VERSION "dbc-export 1 2025.20.8"

NS_ :

BS_:

BU_: ADSP APB APP APS APSB BB BMS CC CMP CMPD CP DAS DI DIF DIR DPB EPAS3P EPAS3S EPASTP EPASTS EPBL EPBR ESP EVSE FC GTW HCML HCMR HVP IBST ICR IDB LS OCS1P PARK PCS PM PMF PMR PNCD PTC RADC RCM RCM2 RCM3 RCU SCCM SCM SCS SDCR TAS TCU TPMS TRCM UI UIS UMC USM VC VCFRONT VCLEFT VCRIGHT VCSEC VEH

BO_ 1297 RCM_alertLog: 8 RCM
 SG_ RCM_alertID M : 0|10@1+ (1,0) [0|1023] "" Vector__XXX
 SG_ RCM_a069_eventDriveOrientation m69 : 14|1@1+ (1,0) [0|1] "" Vector__XXX
 SG_ RCM_a069_comChassisCANPH7MIA m69 : 16|1@1+ (1,0) [0|1] "" Vector__XXX
 SG_ RCM_a069_comChassisCANPH7ChkSm m69 : 17|1@1+ (1,0) [0|1] "" Vector__XXX
 SG_ RCM_a069_comChassisCANPH7Cntr m69 : 18|1@1+ (1,0) [0|1] "" Vector__XXX
 SG_ RCM_a069_eventIDFsignal m69 : 25|1@1+ (1,0) [0|1] "" Vector__XXX
 SG_ RCM_a069_eventFrontLeftSeatbelt m69 : 26|1@1+ (1,0) [0|1] "" Vector__XXX
 SG_ RCM_a069_eventFrontRightSeatbelt m69 : 27|1@1+ (1,0) [0|1] "" Vector__XXX
 SG_ RCM_a069_eventVehicleSpeed m69 : 28|12@1+ (0.08,-40) [-40|287.6] "kph" Vector__XXX
 SG_ RCM_a069_eventSteeringAngle m69 : 45|14@0+ (0.1,-819.2) [-819.2|819.1] "deg" Vector__XXX
 SG_ RCM_a069_eventDriverBrakeApply m69 : 46|2@1+ (1,0) [0|2] "" Vector__XXX
 SG_ RCM_a069_eventAccelPedalPos m69 : 56|8@1+ (0.4,0) [0|101.6] "%" Vector__XXX
 SG_ RCM_a070_eventArmStatus m70 : 11|1@1+ (1,0) [0|1] "" Vector__XXX
 SG_ RCM_a070_eventFactoryMode m70 : 12|1@1+ (1,0) [0|1] "" Vector__XXX
 SG_ RCM_a070_eventDiagEnabled m70 : 13|1@1+ (1,0) [0|1] "" Vector__XXX
 SG_ RCM_a070_eventDriveOrientation m70 : 14|1@1+ (1,0) [0|1] "" Vector__XXX
 SG_ RCM_a070_comChassisCANPH8MIA m70 : 16|1@1+ (1,0) [0|1] "" Vector__XXX
 SG_ RCM_a070_comChassisCANPH8ChkSm m70 : 17|1@1+ (1,0) [0|1] "" Vector__XXX
 SG_ RCM_a070_comChassisCANPH8Cntr m70 : 18|1@1+ (1,0) [0|1] "" Vector__XXX
 SG_ RCM_a070_eventIDFsignal m70 : 25|1@1+ (1,0) [0|1] "" Vector__XXX
 SG_ RCM_a070_eventFrontLeftSeatbelt m70 : 26|1@1+ (1,0) [0|1] "" Vector__XXX
 SG_ RCM_a070_eventFrontRightSeatbelt m70 : 27|1@1+ (1,0) [0|1] "" Vector__XXX
 SG_ RCM_a070_eventVehicleSpeed m70 : 28|12@1+ (0.08,-40) [-40|287.6] "kph" Vector__XXX
 SG_ RCM_a070_eventSteeringAngle m70 : 45|14@0+ (0.1,-819.2) [-819.2|819.1] "deg" Vector__XXX
 SG_ RCM_a070_eventDriverBrakeApply m70 : 46|2@1+ (1,0) [0|2] "" Vector__XXX
 SG_ RCM_a070_eventAccelPedalPos m70 : 56|8@1+ (0.4,0) [0|101.6] "%" Vector__XXX
 SG_ RCM_a071_eventArmStatus m71 : 11|1@1+ (1,0) [0|1] "" Vector__XXX
 SG_ RCM_a071_eventFactoryMode m71 : 12|1@1+ (1,0) [0|1] "" Vector__XXX
 SG_ RCM_a071_eventDiagEnabled m71 : 13|1@1+ (1,0) [0|1] "" Vector__XXX
 SG_ RCM_a071_eventDriveOrientation m71 : 14|1@1+ (1,0) [0|1] "" Vector__XXX
 SG_ RCM_a071_comChassisCANPH9MIA m71 : 16|1@1+ (1,0) [0|1] "" Vector__XXX
 SG_ RCM_a071_comChassisCANPH9ChkSm m71 : 17|1@1+ (1,0) [0|1] "" Vector__XXX
 SG_ RCM_a071_comChassisCANPH9Cntr m71 : 18|1@1+ (1,0) [0|1] "" Vector__XXX
 SG_ RCM_a071_eventIDFsignal m71 : 25|1@1+ (1,0) [0|1] "" Vector__XXX
 SG_ RCM_a071_eventFrontLeftSeatbelt m71 : 26|1@1+ (1,0) [0|1] "" Vector__XXX
 SG_ RCM_a071_eventFrontRightSeatbelt m71 : 27|1@1+ (1,0) [0|1] "" Vector__XXX
 SG_ RCM_a071_eventVehicleSpeed m71 : 28|12@1+ (0.08,-40) [-40|287.6] "kph" Vector__XXX
 SG_ RCM_a071_eventSteeringAngle m71 : 45|14@0+ (0.1,-819.2) [-819.2|819.1] "deg" Vector__XXX
 SG_ RCM_a071_eventDriverBrakeApply m71 : 46|2@1+ (1,0) [0|2] "" Vector__XXX
 SG_ RCM_a071_eventAccelPedalPos m71 : 56|8@1+ (0.4,0) [0|101.6] "%" Vector__XXX
 SG_ RCM_a072_eventArmStatus m72 : 11|1@1+ (1,0) [0|1] "" Vector__XXX
 SG_ RCM_a072_eventFactoryMode m72 : 12|1@1+ (1,0) [0|1] "" Vector__XXX
 SG_ RCM_a072_eventDiagEnabled m72 : 13|1@1+ (1,0) [0|1] "" Vector__XXX
 SG_ RCM_a072_eventDriveOrientation m72 : 14|1@1+ (1,0) [0|1] "" Vector__XXX
 SG_ RCM_a072_comUnusedMIA m72 : 16|1@1+ (1,0) [0|1] "" Vector__XXX
 SG_ RCM_a072_comUnusedChkSm m72 : 17|1@1+ (1,0) [0|1] "" Vector__XXX
 SG_ RCM_a072_comUnusedCntr m72 : 18|1@1+ (1,0) [0|1] "" Vector__XXX
 SG_ RCM_a072_eventIDFsignal m72 : 25|1@1+ (1,0) [0|1] "" Vector__XXX
 SG_ RCM_a072_eventFrontLeftSeatbelt m72 : 26|1@1+ (1,0) [0|1] "" Vector__XXX
 SG_ RCM_a072_eventFrontRightSeatbelt m72 : 27|1@1+ (1,0) [0|1] "" Vector__XXX
 SG_ RCM_a072_eventVehicleSpeed m72 : 28|12@1+ (0.08,-40) [-40|287.6] "kph" Vector__XXX
 SG_ RCM_a072_eventSteeringAngle m72 : 45|14@0+ (0.1,-819.2) [-819.2|819.1] "deg" Vector__XXX
 SG_ RCM_a072_eventDriverBrakeApply m72 : 46|2@1+ (1,0) [0|2] "" Vector__XXX
 SG_ RCM_a072_eventAccelPedalPos m72 : 56|8@1+ (0.4,0) [0|101.6] "%" Vector__XXX
 SG_ RCM_a073_eventArmStatus m73 : 11|1@1+ (1,0) [0|1] "" Vector__XXX
 SG_ RCM_a073_eventFactoryMode m73 : 12|1@1+ (1,0) [0|1] "" Vector__XXX
 SG_ RCM_a073_eventDiagEnabled m73 : 13|1@1+ (1,0) [0|1] "" Vector__XXX
 SG_ RCM_a073_eventDriveOrientation m73 : 14|1@1+ (1,0) [0|1] "" Vector__XXX
 SG_ RCM_a073_comChassisCANPH4MIA m73 : 16|1@1+ (1,0) [0|1] "" Vector__XXX
 SG_ RCM_a073_comChassisCANPH4ChkSm m73 : 17|1@1+ (1,0) [0|1] "" Vector__XXX
 SG_ RCM_a073_comChassisCANPH4Cntr m73 : 18|1@1+ (1,0) [0|1] "" Vector__XXX
 SG_ RCM_a073_eventIDFsignal m73 : 25|1@1+ (1,0) [0|1] "" Vector__XXX
 SG_ RCM_a073_eventFrontLeftSeatbelt m73 : 26|1@1+ (1,0) [0|1] "" Vector__XXX
 SG_ RCM_a073_eventFrontRightSeatbelt m73 : 27|1@1+ (1,0) [0|1] "" Vector__XXX
 SG_ RCM_a073_eventVehicleSpeed m73 : 28|12@1+ (0.08,-40) [-40|287.6] "kph" Vector__XXX
 SG_ RCM_a073_eventSteeringAngle m73 : 45|14@0+ (0.1,-819.2) [-819.2|819.1] "deg" Vector__XXX
 SG_ RCM_a073_eventDriverBrakeApply m73 : 46|2@1+ (1,0) [0|2] "" Vector__XXX
 SG_ RCM_a073_eventAccelPedalPos m73 : 56|8@1+ (0.4,0) [0|101.6] "%" Vector__XXX
 SG_ RCM_a074_eventArmStatus m74 : 11|1@1+ (1,0) [0|1] "" Vector__XXX
 SG_ RCM_a074_eventFactoryMode m74 : 12|1@1+ (1,0) [0|1] "" Vector__XXX
 SG_ RCM_a074_eventDiagEnabled m74 : 13|1@1+ (1,0) [0|1] "" Vector__XXX
 SG_ RCM_a074_eventDriveOrientation m74 : 14|1@1+ (1,0) [0|1] "" Vector__XXX
 SG_ RCM_a074_comChassisCANPH5MIA m74 : 16|1@1+ (1,0) [0|1] "" Vector__XXX
 SG_ RCM_a074_comChassisCANPH5ChkSm m74 : 17|1@1+ (1,0) [0|1] "" Vector__XXX
 SG_ RCM_a074_comChassisCANPH5Cntr m74 : 18|1@1+ (1,0) [0|1] "" Vector__XXX
 SG_ RCM_a074_eventIDFsignal m74 : 25|1@1+ (1,0) [0|1] "" Vector__XXX
 SG_ RCM_a074_eventFrontLeftSeatbelt m74 : 26|1@1+ (1,0) [0|1] "" Vector__XXX
 SG_ RCM_a074_eventFrontRightSeatbelt m74 : 27|1@1+ (1,0) [0|1] "" Vector__XXX
 SG_ RCM_a074_eventVehicleSpeed m74 : 28|12@1+ (0.08,-40) [-40|287.6] "kph" Vector__XXX
 SG_ RCM_a074_eventSteeringAngle m74 : 45|14@0+ (0.1,-819.2) [-819.2|819.1] "deg" Vector__XXX
 SG_ RCM_a074_eventDriverBrakeApply m74 : 46|2@1+ (1,0) [0|2] "" Vector__XXX
 SG_ RCM_a074_eventAccelPedalPos m74 : 56|8@1+ (0.4,0) [0|101.6] "%" Vector__XXX
 SG_ RCM_a075_eventArmStatus m75 : 11|1@1+ (1,0) [0|1] "" Vector__XXX
 SG_ RCM_a075_eventFactoryMode m75 : 12|1@1+ (1,0) [0|1] "" Vector__XXX
 SG_ RCM_a075_eventDiagEnabled m75 : 13|1@1+ (1,0) [0|1] "" Vector__XXX
 SG_ RCM_a075_eventDriveOrientation m75 : 14|1@1+ (1,0) [0|1] "" Vector__XXX
 SG_ RCM_a075_comChassisCANPH6MIA m75 : 16|1@1+ (1,0) [0|1] "" Vector__XXX
 SG_ RCM_a075_comChassisCANPH6ChkSm m75 : 17|1@1+ (1,0) [0|1] "" Vector__XXX
 SG_ RCM_a075_comChassisCANPH6Cntr m75 : 18|1@1+ (1,0) [0|1] "" Vector__XXX
 SG_ RCM_a075_eventIDFsignal m75 : 25|1@1+ (1,0) [0|1] "" Vector__XXX
 SG_ RCM_a075_eventFrontLeftSeatbelt m75 : 26|1@1+ (1,0) [0|1] "" Vector__XXX
 SG_ RCM_a075_eventFrontRightSeatbelt m75 : 27|1@1+ (1,0) [0|1] "" Vector__XXX
 SG_ RCM_a075_eventVehicleSpeed m75 : 28|12@1+ (0.08,-40) [-40|287.6] "kph" Vector__XXX
 SG_ RCM_a075_eventSteeringAngle m75 : 45|14@0+ (0.1,-819.2) [-819.2|819.1] "deg" Vector__XXX
 SG_ RCM_a075_eventDriverBrakeApply m75 : 46|2@1+ (1,0) [0|2] "" Vector__XXX
 SG_ RCM_a075_eventAccelPedalPos m75 : 56|8@1+ (0.4,0) [0|101.6] "%" Vector__XXX
 SG_ RCM_a078_eventArmStatus m78 : 11|1@1+ (1,0) [0|1] "" Vector__XXX
 SG_ RCM_a078_eventFactoryMode m78 : 12|1@1+ (1,0) [0|1] "" Vector__XXX
 SG_ RCM_a078_eventDiagEnabled m78 : 13|1@1+ (1,0) [0|1] "" Vector__XXX
 SG_ RCM_a078_eventDriveOrientation m78 : 14|1@1+ (1,0) [0|1] "" Vector__XXX
 SG_ RCM_a078_comOCS1PMIA m78 : 16|1@1+ (1,0) [0|1] "" Vector__XXX
 SG_ RCM_a078_comOCS1PChkSm m78 : 17|1@1+ (1,0) [0|1] "" Vector__XXX
 SG_ RCM_a078_comOCS1PCntr m78 : 18|1@1+ (1,0) [0|1] "" Vector__XXX
 SG_ RCM_a078_eventIDFsignal m78 : 25|1@1+ (1,0) [0|1] "" Vector__XXX
 SG_ RCM_a078_eventFrontLeftSeatbelt m78 : 26|1@1+ (1,0) [0|1] "" Vector__XXX
 SG_ RCM_a078_eventFrontRightSeatbelt m78 : 27|1@1+ (1,0) [0|1] "" Vector__XXX
 SG_ RCM_a078_eventVehicleSpeed m78 : 28|12@1+ (0.08,-40) [-40|287.6] "kph" Vector__XXX
 SG_ RCM_a078_eventSteeringAngle m78 : 45|14@0+ (0.1,-819.2) [-819.2|819.1] "deg" Vector__XXX
 SG_ RCM_a078_eventDriverBrakeApply m78 : 46|2@1+ (1,0) [0|2] "" Vector__XXX
 SG_ RCM_a078_eventAccelPedalPos m78 : 56|8@1+ (0.4,0) [0|101.6] "%" Vector__XXX
 SG_ RCM_a079_eventArmStatus m79 : 11|1@1+ (1,0) [0|1] "" Vector__XXX
 SG_ RCM_a079_eventFactoryMode m79 : 12|1@1+ (1,0) [0|1] "" Vector__XXX
 SG_ RCM_a079_eventDiagEnabled m79 : 13|1@1+ (1,0) [0|1] "" Vector__XXX
 SG_ RCM_a079_eventDriveOrientation m79 : 14|1@1+ (1,0) [0|1] "" Vector__XXX
 SG_ RCM_a079_comOCS1DMIA m79 : 16|1@1+ (1,0) [0|1] "" Vector__XXX
 SG_ RCM_a079_comOCS1DChkSm m79 : 17|1@1+ (1,0) [0|1] "" Vector__XXX
 SG_ RCM_a079_comOCS1DCntr m79 : 18|1@1+ (1,0) [0|1] "" Vector__XXX
 SG_ RCM_a079_eventIDFsignal m79 : 25|1@1+ (1,0) [0|1] "" Vector__XXX
 SG_ RCM_a079_eventFrontLeftSeatbelt m79 : 26|1@1+ (1,0) [0|1] "" Vector__XXX
 SG_ RCM_a079_eventFrontRightSeatbelt m79 : 27|1@1+ (1,0) [0|1] "" Vector__XXX
 SG_ RCM_a079_eventVehicleSpeed m79 : 28|12@1+ (0.08,-40) [-40|287.6] "kph" Vector__XXX
 SG_ RCM_a079_eventSteeringAngle m79 : 45|14@0+ (0.1,-819.2) [-819.2|819.1] "deg" Vector__XXX
 SG_ RCM_a079_eventDriverBrakeApply m79 : 46|2@1+ (1,0) [0|2] "" Vector__XXX
 SG_ RCM_a079_eventAccelPedalPos m79 : 56|8@1+ (0.4,0) [0|101.6] "%" Vector__XXX
 SG_ RCM_a080_eventArmStatus m80 : 11|1@1+ (1,0) [0|1] "" Vector__XXX
 SG_ RCM_a080_eventFactoryMode m80 : 12|1@1+ (1,0) [0|1] "" Vector__XXX
 SG_ RCM_a080_eventDiagEnabled m80 : 13|1@1+ (1,0) [0|1] "" Vector__XXX
 SG_ RCM_a080_eventDriveOrientation m80 : 14|1@1+ (1,0) [0|1] "" Vector__XXX
 SG_ RCM_a080_comGTWACSMIA m80 : 16|1@1+ (1,0) [0|1] "" Vector__XXX
 SG_ RCM_a080_comGTWACSChkSm m80 : 17|1@1+ (1,0) [0|1] "" Vector__XXX
 SG_ RCM_a080_comGTWACSCntr m80 : 18|1@1+ (1,0) [0|1] "" Vector__XXX
 SG_ RCM_a080_eventIDFsignal m80 : 25|1@1+ (1,0) [0|1] "" Vector__XXX
 SG_ RCM_a080_eventFrontLeftSeatbelt m80 : 26|1@1+ (1,0) [0|1] "" Vector__XXX
 SG_ RCM_a080_eventFrontRightSeatbelt m80 : 27|1@1+ (1,0) [0|1] "" Vector__XXX
 SG_ RCM_a080_eventVehicleSpeed m80 : 28|12@1+ (0.08,-40) [-40|287.6] "kph" Vector__XXX
 SG_ RCM_a080_eventSteeringAngle m80 : 45|14@0+ (0.1,-819.2) [-819.2|819.1] "deg" Vector__XXX
 SG_ RCM_a080_eventDriverBrakeApply m80 : 46|2@1+ (1,0) [0|2] "" Vector__XXX
 SG_ RCM_a080_eventAccelPedalPos m80 : 56|8@1+ (0.4,0) [0|101.6] "%" Vector__XXX
 SG_ RCM_a083_eventArmStatus m83 : 11|1@1+ (1,0) [0|1] "" Vector__XXX
 SG_ RCM_a083_eventFactoryMode m83 : 12|1@1+ (1,0) [0|1] "" Vector__XXX
 SG_ RCM_a083_eventDiagEnabled m83 : 13|1@1+ (1,0) [0|1] "" Vector__XXX
 SG_ RCM_a083_eventDriveOrientation m83 : 14|1@1+ (1,0) [0|1] "" Vector__XXX
 SG_ RCM_a083_comGTWCarStateMIA m83 : 16|1@1+ (1,0) [0|1] "" Vector__XXX
 SG_ RCM_a083_eventIDFsignal m83 : 25|1@1+ (1,0) [0|1] "" Vector__XXX
 SG_ RCM_a083_eventFrontLeftSeatbelt m83 : 26|1@1+ (1,0) [0|1] "" Vector__XXX
 SG_ RCM_a083_eventFrontRightSeatbelt m83 : 27|1@1+ (1,0) [0|1] "" Vector__XXX
 SG_ RCM_a083_eventVehicleSpeed m83 : 28|12@1+ (0.08,-40) [-40|287.6] "kph" Vector__XXX
 SG_ RCM_a083_eventSteeringAngle m83 : 45|14@0+ (0.1,-819.2) [-819.2|819.1] "deg" Vector__XXX
 SG_ RCM_a083_eventDriverBrakeApply m83 : 46|2@1+ (1,0) [0|2] "" Vector__XXX
 SG_ RCM_a083_eventAccelPedalPos m83 : 56|8@1+ (0.4,0) [0|101.6] "%" Vector__XXX
 SG_ RCM_a087_eventArmStatus m87 : 11|1@1+ (1,0) [0|1] "" Vector__XXX
 SG_ RCM_a087_eventFactoryMode m87 : 12|1@1+ (1,0) [0|1] "" Vector__XXX
 SG_ RCM_a087_eventDiagEnabled m87 : 13|1@1+ (1,0) [0|1] "" Vector__XXX
 SG_ RCM_a087_eventDriveOrientation m87 : 14|1@1+ (1,0) [0|1] "" Vector__XXX
 SG_ RCM_a087_comChassisCANSilent m87 : 16|1@1+ (1,0) [0|1] "" Vector__XXX
 SG_ RCM_a087_comPARTYCANSilent m87 : 17|1@1+ (1,0) [0|1] "" Vector__XXX
 SG_ RCM_a087_comUnusedCANSilent m87 : 18|1@1+ (1,0) [0|1] "" Vector__XXX
 SG_ RCM_a087_eventIDFsignal m87 : 25|1@1+ (1,0) [0|1] "" Vector__XXX
 SG_ RCM_a087_eventFrontLeftSeatbelt m87 : 26|1@1+ (1,0) [0|1] "" Vector__XXX
 SG_ RCM_a087_eventFrontRightSeatbelt m87 : 27|1@1+ (1,0) [0|1] "" Vector__XXX
 SG_ RCM_a087_eventVehicleSpeed m87 : 28|12@1+ (0.08,-40) [-40|287.6] "kph" Vector__XXX
 SG_ RCM_a087_eventSteeringAngle m87 : 45|14@0+ (0.1,-819.2) [-819.2|819.1] "deg" Vector__XXX
 SG_ RCM_a087_eventDriverBrakeApply m87 : 46|2@1+ (1,0) [0|2] "" Vector__XXX
 SG_ RCM_a087_eventAccelPedalPos m87 : 56|8@1+ (0.4,0) [0|101.6] "%" Vector__XXX
 SG_ RCM_a088_eventArmStatus m88 : 11|1@1+ (1,0) [0|1] "" Vector__XXX
 SG_ RCM_a088_eventFactoryMode m88 : 12|1@1+ (1,0) [0|1] "" Vector__XXX
 SG_ RCM_a088_eventDiagEnabled m88 : 13|1@1+ (1,0) [0|1] "" Vector__XXX
 SG_ RCM_a088_eventDriveOrientation m88 : 14|1@1+ (1,0) [0|1] "" Vector__XXX
 SG_ RCM_a088_comChassisCANPH2MIA m88 : 16|1@1+ (1,0) [0|1] "" Vector__XXX
 SG_ RCM_a088_comChassisCANPH2ChkSm m88 : 17|1@1+ (1,0) [0|1] "" Vector__XXX
 SG_ RCM_a088_comChassisCANPH2Cntr m88 : 18|1@1+ (1,0) [0|1] "" Vector__XXX
 SG_ RCM_a088_eventIDFsignal m88 : 25|1@1+ (1,0) [0|1] "" Vector__XXX
 SG_ RCM_a088_eventFrontLeftSeatbelt m88 : 26|1@1+ (1,0) [0|1] "" Vector__XXX
 SG_ RCM_a088_eventFrontRightSeatbelt m88 : 27|1@1+ (1,0) [0|1] "" Vector__XXX
 SG_ RCM_a088_eventVehicleSpeed m88 : 28|12@1+ (0.08,-40) [-40|287.6] "kph" Vector__XXX
 SG_ RCM_a088_eventSteeringAngle m88 : 45|14@0+ (0.1,-819.2) [-819.2|819.1] "deg" Vector__XXX
 SG_ RCM_a088_eventDriverBrakeApply m88 : 46|2@1+ (1,0) [0|2] "" Vector__XXX
 SG_ RCM_a088_eventAccelPedalPos m88 : 56|8@1+ (0.4,0) [0|101.6] "%" Vector__XXX
 SG_ RCM_a089_eventArmStatus m89 : 11|1@1+ (1,0) [0|1] "" Vector__XXX
 SG_ RCM_a089_eventFactoryMode m89 : 12|1@1+ (1,0) [0|1] "" Vector__XXX
 SG_ RCM_a089_eventDiagEnabled m89 : 13|1@1+ (1,0) [0|1] "" Vector__XXX
 SG_ RCM_a089_eventDriveOrientation m89 : 14|1@1+ (1,0) [0|1] "" Vector__XXX
 SG_ RCM_a089_comChassisCANPH3MIA m89 : 16|1@1+ (1,0) [0|1] "" Vector__XXX
 SG_ RCM_a089_comChassisCANPH3ChkSm m89 : 17|1@1+ (1,0) [0|1] "" Vector__XXX
 SG_ RCM_a089_comChassisCANPH3Cntr m89 : 18|1@1+ (1,0) [0|1] "" Vector__XXX
 SG_ RCM_a089_eventIDFsignal m89 : 25|1@1+ (1,0) [0|1] "" Vector__XXX
 SG_ RCM_a089_eventFrontLeftSeatbelt m89 : 26|1@1+ (1,0) [0|1] "" Vector__XXX
 SG_ RCM_a089_eventFrontRightSeatbelt m89 : 27|1@1+ (1,0) [0|1] "" Vector__XXX
 SG_ RCM_a089_eventVehicleSpeed m89 : 28|12@1+ (0.08,-40) [-40|287.6] "kph" Vector__XXX
 SG_ RCM_a089_eventSteeringAngle m89 : 45|14@0+ (0.1,-819.2) [-819.2|819.1] "deg" Vector__XXX
 SG_ RCM_a089_eventDriverBrakeApply m89 : 46|2@1+ (1,0) [0|2] "" Vector__XXX
 SG_ RCM_a089_eventAccelPedalPos m89 : 56|8@1+ (0.4,0) [0|101.6] "%" Vector__XXX
 SG_ RCM_a090_eventArmStatus m90 : 11|1@1+ (1,0) [0|1] "" Vector__XXX
 SG_ RCM_a090_eventFactoryMode m90 : 12|1@1+ (1,0) [0|1] "" Vector__XXX
 SG_ RCM_a090_eventDiagEnabled m90 : 13|1@1+ (1,0) [0|1] "" Vector__XXX
 SG_ RCM_a090_eventDriveOrientation m90 : 14|1@1+ (1,0) [0|1] "" Vector__XXX
 SG_ RCM_a090_comPartyCANBusOff m90 : 16|1@1+ (1,0) [0|1] "" Vector__XXX
 SG_ RCM_a090_eventIDFsignal m90 : 25|1@1+ (1,0) [0|1] "" Vector__XXX
 SG_ RCM_a090_eventFrontLeftSeatbelt m90 : 26|1@1+ (1,0) [0|1] "" Vector__XXX
 SG_ RCM_a090_eventFrontRightSeatbelt m90 : 27|1@1+ (1,0) [0|1] "" Vector__XXX
 SG_ RCM_a090_eventVehicleSpeed m90 : 28|12@1+ (0.08,-40) [-40|287.6] "kph" Vector__XXX
 SG_ RCM_a090_eventSteeringAngle m90 : 45|14@0+ (0.1,-819.2) [-819.2|819.1] "deg" Vector__XXX
 SG_ RCM_a090_eventDriverBrakeApply m90 : 46|2@1+ (1,0) [0|2] "" Vector__XXX
 SG_ RCM_a090_eventAccelPedalPos m90 : 56|8@1+ (0.4,0) [0|101.6] "%" Vector__XXX
 SG_ RCM_a091_eventArmStatus m91 : 11|1@1+ (1,0) [0|1] "" Vector__XXX
 SG_ RCM_a091_eventFactoryMode m91 : 12|1@1+ (1,0) [0|1] "" Vector__XXX
 SG_ RCM_a091_eventDiagEnabled m91 : 13|1@1+ (1,0) [0|1] "" Vector__XXX
 SG_ RCM_a091_eventDriveOrientation m91 : 14|1@1+ (1,0) [0|1] "" Vector__XXX
 SG_ RCM_a091_comEPAS3PStAnglInvlidQF m91 : 16|1@1+ (1,0) [0|1] "" Vector__XXX
 SG_ RCM_a091_comEPAS3PsysStatusMIA m91 : 17|1@1+ (1,0) [0|1] "" Vector__XXX
 SG_ RCM_a091_comEPAS3PsysStatusChkSm m91 : 18|1@1+ (1,0) [0|1] "" Vector__XXX
 SG_ RCM_a091_comEPAS3PsysStatusCntr m91 : 19|1@1+ (1,0) [0|1] "" Vector__XXX
 SG_ RCM_a091_eventIDFsignal m91 : 25|1@1+ (1,0) [0|1] "" Vector__XXX
 SG_ RCM_a091_eventFrontLeftSeatbelt m91 : 26|1@1+ (1,0) [0|1] "" Vector__XXX
 SG_ RCM_a091_eventFrontRightSeatbelt m91 : 27|1@1+ (1,0) [0|1] "" Vector__XXX
 SG_ RCM_a091_eventVehicleSpeed m91 : 28|12@1+ (0.08,-40) [-40|287.6] "kph" Vector__XXX
 SG_ RCM_a091_eventSteeringAngle m91 : 45|14@0+ (0.1,-819.2) [-819.2|819.1] "deg" Vector__XXX
 SG_ RCM_a091_eventDriverBrakeApply m91 : 46|2@1+ (1,0) [0|2] "" Vector__XXX
 SG_ RCM_a091_eventAccelPedalPos m91 : 56|8@1+ (0.4,0) [0|101.6] "%" Vector__XXX
 SG_ RCM_a092_eventArmStatus m92 : 11|1@1+ (1,0) [0|1] "" Vector__XXX
 SG_ RCM_a092_eventFactoryMode m92 : 12|1@1+ (1,0) [0|1] "" Vector__XXX
 SG_ RCM_a092_eventDiagEnabled m92 : 13|1@1+ (1,0) [0|1] "" Vector__XXX
 SG_ RCM_a092_eventDriveOrientation m92 : 14|1@1+ (1,0) [0|1] "" Vector__XXX
 SG_ RCM_a092_comDASSafetyFrontMIA m92 : 16|1@1+ (1,0) [0|1] "" Vector__XXX
 SG_ RCM_a092_comDASSafetyFrontChkSm m92 : 17|1@1+ (1,0) [0|1] "" Vector__XXX
 SG_ RCM_a092_comDASSafetyFrontCntr m92 : 18|1@1+ (1,0) [0|1] "" Vector__XXX
 SG_ RCM_a092_eventIDFsignal m92 : 25|1@1+ (1,0) [0|1] "" Vector__XXX
 SG_ RCM_a092_eventFrontLeftSeatbelt m92 : 26|1@1+ (1,0) [0|1] "" Vector__XXX
 SG_ RCM_a092_eventFrontRightSeatbelt m92 : 27|1@1+ (1,0) [0|1] "" Vector__XXX
 SG_ RCM_a092_eventVehicleSpeed m92 : 28|12@1+ (0.08,-40) [-40|287.6] "kph" Vector__XXX
 SG_ RCM_a092_eventSteeringAngle m92 : 45|14@0+ (0.1,-819.2) [-819.2|819.1] "deg" Vector__XXX
 SG_ RCM_a092_eventDriverBrakeApply m92 : 46|2@1+ (1,0) [0|2] "" Vector__XXX
 SG_ RCM_a092_eventAccelPedalPos m92 : 56|8@1+ (0.4,0) [0|101.6] "%" Vector__XXX
 SG_ RCM_a093_eventArmStatus m93 : 11|1@1+ (1,0) [0|1] "" Vector__XXX
 SG_ RCM_a093_eventFactoryMode m93 : 12|1@1+ (1,0) [0|1] "" Vector__XXX
 SG_ RCM_a093_eventDiagEnabled m93 : 13|1@1+ (1,0) [0|1] "" Vector__XXX
 SG_ RCM_a093_eventDriveOrientation m93 : 14|1@1+ (1,0) [0|1] "" Vector__XXX
 SG_ RCM_a093_comVCLEFTStatusMIA m93 : 16|1@1+ (1,0) [0|1] "" Vector__XXX
 SG_ RCM_a093_comVCLEFTStatusChkSm m93 : 17|1@1+ (1,0) [0|1] "" Vector__XXX
 SG_ RCM_a093_comVCLEFTStatusCntr m93 : 18|1@1+ (1,0) [0|1] "" Vector__XXX
 SG_ RCM_a093_bucklSwVCFrontLeftFault m93 : 19|1@1+ (1,0) [0|1] "" Vector__XXX
 SG_ RCM_a093_bucklSwVCRearLeftFault m93 : 20|1@1+ (1,0) [0|1] "" Vector__XXX
 SG_ RCM_a093_eventIDFsignal m93 : 25|1@1+ (1,0) [0|1] "" Vector__XXX
 SG_ RCM_a093_eventFrontLeftSeatbelt m93 : 26|1@1+ (1,0) [0|1] "" Vector__XXX
 SG_ RCM_a093_eventFrontRightSeatbelt m93 : 27|1@1+ (1,0) [0|1] "" Vector__XXX
 SG_ RCM_a093_eventVehicleSpeed m93 : 28|12@1+ (0.08,-40) [-40|287.6] "kph" Vector__XXX
 SG_ RCM_a093_eventSteeringAngle m93 : 45|14@0+ (0.1,-819.2) [-819.2|819.1] "deg" Vector__XXX
 SG_ RCM_a093_eventDriverBrakeApply m93 : 46|2@1+ (1,0) [0|2] "" Vector__XXX
 SG_ RCM_a093_eventAccelPedalPos m93 : 56|8@1+ (0.4,0) [0|101.6] "%" Vector__XXX
 SG_ RCM_a094_eventArmStatus m94 : 11|1@1+ (1,0) [0|1] "" Vector__XXX
 SG_ RCM_a094_eventFactoryMode m94 : 12|1@1+ (1,0) [0|1] "" Vector__XXX
 SG_ RCM_a094_eventDiagEnabled m94 : 13|1@1+ (1,0) [0|1] "" Vector__XXX
 SG_ RCM_a094_eventDriveOrientation m94 : 14|1@1+ (1,0) [0|1] "" Vector__XXX
 SG_ RCM_a094_comVCRIGHTStatusMIA m94 : 16|1@1+ (1,0) [0|1] "" Vector__XXX
 SG_ RCM_a094_comVCRIGHTStatusChkSm m94 : 17|1@1+ (1,0) [0|1] "" Vector__XXX
 SG_ RCM_a094_comVCRIGHTStatusCntr m94 : 18|1@1+ (1,0) [0|1] "" Vector__XXX
 SG_ RCM_a094_bucklSwVCFrontRghtFault m94 : 19|1@1+ (1,0) [0|1] "" Vector__XXX
 SG_ RCM_a094_bucklSwVCRearRghtFault m94 : 20|1@1+ (1,0) [0|1] "" Vector__XXX
 SG_ RCM_a094_bucklSwVCRearCnterFault m94 : 21|1@1+ (1,0) [0|1] "" Vector__XXX
 SG_ RCM_a094_eventIDFsignal m94 : 25|1@1+ (1,0) [0|1] "" Vector__XXX
 SG_ RCM_a094_eventFrontLeftSeatbelt m94 : 26|1@1+ (1,0) [0|1] "" Vector__XXX
 SG_ RCM_a094_eventFrontRightSeatbelt m94 : 27|1@1+ (1,0) [0|1] "" Vector__XXX
 SG_ RCM_a094_eventVehicleSpeed m94 : 28|12@1+ (0.08,-40) [-40|287.6] "kph" Vector__XXX
 SG_ RCM_a094_eventSteeringAngle m94 : 45|14@0+ (0.1,-819.2) [-819.2|819.1] "deg" Vector__XXX
 SG_ RCM_a094_eventDriverBrakeApply m94 : 46|2@1+ (1,0) [0|2] "" Vector__XXX
 SG_ RCM_a094_eventAccelPedalPos m94 : 56|8@1+ (0.4,0) [0|101.6] "%" Vector__XXX
 SG_ RCM_a101_eventArmStatus m101 : 11|1@1+ (1,0) [0|1] "" Vector__XXX
 SG_ RCM_a101_eventFactoryMode m101 : 12|1@1+ (1,0) [0|1] "" Vector__XXX
 SG_ RCM_a101_eventDiagEnabled m101 : 13|1@1+ (1,0) [0|1] "" Vector__XXX
 SG_ RCM_a101_eventDriveOrientation m101 : 14|1@1+ (1,0) [0|1] "" Vector__XXX
 SG_ RCM_a101_idfMisuseMonitoringErr m101 : 16|1@1+ (1,0) [0|1] "" Vector__XXX
 SG_ RCM_a101_idfEnviMonitoringError m101 : 17|1@1+ (1,0) [0|1] "" Vector__XXX
 SG_ RCM_a101_idfEnviMonitoringEvent m101 : 18|1@1+ (1,0) [0|1] "" Vector__XXX
 SG_ RCM_a101_eventIDFsignal m101 : 25|1@1+ (1,0) [0|1] "" Vector__XXX
 SG_ RCM_a101_eventFrontLeftSeatbelt m101 : 26|1@1+ (1,0) [0|1] "" Vector__XXX
 SG_ RCM_a101_eventFrontRightSeatbelt m101 : 27|1@1+ (1,0) [0|1] "" Vector__XXX
 SG_ RCM_a101_eventVehicleSpeed m101 : 28|12@1+ (0.08,-40) [-40|287.6] "kph" Vector__XXX
 SG_ RCM_a101_eventSteeringAngle m101 : 45|14@0+ (0.1,-819.2) [-819.2|819.1] "deg" Vector__XXX
 SG_ RCM_a101_eventDriverBrakeApply m101 : 46|2@1+ (1,0) [0|2] "" Vector__XXX
 SG_ RCM_a101_eventAccelPedalPos m101 : 56|8@1+ (0.4,0) [0|101.6] "%" Vector__XXX
 SG_ RCM_a102_eventArmStatus m102 : 11|1@1+ (1,0) [0|1] "" Vector__XXX
 SG_ RCM_a102_eventFactoryMode m102 : 12|1@1+ (1,0) [0|1] "" Vector__XXX
 SG_ RCM_a102_eventDiagEnabled m102 : 13|1@1+ (1,0) [0|1] "" Vector__XXX
 SG_ RCM_a102_eventDriveOrientation m102 : 14|1@1+ (1,0) [0|1] "" Vector__XXX
 SG_ RCM_a102_imuYawR8OffCompPosLife m102 : 16|1@1+ (1,0) [0|1] "" Vector__XXX
 SG_ RCM_a102_imuYawR8OffCompNegLife m102 : 17|1@1+ (1,0) [0|1] "" Vector__XXX
 SG_ RCM_a102_imuYawR8OffCompPosFLDC m102 : 18|1@1+ (1,0) [0|1] "" Vector__XXX
 SG_ RCM_a102_imuYawR8OffCompNegFLDC m102 : 19|1@1+ (1,0) [0|1] "" Vector__XXX
 SG_ RCM_a102_imuYawR8OffCompPosSLDC m102 : 20|1@1+ (1,0) [0|1] "" Vector__XXX
 SG_ RCM_a102_imuYawR8OffCompNegSLDC m102 : 21|1@1+ (1,0) [0|1] "" Vector__XXX
 SG_ RCM_a102_eventIDFsignal m102 : 25|1@1+ (1,0) [0|1] "" Vector__XXX
 SG_ RCM_a102_eventFrontLeftSeatbelt m102 : 26|1@1+ (1,0) [0|1] "" Vector__XXX
 SG_ RCM_a102_eventFrontRightSeatbelt m102 : 27|1@1+ (1,0) [0|1] "" Vector__XXX
 SG_ RCM_a102_eventVehicleSpeed m102 : 28|12@1+ (0.08,-40) [-40|287.6] "kph" Vector__XXX
 SG_ RCM_a102_eventSteeringAngle m102 : 45|14@0+ (0.1,-819.2) [-819.2|819.1] "deg" Vector__XXX
 SG_ RCM_a102_eventDriverBrakeApply m102 : 46|2@1+ (1,0) [0|2] "" Vector__XXX
 SG_ RCM_a102_eventAccelPedalPos m102 : 56|8@1+ (0.4,0) [0|101.6] "%" Vector__XXX
 SG_ RCM_a103_eventArmStatus m103 : 11|1@1+ (1,0) [0|1] "" Vector__XXX
 SG_ RCM_a103_eventFactoryMode m103 : 12|1@1+ (1,0) [0|1] "" Vector__XXX
 SG_ RCM_a103_eventDiagEnabled m103 : 13|1@1+ (1,0) [0|1] "" Vector__XXX
 SG_ RCM_a103_eventDriveOrientation m103 : 14|1@1+ (1,0) [0|1] "" Vector__XXX
 SG_ RCM_a103_imuPtchR8OffCompPosLife m103 : 16|1@1+ (1,0) [0|1] "" Vector__XXX
 SG_ RCM_a103_imuPtchR8OffCompNegLife m103 : 17|1@1+ (1,0) [0|1] "" Vector__XXX
 SG_ RCM_a103_imuPtchR8OffCompPosFLDC m103 : 18|1@1+ (1,0) [0|1] "" Vector__XXX
 SG_ RCM_a103_imuPtchR8OffCompNegFLDC m103 : 19|1@1+ (1,0) [0|1] "" Vector__XXX
 SG_ RCM_a103_imuPtchR8OffCompPosSLDC m103 : 20|1@1+ (1,0) [0|1] "" Vector__XXX
 SG_ RCM_a103_imuPtchR8OffCompNegSLDC m103 : 21|1@1+ (1,0) [0|1] "" Vector__XXX
 SG_ RCM_a103_eventIDFsignal m103 : 25|1@1+ (1,0) [0|1] "" Vector__XXX
 SG_ RCM_a103_eventFrontLeftSeatbelt m103 : 26|1@1+ (1,0) [0|1] "" Vector__XXX
 SG_ RCM_a103_eventFrontRightSeatbelt m103 : 27|1@1+ (1,0) [0|1] "" Vector__XXX
 SG_ RCM_a103_eventVehicleSpeed m103 : 28|12@1+ (0.08,-40) [-40|287.6] "kph" Vector__XXX
 SG_ RCM_a103_eventSteeringAngle m103 : 45|14@0+ (0.1,-819.2) [-819.2|819.1] "deg" Vector__XXX
 SG_ RCM_a103_eventDriverBrakeApply m103 : 46|2@1+ (1,0) [0|2] "" Vector__XXX
 SG_ RCM_a103_eventAccelPedalPos m103 : 56|8@1+ (0.4,0) [0|101.6] "%" Vector__XXX
 SG_ RCM_a104_eventArmStatus m104 : 11|1@1+ (1,0) [0|1] "" Vector__XXX
 SG_ RCM_a104_eventFactoryMode m104 : 12|1@1+ (1,0) [0|1] "" Vector__XXX
 SG_ RCM_a104_eventDiagEnabled m104 : 13|1@1+ (1,0) [0|1] "" Vector__XXX
 SG_ RCM_a104_eventDriveOrientation m104 : 14|1@1+ (1,0) [0|1] "" Vector__XXX
 SG_ RCM_a104_imuRollR8OffCompPosLife m104 : 16|1@1+ (1,0) [0|1] "" Vector__XXX
 SG_ RCM_a104_imuRollR8OffCompNegLife m104 : 17|1@1+ (1,0) [0|1] "" Vector__XXX
 SG_ RCM_a104_imuRollR8OffCompPosFLDC m104 : 18|1@1+ (1,0) [0|1] "" Vector__XXX
 SG_ RCM_a104_imuRollR8OffCompNegFLDC m104 : 19|1@1+ (1,0) [0|1] "" Vector__XXX
 SG_ RCM_a104_imuRollR8OffCompPosSLDC m104 : 20|1@1+ (1,0) [0|1] "" Vector__XXX
 SG_ RCM_a104_imuRollR8OffCompNegSLDC m104 : 21|1@1+ (1,0) [0|1] "" Vector__XXX
 SG_ RCM_a104_eventIDFsignal m104 : 25|1@1+ (1,0) [0|1] "" Vector__XXX
 SG_ RCM_a104_eventFrontLeftSeatbelt m104 : 26|1@1+ (1,0) [0|1] "" Vector__XXX
 SG_ RCM_a104_eventFrontRightSeatbelt m104 : 27|1@1+ (1,0) [0|1] "" Vector__XXX
 SG_ RCM_a104_eventVehicleSpeed m104 : 28|12@1+ (0.08,-40) [-40|287.6] "kph" Vector__XXX
 SG_ RCM_a104_eventSteeringAngle m104 : 45|14@0+ (0.1,-819.2) [-819.2|819.1] "deg" Vector__XXX
 SG_ RCM_a104_eventDriverBrakeApply m104 : 46|2@1+ (1,0) [0|2] "" Vector__XXX
 SG_ RCM_a104_eventAccelPedalPos m104 : 56|8@1+ (0.4,0) [0|101.6] "%" Vector__XXX
 SG_ RCM_a105_eventArmStatus m105 : 11|1@1+ (1,0) [0|1] "" Vector__XXX
 SG_ RCM_a105_eventFactoryMode m105 : 12|1@1+ (1,0) [0|1] "" Vector__XXX
 SG_ RCM_a105_eventDiagEnabled m105 : 13|1@1+ (1,0) [0|1] "" Vector__XXX
 SG_ RCM_a105_eventDriveOrientation m105 : 14|1@1+ (1,0) [0|1] "" Vector__XXX
 SG_ RCM_a105_imuLongAOffCompPosLife m105 : 16|1@1+ (1,0) [0|1] "" Vector__XXX
 SG_ RCM_a105_imuLongAOffCompNegLife m105 : 17|1@1+ (1,0) [0|1] "" Vector__XXX
 SG_ RCM_a105_imuLongAOffCompPosFLDC m105 : 18|1@1+ (1,0) [0|1] "" Vector__XXX
 SG_ RCM_a105_imuLongAOffCompNegFLDC m105 : 19|1@1+ (1,0) [0|1] "" Vector__XXX
 SG_ RCM_a105_imuLongAOffCompPosSLDC m105 : 20|1@1+ (1,0) [0|1] "" Vector__XXX
 SG_ RCM_a105_imuLongAOffCompNegSLDC m105 : 21|1@1+ (1,0) [0|1] "" Vector__XXX
 SG_ RCM_a105_eventIDFsignal m105 : 25|1@1+ (1,0) [0|1] "" Vector__XXX
 SG_ RCM_a105_eventFrontLeftSeatbelt m105 : 26|1@1+ (1,0) [0|1] "" Vector__XXX
 SG_ RCM_a105_eventFrontRightSeatbelt m105 : 27|1@1+ (1,0) [0|1] "" Vector__XXX
 SG_ RCM_a105_eventVehicleSpeed m105 : 28|12@1+ (0.08,-40) [-40|287.6] "kph" Vector__XXX
 SG_ RCM_a105_eventSteeringAngle m105 : 45|14@0+ (0.1,-819.2) [-819.2|819.1] "deg" Vector__XXX
 SG_ RCM_a105_eventDriverBrakeApply m105 : 46|2@1+ (1,0) [0|2] "" Vector__XXX
 SG_ RCM_a105_eventAccelPedalPos m105 : 56|8@1+ (0.4,0) [0|101.6] "%" Vector__XXX
 SG_ RCM_a106_eventArmStatus m106 : 11|1@1+ (1,0) [0|1] "" Vector__XXX
 SG_ RCM_a106_eventFactoryMode m106 : 12|1@1+ (1,0) [0|1] "" Vector__XXX
 SG_ RCM_a106_eventDiagEnabled m106 : 13|1@1+ (1,0) [0|1] "" Vector__XXX
 SG_ RCM_a106_eventDriveOrientation m106 : 14|1@1+ (1,0) [0|1] "" Vector__XXX
 SG_ RCM_a106_imuLatAcOffCompPosLife m106 : 16|1@1+ (1,0) [0|1] "" Vector__XXX
 SG_ RCM_a106_imuLatAcOffCompNegLife m106 : 17|1@1+ (1,0) [0|1] "" Vector__XXX
 SG_ RCM_a106_imuLatAcOffCompPosFLDC m106 : 18|1@1+ (1,0) [0|1] "" Vector__XXX
 SG_ RCM_a106_imuLatAcOffCompNegFLDC m106 : 19|1@1+ (1,0) [0|1] "" Vector__XXX
 SG_ RCM_a106_imuLatAcOffCompPosSLDC m106 : 20|1@1+ (1,0) [0|1] "" Vector__XXX
 SG_ RCM_a106_imuLatAcOffCompNegSLDC m106 : 21|1@1+ (1,0) [0|1] "" Vector__XXX
 SG_ RCM_a106_eventIDFsignal m106 : 25|1@1+ (1,0) [0|1] "" Vector__XXX
 SG_ RCM_a106_eventFrontLeftSeatbelt m106 : 26|1@1+ (1,0) [0|1] "" Vector__XXX
 SG_ RCM_a106_eventFrontRightSeatbelt m106 : 27|1@1+ (1,0) [0|1] "" Vector__XXX
 SG_ RCM_a106_eventVehicleSpeed m106 : 28|12@1+ (0.08,-40) [-40|287.6] "kph" Vector__XXX
 SG_ RCM_a106_eventSteeringAngle m106 : 45|14@0+ (0.1,-819.2) [-819.2|819.1] "deg" Vector__XXX
 SG_ RCM_a106_eventDriverBrakeApply m106 : 46|2@1+ (1,0) [0|2] "" Vector__XXX
 SG_ RCM_a106_eventAccelPedalPos m106 : 56|8@1+ (0.4,0) [0|101.6] "%" Vector__XXX
 SG_ RCM_a107_eventArmStatus m107 : 11|1@1+ (1,0) [0|1] "" Vector__XXX
 SG_ RCM_a107_eventFactoryMode m107 : 12|1@1+ (1,0) [0|1] "" Vector__XXX
 SG_ RCM_a107_eventDiagEnabled m107 : 13|1@1+ (1,0) [0|1] "" Vector__XXX
 SG_ RCM_a107_eventDriveOrientation m107 : 14|1@1+ (1,0) [0|1] "" Vector__XXX
 SG_ RCM_a107_imuVertAOffCompPosLife m107 : 16|1@1+ (1,0) [0|1] "" Vector__XXX
 SG_ RCM_a107_imuVertAOffCompNegLife m107 : 17|1@1+ (1,0) [0|1] "" Vector__XXX
 SG_ RCM_a107_imuVertAOffCompPosFLDC m107 : 18|1@1+ (1,0) [0|1] "" Vector__XXX
 SG_ RCM_a107_imuVertAOffCompNegFLDC m107 : 19|1@1+ (1,0) [0|1] "" Vector__XXX
 SG_ RCM_a107_imuVertAOffCompPosSLDC m107 : 20|1@1+ (1,0) [0|1] "" Vector__XXX
 SG_ RCM_a107_imuVertAOffCompNegSLDC m107 : 21|1@1+ (1,0) [0|1] "" Vector__XXX
 SG_ RCM_a107_eventIDFsignal m107 : 25|1@1+ (1,0) [0|1] "" Vector__XXX
 SG_ RCM_a107_eventFrontLeftSeatbelt m107 : 26|1@1+ (1,0) [0|1] "" Vector__XXX
 SG_ RCM_a107_eventFrontRightSeatbelt m107 : 27|1@1+ (1,0) [0|1] "" Vector__XXX
 SG_ RCM_a107_eventVehicleSpeed m107 : 28|12@1+ (0.08,-40) [-40|287.6] "kph" Vector__XXX
 SG_ RCM_a107_eventSteeringAngle m107 : 45|14@0+ (0.1,-819.2) [-819.2|819.1] "deg" Vector__XXX
 SG_ RCM_a107_eventDriverBrakeApply m107 : 46|2@1+ (1,0) [0|2] "" Vector__XXX
 SG_ RCM_a107_eventAccelPedalPos m107 : 56|8@1+ (0.4,0) [0|101.6] "%" Vector__XXX
 SG_ RCM_a108_eventArmStatus m108 : 11|1@1+ (1,0) [0|1] "" Vector__XXX
 SG_ RCM_a108_eventFactoryMode m108 : 12|1@1+ (1,0) [0|1] "" Vector__XXX
 SG_ RCM_a108_eventDiagEnabled m108 : 13|1@1+ (1,0) [0|1] "" Vector__XXX
 SG_ RCM_a108_eventDriveOrientation m108 : 14|1@1+ (1,0) [0|1] "" Vector__XXX
 SG_ RCM_a108_crashAlgoWakeupSig m108 : 16|1@1+ (1,0) [0|1] "" Vector__XXX
 SG_ RCM_a108_eventIDFsignal m108 : 25|1@1+ (1,0) [0|1] "" Vector__XXX
 SG_ RCM_a108_eventFrontLeftSeatbelt m108 : 26|1@1+ (1,0) [0|1] "" Vector__XXX
 SG_ RCM_a108_eventFrontRightSeatbelt m108 : 27|1@1+ (1,0) [0|1] "" Vector__XXX
 SG_ RCM_a108_eventVehicleSpeed m108 : 28|12@1+ (0.08,-40) [-40|287.6] "kph" Vector__XXX
 SG_ RCM_a108_eventSteeringAngle m108 : 45|14@0+ (0.1,-819.2) [-819.2|819.1] "deg" Vector__XXX
 SG_ RCM_a108_eventDriverBrakeApply m108 : 46|2@1+ (1,0) [0|2] "" Vector__XXX
 SG_ RCM_a108_eventAccelPedalPos m108 : 56|8@1+ (0.4,0) [0|101.6] "%" Vector__XXX
 SG_ RCM_a109_eventArmStatus m109 : 11|1@1+ (1,0) [0|1] "" Vector__XXX
 SG_ RCM_a109_eventFactoryMode m109 : 12|1@1+ (1,0) [0|1] "" Vector__XXX
 SG_ RCM_a109_eventDiagEnabled m109 : 13|1@1+ (1,0) [0|1] "" Vector__XXX
 SG_ RCM_a109_eventDriveOrientation m109 : 14|1@1+ (1,0) [0|1] "" Vector__XXX
 SG_ RCM_a109_immunityThrsholdCrossed m109 : 16|1@1+ (1,0) [0|1] "" Vector__XXX
 SG_ RCM_a109_eventIDFsignal m109 : 25|1@1+ (1,0) [0|1] "" Vector__XXX
 SG_ RCM_a109_eventFrontLeftSeatbelt m109 : 26|1@1+ (1,0) [0|1] "" Vector__XXX
 SG_ RCM_a109_eventFrontRightSeatbelt m109 : 27|1@1+ (1,0) [0|1] "" Vector__XXX
 SG_ RCM_a109_eventVehicleSpeed m109 : 28|12@1+ (0.08,-40) [-40|287.6] "kph" Vector__XXX
 SG_ RCM_a109_eventSteeringAngle m109 : 45|14@0+ (0.1,-819.2) [-819.2|819.1] "deg" Vector__XXX
 SG_ RCM_a109_eventDriverBrakeApply m109 : 46|2@1+ (1,0) [0|2] "" Vector__XXX
 SG_ RCM_a109_eventAccelPedalPos m109 : 56|8@1+ (0.4,0) [0|101.6] "%" Vector__XXX
 SG_ RCM_a110_eventArmStatus m110 : 11|1@1+ (1,0) [0|1] "" Vector__XXX
 SG_ RCM_a110_eventFactoryMode m110 : 12|1@1+ (1,0) [0|1] "" Vector__XXX
 SG_ RCM_a110_eventDiagEnabled m110 : 13|1@1+ (1,0) [0|1] "" Vector__XXX
 SG_ RCM_a110_eventDriveOrientation m110 : 14|1@1+ (1,0) [0|1] "" Vector__XXX
 SG_ RCM_a110_inFactoryMode m110 : 16|1@1+ (1,0) [0|1] "" Vector__XXX
 SG_ RCM_a110_eventIDFsignal m110 : 25|1@1+ (1,0) [0|1] "" Vector__XXX
 SG_ RCM_a110_eventFrontLeftSeatbelt m110 : 26|1@1+ (1,0) [0|1] "" Vector__XXX
 SG_ RCM_a110_eventFrontRightSeatbelt m110 : 27|1@1+ (1,0) [0|1] "" Vector__XXX
 SG_ RCM_a110_eventVehicleSpeed m110 : 28|12@1+ (0.08,-40) [-40|287.6] "kph" Vector__XXX
 SG_ RCM_a110_eventSteeringAngle m110 : 45|14@0+ (0.1,-819.2) [-819.2|819.1] "deg" Vector__XXX
 SG_ RCM_a110_eventDriverBrakeApply m110 : 46|2@1+ (1,0) [0|2] "" Vector__XXX
 SG_ RCM_a110_eventAccelPedalPos m110 : 56|8@1+ (0.4,0) [0|101.6] "%" Vector__XXX
 SG_ RCM_a112_eventArmStatus m112 : 11|1@1+ (1,0) [0|1] "" Vector__XXX
 SG_ RCM_a112_eventFactoryMode m112 : 12|1@1+ (1,0) [0|1] "" Vector__XXX
 SG_ RCM_a112_eventDiagEnabled m112 : 13|1@1+ (1,0) [0|1] "" Vector__XXX
 SG_ RCM_a112_eventDriveOrientation m112 : 14|1@1+ (1,0) [0|1] "" Vector__XXX
 SG_ RCM_a112_imuYawR8SnsrMonitTmp m112 : 16|1@1+ (1,0) [0|1] "" Vector__XXX
 SG_ RCM_a112_imuYawR8SnsrMonitPerm m112 : 17|1@1+ (1,0) [0|1] "" Vector__XXX
 SG_ RCM_a112_imuYawR8ChnlMonitTmp m112 : 19|1@1+ (1,0) [0|1] "" Vector__XXX
 SG_ RCM_a112_imuYawR8ChnlMonitPerm m112 : 20|1@1+ (1,0) [0|1] "" Vector__XXX
 SG_ RCM_a112_eventIDFsignal m112 : 25|1@1+ (1,0) [0|1] "" Vector__XXX
 SG_ RCM_a112_eventFrontLeftSeatbelt m112 : 26|1@1+ (1,0) [0|1] "" Vector__XXX
 SG_ RCM_a112_eventFrontRightSeatbelt m112 : 27|1@1+ (1,0) [0|1] "" Vector__XXX
 SG_ RCM_a112_eventVehicleSpeed m112 : 28|12@1+ (0.08,-40) [-40|287.6] "kph" Vector__XXX
 SG_ RCM_a112_eventSteeringAngle m112 : 45|14@0+ (0.1,-819.2) [-819.2|819.1] "deg" Vector__XXX
 SG_ RCM_a112_eventDriverBrakeApply m112 : 46|2@1+ (1,0) [0|2] "" Vector__XXX
 SG_ RCM_a112_eventAccelPedalPos m112 : 56|8@1+ (0.4,0) [0|101.6] "%" Vector__XXX
 SG_ RCM_a113_eventArmStatus m113 : 11|1@1+ (1,0) [0|1] "" Vector__XXX
 SG_ RCM_a113_eventFactoryMode m113 : 12|1@1+ (1,0) [0|1] "" Vector__XXX
 SG_ RCM_a113_eventDiagEnabled m113 : 13|1@1+ (1,0) [0|1] "" Vector__XXX
 SG_ RCM_a113_eventDriveOrientation m113 : 14|1@1+ (1,0) [0|1] "" Vector__XXX
 SG_ RCM_a113_imuPitchR8SnsrMonitTmp m113 : 16|1@1+ (1,0) [0|1] "" Vector__XXX
 SG_ RCM_a113_imuPitchR8SnsrMonitPerm m113 : 17|1@1+ (1,0) [0|1] "" Vector__XXX
 SG_ RCM_a113_imuPitchR8ChnlMonitTmp m113 : 18|1@1+ (1,0) [0|1] "" Vector__XXX
 SG_ RCM_a113_imuPitchR8ChnlMonitPerm m113 : 19|1@1+ (1,0) [0|1] "" Vector__XXX
 SG_ RCM_a113_eventIDFsignal m113 : 25|1@1+ (1,0) [0|1] "" Vector__XXX
 SG_ RCM_a113_eventFrontLeftSeatbelt m113 : 26|1@1+ (1,0) [0|1] "" Vector__XXX
 SG_ RCM_a113_eventFrontRightSeatbelt m113 : 27|1@1+ (1,0) [0|1] "" Vector__XXX
 SG_ RCM_a113_eventVehicleSpeed m113 : 28|12@1+ (0.08,-40) [-40|287.6] "kph" Vector__XXX
 SG_ RCM_a113_eventSteeringAngle m113 : 45|14@0+ (0.1,-819.2) [-819.2|819.1] "deg" Vector__XXX
 SG_ RCM_a113_eventDriverBrakeApply m113 : 46|2@1+ (1,0) [0|2] "" Vector__XXX
 SG_ RCM_a113_eventAccelPedalPos m113 : 56|8@1+ (0.4,0) [0|101.6] "%" Vector__XXX
 SG_ RCM_a114_eventArmStatus m114 : 11|1@1+ (1,0) [0|1] "" Vector__XXX
 SG_ RCM_a114_eventFactoryMode m114 : 12|1@1+ (1,0) [0|1] "" Vector__XXX
 SG_ RCM_a114_eventDiagEnabled m114 : 13|1@1+ (1,0) [0|1] "" Vector__XXX
 SG_ RCM_a114_eventDriveOrientation m114 : 14|1@1+ (1,0) [0|1] "" Vector__XXX
 SG_ RCM_a114_imuRollR8SnsrMonitTmp m114 : 16|1@1+ (1,0) [0|1] "" Vector__XXX
 SG_ RCM_a114_imuRollR8SnsrMonitPerm m114 : 17|1@1+ (1,0) [0|1] "" Vector__XXX
 SG_ RCM_a114_imuRollR8ChnlMonitTmp m114 : 18|1@1+ (1,0) [0|1] "" Vector__XXX
 SG_ RCM_a114_imuRollR8ChnlMonitPerm m114 : 19|1@1+ (1,0) [0|1] "" Vector__XXX
 SG_ RCM_a114_eventIDFsignal m114 : 25|1@1+ (1,0) [0|1] "" Vector__XXX
 SG_ RCM_a114_eventFrontLeftSeatbelt m114 : 26|1@1+ (1,0) [0|1] "" Vector__XXX
 SG_ RCM_a114_eventFrontRightSeatbelt m114 : 27|1@1+ (1,0) [0|1] "" Vector__XXX
 SG_ RCM_a114_eventVehicleSpeed m114 : 28|12@1+ (0.08,-40) [-40|287.6] "kph" Vector__XXX
 SG_ RCM_a114_eventSteeringAngle m114 : 45|14@0+ (0.1,-819.2) [-819.2|819.1] "deg" Vector__XXX
 SG_ RCM_a114_eventDriverBrakeApply m114 : 46|2@1+ (1,0) [0|2] "" Vector__XXX
 SG_ RCM_a114_eventAccelPedalPos m114 : 56|8@1+ (0.4,0) [0|101.6] "%" Vector__XXX
 SG_ RCM_a115_eventArmStatus m115 : 11|1@1+ (1,0) [0|1] "" Vector__XXX
 SG_ RCM_a115_eventFactoryMode m115 : 12|1@1+ (1,0) [0|1] "" Vector__XXX
 SG_ RCM_a115_eventDiagEnabled m115 : 13|1@1+ (1,0) [0|1] "" Vector__XXX
 SG_ RCM_a115_eventDriveOrientation m115 : 14|1@1+ (1,0) [0|1] "" Vector__XXX
 SG_ RCM_a115_imuLinAccChnlMonitTmp m115 : 16|1@1+ (1,0) [0|1] "" Vector__XXX
 SG_ RCM_a115_imuLinAccChnlMonitPerm m115 : 17|1@1+ (1,0) [0|1] "" Vector__XXX
 SG_ RCM_a115_eventIDFsignal m115 : 25|1@1+ (1,0) [0|1] "" Vector__XXX
 SG_ RCM_a115_eventFrontLeftSeatbelt m115 : 26|1@1+ (1,0) [0|1] "" Vector__XXX
 SG_ RCM_a115_eventFrontRightSeatbelt m115 : 27|1@1+ (1,0) [0|1] "" Vector__XXX
 SG_ RCM_a115_eventVehicleSpeed m115 : 28|12@1+ (0.08,-40) [-40|287.6] "kph" Vector__XXX
 SG_ RCM_a115_eventSteeringAngle m115 : 45|14@0+ (0.1,-819.2) [-819.2|819.1] "deg" Vector__XXX
 SG_ RCM_a115_eventDriverBrakeApply m115 : 46|2@1+ (1,0) [0|2] "" Vector__XXX
 SG_ RCM_a115_eventAccelPedalPos m115 : 56|8@1+ (0.4,0) [0|101.6] "%" Vector__XXX
 SG_ RCM_a116_eventArmStatus m116 : 11|1@1+ (1,0) [0|1] "" Vector__XXX
 SG_ RCM_a116_eventFactoryMode m116 : 12|1@1+ (1,0) [0|1] "" Vector__XXX
 SG_ RCM_a116_eventDiagEnabled m116 : 13|1@1+ (1,0) [0|1] "" Vector__XXX
 SG_ RCM_a116_eventDriveOrientation m116 : 14|1@1+ (1,0) [0|1] "" Vector__XXX
 SG_ RCM_a116_imuLatAccChnlMonitTmp m116 : 16|1@1+ (1,0) [0|1] "" Vector__XXX
 SG_ RCM_a116_imuLatAccChnlMonitPerm m116 : 17|1@1+ (1,0) [0|1] "" Vector__XXX
 SG_ RCM_a116_eventIDFsignal m116 : 25|1@1+ (1,0) [0|1] "" Vector__XXX
 SG_ RCM_a116_eventFrontLeftSeatbelt m116 : 26|1@1+ (1,0) [0|1] "" Vector__XXX
 SG_ RCM_a116_eventFrontRightSeatbelt m116 : 27|1@1+ (1,0) [0|1] "" Vector__XXX
 SG_ RCM_a116_eventVehicleSpeed m116 : 28|12@1+ (0.08,-40) [-40|287.6] "kph" Vector__XXX
 SG_ RCM_a116_eventSteeringAngle m116 : 45|14@0+ (0.1,-819.2) [-819.2|819.1] "deg" Vector__XXX
 SG_ RCM_a116_eventDriverBrakeApply m116 : 46|2@1+ (1,0) [0|2] "" Vector__XXX
 SG_ RCM_a116_eventAccelPedalPos m116 : 56|8@1+ (0.4,0) [0|101.6] "%" Vector__XXX
 SG_ RCM_a117_eventArmStatus m117 : 11|1@1+ (1,0) [0|1] "" Vector__XXX
 SG_ RCM_a117_eventFactoryMode m117 : 12|1@1+ (1,0) [0|1] "" Vector__XXX
 SG_ RCM_a117_eventDiagEnabled m117 : 13|1@1+ (1,0) [0|1] "" Vector__XXX
 SG_ RCM_a117_eventDriveOrientation m117 : 14|1@1+ (1,0) [0|1] "" Vector__XXX
 SG_ RCM_a117_imuZaccelChnlMonitTmp m117 : 16|1@1+ (1,0) [0|1] "" Vector__XXX
 SG_ RCM_a117_imuZaccelChnlMonitPerm m117 : 17|1@1+ (1,0) [0|1] "" Vector__XXX
 SG_ RCM_a117_eventIDFsignal m117 : 25|1@1+ (1,0) [0|1] "" Vector__XXX
 SG_ RCM_a117_eventFrontLeftSeatbelt m117 : 26|1@1+ (1,0) [0|1] "" Vector__XXX
 SG_ RCM_a117_eventFrontRightSeatbelt m117 : 27|1@1+ (1,0) [0|1] "" Vector__XXX
 SG_ RCM_a117_eventVehicleSpeed m117 : 28|12@1+ (0.08,-40) [-40|287.6] "kph" Vector__XXX
 SG_ RCM_a117_eventSteeringAngle m117 : 45|14@0+ (0.1,-819.2) [-819.2|819.1] "deg" Vector__XXX
 SG_ RCM_a117_eventDriverBrakeApply m117 : 46|2@1+ (1,0) [0|2] "" Vector__XXX
 SG_ RCM_a117_eventAccelPedalPos m117 : 56|8@1+ (0.4,0) [0|101.6] "%" Vector__XXX
 SG_ RCM_a118_eventArmStatus m118 : 11|1@1+ (1,0) [0|1] "" Vector__XXX
 SG_ RCM_a118_eventFactoryMode m118 : 12|1@1+ (1,0) [0|1] "" Vector__XXX
 SG_ RCM_a118_eventDiagEnabled m118 : 13|1@1+ (1,0) [0|1] "" Vector__XXX
 SG_ RCM_a118_eventDriveOrientation m118 : 14|1@1+ (1,0) [0|1] "" Vector__XXX
 SG_ RCM_a118_imuInPlaneSnsrMonitTmp m118 : 16|1@1+ (1,0) [0|1] "" Vector__XXX
 SG_ RCM_a118_imuInPlaneSnsrMonitPerm m118 : 17|1@1+ (1,0) [0|1] "" Vector__XXX
 SG_ RCM_a118_eventIDFsignal m118 : 25|1@1+ (1,0) [0|1] "" Vector__XXX
 SG_ RCM_a118_eventFrontLeftSeatbelt m118 : 26|1@1+ (1,0) [0|1] "" Vector__XXX
 SG_ RCM_a118_eventFrontRightSeatbelt m118 : 27|1@1+ (1,0) [0|1] "" Vector__XXX
 SG_ RCM_a118_eventVehicleSpeed m118 : 28|12@1+ (0.08,-40) [-40|287.6] "kph" Vector__XXX
 SG_ RCM_a118_eventSteeringAngle m118 : 45|14@0+ (0.1,-819.2) [-819.2|819.1] "deg" Vector__XXX
 SG_ RCM_a118_eventDriverBrakeApply m118 : 46|2@1+ (1,0) [0|2] "" Vector__XXX
 SG_ RCM_a118_eventAccelPedalPos m118 : 56|8@1+ (0.4,0) [0|101.6] "%" Vector__XXX

BO_ 881 RCM_alertMatrix: 8 RCM
 SG_ RCM_matrixIndex M : 0|4@1+ (1,0) [0|15] "" Vector__XXX
 SG_ RCM_a000_crashDetected m0 : 4|1@1+ (1,0) [0|1] "" Vector__XXX
 SG_ RCM_a001_nearDeploy m0 : 5|1@1+ (1,0) [0|1] "" Vector__XXX
 SG_ RCM_a002_airbagsNotArmed m0 : 6|1@1+ (1,0) [0|1] "" Vector__XXX
 SG_ RCM_a003_warningIndicator m0 : 7|1@1+ (1,0) [0|1] "" Vector__XXX
 SG_ RCM_a004_internalFault m0 : 8|1@1+ (1,0) [0|1] "" Vector__XXX
 SG_ RCM_a005_crcError m0 : 9|1@1+ (1,0) [0|1] "" Vector__XXX
 SG_ RCM_a006_batteryVoltageRange m0 : 10|1@1+ (1,0) [0|1] "" Vector__XXX
 SG_ RCM_a007_powerSupplyExternal m0 : 11|1@1+ (1,0) [0|1] "" Vector__XXX
 SG_ RCM_a008_powerSupplyInternal m0 : 12|1@1+ (1,0) [0|1] "" Vector__XXX
 SG_ RCM_a009_reprogramLimit m0 : 13|1@1+ (1,0) [0|1] "" Vector__XXX
 SG_ RCM_a010_scmDisabled m0 : 14|1@1+ (1,0) [0|1] "" Vector__XXX
 SG_ RCM_a011_eepromDataLocked m0 : 15|1@1+ (1,0) [0|1] "" Vector__XXX
 SG_ RCM_a012_vinStorage m0 : 16|1@1+ (1,0) [0|1] "" Vector__XXX
 SG_ RCM_a013_driverOrientation m0 : 17|1@1+ (1,0) [0|1] "" Vector__XXX
 SG_ RCM_a014_driverABStage1 m0 : 18|1@1+ (1,0) [0|1] "" Vector__XXX
 SG_ RCM_a015_driverABStage2 m0 : 19|1@1+ (1,0) [0|1] "" Vector__XXX
 SG_ RCM_a016_passABStage1 m0 : 20|1@1+ (1,0) [0|1] "" Vector__XXX
 SG_ RCM_a017_passABStage2 m0 : 21|1@1+ (1,0) [0|1] "" Vector__XXX
 SG_ RCM_a018_passengerActiveVent m0 : 22|1@1+ (1,0) [0|1] "" Vector__XXX
 SG_ RCM_a019_pretenShldrFrontLeft m0 : 23|1@1+ (1,0) [0|1] "" Vector__XXX
 SG_ RCM_a020_pretenShldFrontRight m0 : 24|1@1+ (1,0) [0|1] "" Vector__XXX
 SG_ RCM_a021_pretenLapFrontLeft m0 : 25|1@1+ (1,0) [0|1] "" Vector__XXX
 SG_ RCM_a022_pretenLapFrontRight m0 : 26|1@1+ (1,0) [0|1] "" Vector__XXX
 SG_ RCM_a023_loadLimiterLeftSide m0 : 27|1@1+ (1,0) [0|1] "" Vector__XXX
 SG_ RCM_a024_loadLimiterRightSide m0 : 28|1@1+ (1,0) [0|1] "" Vector__XXX
 SG_ RCM_a025_kneeABDriver m0 : 29|1@1+ (1,0) [0|1] "" Vector__XXX
 SG_ RCM_a026_kneeABFrontPassenger m0 : 30|1@1+ (1,0) [0|1] "" Vector__XXX
 SG_ RCM_a027_sideAB1stRowLeft m0 : 31|1@1+ (1,0) [0|1] "" Vector__XXX
 SG_ RCM_a028_sideAB1stRowRight m0 : 32|1@1+ (1,0) [0|1] "" Vector__XXX
 SG_ RCM_a029_driverABActiveVent m0 : 33|1@1+ (1,0) [0|1] "" Vector__XXX
 SG_ RCM_a030_farSideInboardAirbag m0 : 34|1@1+ (1,0) [0|1] "" Vector__XXX
 SG_ RCM_a031_frontCenterAirbag m0 : 35|1@1+ (1,0) [0|1] "" Vector__XXX
 SG_ RCM_a032_curtainABLeft m0 : 36|1@1+ (1,0) [0|1] "" Vector__XXX
 SG_ RCM_a033_curtainABRight m0 : 37|1@1+ (1,0) [0|1] "" Vector__XXX
 SG_ RCM_a034_preten2ndRowLeft m0 : 38|1@1+ (1,0) [0|1] "" Vector__XXX
 SG_ RCM_a035_preten2ndRowRight m0 : 39|1@1+ (1,0) [0|1] "" Vector__XXX
 SG_ RCM_a036_curAB2ndRowLeft m0 : 40|1@1+ (1,0) [0|1] "" Vector__XXX
 SG_ RCM_a037_curAB2ndRowRight m0 : 41|1@1+ (1,0) [0|1] "" Vector__XXX
 SG_ RCM_a038_unusedA m0 : 42|1@1+ (1,0) [0|1] "" Vector__XXX
 SG_ RCM_a039_unusedB m0 : 43|1@1+ (1,0) [0|1] "" Vector__XXX
 SG_ RCM_a040_hoodActuatorRight m0 : 44|1@1+ (1,0) [0|1] "" Vector__XXX
 SG_ RCM_a041_hoodActuatorLeft m0 : 45|1@1+ (1,0) [0|1] "" Vector__XXX
 SG_ RCM_a042_ens1Line m0 : 46|1@1+ (1,0) [0|1] "" Vector__XXX
 SG_ RCM_a043_ens2Line m0 : 47|1@1+ (1,0) [0|1] "" Vector__XXX
 SG_ RCM_a044_upFrontSensorLeft m0 : 48|1@1+ (1,0) [0|1] "" Vector__XXX
 SG_ RCM_a045_upFrontSensorRight m0 : 49|1@1+ (1,0) [0|1] "" Vector__XXX
 SG_ RCM_a046_sideAccelBPillarLeft m0 : 50|1@1+ (1,0) [0|1] "" Vector__XXX
 SG_ RCM_a047_sideAccelBPillarRight m0 : 51|1@1+ (1,0) [0|1] "" Vector__XXX
 SG_ RCM_a048_sideAccelCPillarLeft m0 : 52|1@1+ (1,0) [0|1] "" Vector__XXX
 SG_ RCM_a049_sideAccelCPillarRight m0 : 53|1@1+ (1,0) [0|1] "" Vector__XXX
 SG_ RCM_a050_upFrontSensorCenter m0 : 54|1@1+ (1,0) [0|1] "" Vector__XXX
 SG_ RCM_a051_pressureFrontLftDoor m0 : 55|1@1+ (1,0) [0|1] "" Vector__XXX
 SG_ RCM_a052_pressureFrontRtDoor m0 : 56|1@1+ (1,0) [0|1] "" Vector__XXX
 SG_ RCM_a053_pressurePedProLeft m0 : 57|1@1+ (1,0) [0|1] "" Vector__XXX
 SG_ RCM_a054_pressurePedProRight m0 : 58|1@1+ (1,0) [0|1] "" Vector__XXX
 SG_ RCM_a055_inertialMeasurement m0 : 59|1@1+ (1,0) [0|1] "" Vector__XXX
 SG_ RCM_a056_passengerFrontOCS m0 : 60|1@1+ (1,0) [0|1] "" Vector__XXX
 SG_ RCM_a057_driverOCS m0 : 61|1@1+ (1,0) [0|1] "" Vector__XXX
 SG_ RCM_a058_buckle1stRowLeft m0 : 62|1@1+ (1,0) [0|1] "" Vector__XXX
 SG_ RCM_a059_buckle1stRowRight m0 : 63|1@1+ (1,0) [0|1] "" Vector__XXX
 SG_ RCM_a060_stpsLeft m1 : 4|1@1+ (1,0) [0|1] "" Vector__XXX
 SG_ RCM_a061_stpsRight m1 : 5|1@1+ (1,0) [0|1] "" Vector__XXX
 SG_ RCM_a062_alrSwitch m1 : 6|1@1+ (1,0) [0|1] "" Vector__XXX
 SG_ RCM_a063_sbsw2ndRowRight m1 : 7|1@1+ (1,0) [0|1] "" Vector__XXX
 SG_ RCM_a064_hardwareCodingPin1 m1 : 8|1@1+ (1,0) [0|1] "" Vector__XXX
 SG_ RCM_a065_driverOrientConfigPin m1 : 9|1@1+ (1,0) [0|1] "" Vector__XXX
 SG_ RCM_a066_seatBackSw2ndRowLeft m1 : 10|1@1+ (1,0) [0|1] "" Vector__XXX
 SG_ RCM_a067_comCANInitFailure m1 : 11|1@1+ (1,0) [0|1] "" Vector__XXX
 SG_ RCM_a068_comChassisBusOff m1 : 12|1@1+ (1,0) [0|1] "" Vector__XXX
 SG_ RCM_a069_comCHCANPH7 m1 : 13|1@1+ (1,0) [0|1] "" Vector__XXX
 SG_ RCM_a070_comCHCANPH8 m1 : 14|1@1+ (1,0) [0|1] "" Vector__XXX
 SG_ RCM_a071_comCHCANPH9 m1 : 15|1@1+ (1,0) [0|1] "" Vector__XXX
 SG_ RCM_a072_comUnused m1 : 16|1@1+ (1,0) [0|1] "" Vector__XXX
 SG_ RCM_a073_comCHCANPH4 m1 : 17|1@1+ (1,0) [0|1] "" Vector__XXX
 SG_ RCM_a074_comCHCANPH5 m1 : 18|1@1+ (1,0) [0|1] "" Vector__XXX
 SG_ RCM_a075_comCHCANPH6 m1 : 19|1@1+ (1,0) [0|1] "" Vector__XXX
 SG_ RCM_a076_comEPBLStatus m1 : 20|1@1+ (1,0) [0|1] "" Vector__XXX
 SG_ RCM_a077_comEPBRStatus m1 : 21|1@1+ (1,0) [0|1] "" Vector__XXX
 SG_ RCM_a078_comOCS1PStatus m1 : 22|1@1+ (1,0) [0|1] "" Vector__XXX
 SG_ RCM_a079_comOCS1DStatus m1 : 23|1@1+ (1,0) [0|1] "" Vector__XXX
 SG_ RCM_a080_comGTWACS m1 : 24|1@1+ (1,0) [0|1] "" Vector__XXX
 SG_ RCM_a081_comVCFRONTLVPwr m1 : 25|1@1+ (1,0) [0|1] "" Vector__XXX
 SG_ RCM_a082_comUIodo m1 : 26|1@1+ (1,0) [0|1] "" Vector__XXX
 SG_ RCM_a083_comGTWCarState m1 : 27|1@1+ (1,0) [0|1] "" Vector__XXX
 SG_ RCM_a084_comTPMSStatus m1 : 28|1@1+ (1,0) [0|1] "" Vector__XXX
 SG_ RCM_a085_comGTWCarConfig m1 : 29|1@1+ (1,0) [0|1] "" Vector__XXX
 SG_ RCM_a086_comVINMIA m1 : 30|1@1+ (1,0) [0|1] "" Vector__XXX
 SG_ RCM_a087_comCANSilent m1 : 31|1@1+ (1,0) [0|1] "" Vector__XXX
 SG_ RCM_a088_comCHCANPH2 m1 : 32|1@1+ (1,0) [0|1] "" Vector__XXX
 SG_ RCM_a089_comCHCANPH3 m1 : 33|1@1+ (1,0) [0|1] "" Vector__XXX
 SG_ RCM_a090_comPartyBusOff m1 : 34|1@1+ (1,0) [0|1] "" Vector__XXX
 SG_ RCM_a091_comEPAS3PsysStatus m1 : 35|1@1+ (1,0) [0|1] "" Vector__XXX
 SG_ RCM_a092_comDASISF m1 : 36|1@1+ (1,0) [0|1] "" Vector__XXX
 SG_ RCM_a093_comVCLEFTStatus m1 : 37|1@1+ (1,0) [0|1] "" Vector__XXX
 SG_ RCM_a094_comVCRIGHTStatus m1 : 38|1@1+ (1,0) [0|1] "" Vector__XXX
 SG_ RCM_a095_comESPstatus m1 : 39|1@1+ (1,0) [0|1] "" Vector__XXX
 SG_ RCM_a096_comESPwheelSpeeds m1 : 40|1@1+ (1,0) [0|1] "" Vector__XXX
 SG_ RCM_a097_comDIspeed m1 : 41|1@1+ (1,0) [0|1] "" Vector__XXX
 SG_ RCM_a098_comDIchassisControl m1 : 42|1@1+ (1,0) [0|1] "" Vector__XXX
 SG_ RCM_a099_comDItorque m1 : 43|1@1+ (1,0) [0|1] "" Vector__XXX
 SG_ RCM_a100_comDIsystemStatus m1 : 44|1@1+ (1,0) [0|1] "" Vector__XXX
 SG_ RCM_a101_idfSystem m1 : 45|1@1+ (1,0) [0|1] "" Vector__XXX
 SG_ RCM_a102_imuYawR8OffstCompLim m1 : 46|1@1+ (1,0) [0|1] "" Vector__XXX
 SG_ RCM_a103_imuPtchR8OffstCompLim m1 : 47|1@1+ (1,0) [0|1] "" Vector__XXX
 SG_ RCM_a104_imuRollR8OffstCompLim m1 : 48|1@1+ (1,0) [0|1] "" Vector__XXX
 SG_ RCM_a105_imuLongAccOffstCompLim m1 : 49|1@1+ (1,0) [0|1] "" Vector__XXX
 SG_ RCM_a106_imuLatAccOffstCompLim m1 : 50|1@1+ (1,0) [0|1] "" Vector__XXX
 SG_ RCM_a107_imuVertAccOffstCompLim m1 : 51|1@1+ (1,0) [0|1] "" Vector__XXX
 SG_ RCM_a108_crashAlgoWakeup m1 : 52|1@1+ (1,0) [0|1] "" Vector__XXX
 SG_ RCM_a109_abuseImmunity m1 : 53|1@1+ (1,0) [0|1] "" Vector__XXX
 SG_ RCM_a110_factoryMode m1 : 54|1@1+ (1,0) [0|1] "" Vector__XXX
 SG_ RCM_a111_diagnosticsEnabled m1 : 55|1@1+ (1,0) [0|1] "" Vector__XXX
 SG_ RCM_a112_imuYawRate m1 : 56|1@1+ (1,0) [0|1] "" Vector__XXX
 SG_ RCM_a113_imuPitchRate m1 : 57|1@1+ (1,0) [0|1] "" Vector__XXX
 SG_ RCM_a114_imuRollRate m1 : 58|1@1+ (1,0) [0|1] "" Vector__XXX
 SG_ RCM_a115_imuLinearAcceleration m1 : 59|1@1+ (1,0) [0|1] "" Vector__XXX
 SG_ RCM_a116_imuLateralAcceleration m1 : 60|1@1+ (1,0) [0|1] "" Vector__XXX
 SG_ RCM_a117_imuVerticalAcceleration m1 : 61|1@1+ (1,0) [0|1] "" Vector__XXX
 SG_ RCM_a118_imuInPlaneAcceleration m1 : 62|1@1+ (1,0) [0|1] "" Vector__XXX

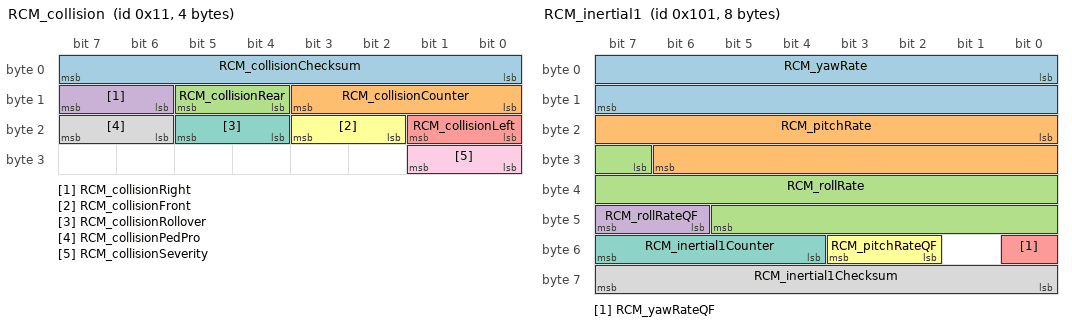
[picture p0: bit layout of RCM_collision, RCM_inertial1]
BO_ 17 RCM_collision: 4 RCM
 SG_ RCM_collisionChecksum : 0|8@1+ (1,0) [0|255] "" Vector__XXX
 SG_ RCM_collisionCounter : 8|4@1+ (1,0) [0|15] "" Vector__XXX
 SG_ RCM_collisionRear : 12|2@1+ (1,0) [0|2] "" Vector__XXX
 SG_ RCM_collisionRight : 14|2@1+ (1,0) [0|2] "" Vector__XXX
 SG_ RCM_collisionLeft : 16|2@1+ (1,0) [0|2] "" Vector__XXX
 SG_ RCM_collisionFront : 18|2@1+ (1,0) [0|2] "" Vector__XXX
 SG_ RCM_collisionRollover : 20|2@1+ (1,0) [0|2] "" Vector__XXX
 SG_ RCM_collisionPedPro : 22|2@1+ (1,0) [0|2] "" Vector__XXX
 SG_ RCM_collisionSeverity : 24|2@1+ (1,0) [0|3] "" Vector__XXX

BO_ 257 RCM_inertial1: 8 RCM
 SG_ RCM_yawRate : 0|16@1- (0.0001,0) [-3.2766|3.2766] "rad/s" Vector__XXX
 SG_ RCM_pitchRate : 16|15@1- (0.00025,0) [-4.096|4.09575] "rad/s" Vector__XXX
 SG_ RCM_rollRate : 31|15@1- (0.00025,0) [-4.096|4.09575] "rad/s" Vector__XXX
 SG_ RCM_rollRateQF : 46|2@1+ (1,0) [0|3] "" Vector__XXX
 SG_ RCM_yawRateQF : 48|1@1+ (1,0) [0|1] "" Vector__XXX
 SG_ RCM_pitchRateQF : 50|2@1+ (1,0) [0|3] "" Vector__XXX
 SG_ RCM_inertial1Counter : 52|4@1+ (1,0) [0|15] "" Vector__XXX
 SG_ RCM_inertial1Checksum : 56|8@1+ (1,0) [0|255] "" Vector__XXX

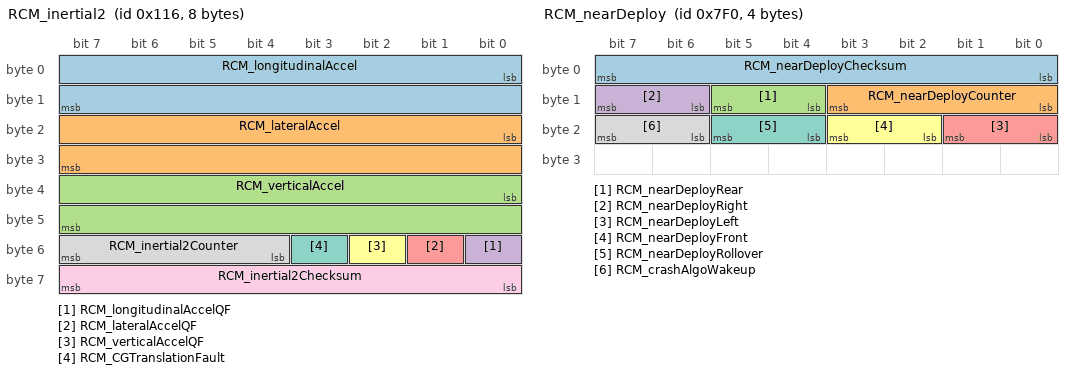
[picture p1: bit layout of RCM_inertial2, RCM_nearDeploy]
BO_ 278 RCM_inertial2: 8 RCM
 SG_ RCM_longitudinalAccel : 0|16@1- (0.00125,0) [-40.9575|40.9575] "m/s^2" Vector__XXX
 SG_ RCM_lateralAccel : 16|16@1- (0.00125,0) [-40.9575|40.9575] "m/s^2" Vector__XXX
 SG_ RCM_verticalAccel : 32|16@1- (0.00125,0) [-40.9575|39.2] "m/s^2" Vector__XXX
 SG_ RCM_longitudinalAccelQF : 48|1@1+ (1,0) [0|1] "" Vector__XXX
 SG_ RCM_lateralAccelQF : 49|1@1+ (1,0) [0|1] "" Vector__XXX
 SG_ RCM_verticalAccelQF : 50|1@1+ (1,0) [0|1] "" Vector__XXX
 SG_ RCM_CGTranslationFault : 51|1@1+ (1,0) [0|1] "" Vector__XXX
 SG_ RCM_inertial2Counter : 52|4@1+ (1,0) [0|15] "" Vector__XXX
 SG_ RCM_inertial2Checksum : 56|8@1+ (1,0) [0|255] "" Vector__XXX

BO_ 849 RCM_info: 8 RCM
 SG_ RCM_infoIndex M : 0|8@1+ (1,0) [0|255] "" Vector__XXX
 SG_ RCM_infoBuildType m10 : 8|8@1+ (1,0) [0|255] "" Vector__XXX
 SG_ RCM_infoComponentID m10 : 48|16@1+ (1,0) [0|65535] "" Vector__XXX
 SG_ RCM_infoPcbaID m11 : 16|8@1+ (1,0) [0|255] "" Vector__XXX
 SG_ RCM_infoAssemblyID m11 : 24|8@1+ (1,0) [0|255] "" Vector__XXX
 SG_ RCM_infoUsageID m11 : 32|16@1+ (1,0) [0|65535] "" Vector__XXX
 SG_ RCM_infoApplicationCRC m13 : 32|32@1+ (1,0) [0|4294967295] "" Vector__XXX
 SG_ RCM_infoBootUdsProtoVersion m20 : 8|8@1+ (1,0) [0|255] "" Vector__XXX
 SG_ RCM_infoBootloaderCRC m20 : 32|32@1+ (1,0) [0|4294967295] "" Vector__XXX
 SG_ RCM_infoAlgoCalID m22 : 8|8@1+ (1,0) [0|255] "" Vector__XXX
 SG_ RCM_infoVariantCRC m22 : 32|32@1+ (1,0) [0|4294967295] "" Vector__XXX

BO_ 2032 RCM_nearDeploy: 4 RCM
 SG_ RCM_nearDeployChecksum : 0|8@1+ (1,0) [0|255] "" Vector__XXX
 SG_ RCM_nearDeployCounter : 8|4@1+ (1,0) [0|15] "" Vector__XXX
 SG_ RCM_nearDeployRear : 12|2@1+ (1,0) [0|2] "" Vector__XXX
 SG_ RCM_nearDeployRight : 14|2@1+ (1,0) [0|2] "" Vector__XXX
 SG_ RCM_nearDeployLeft : 16|2@1+ (1,0) [0|2] "" Vector__XXX
 SG_ RCM_nearDeployFront : 18|2@1+ (1,0) [0|2] "" Vector__XXX
 SG_ RCM_nearDeployRollover : 20|2@1+ (1,0) [0|2] "" Vector__XXX
 SG_ RCM_crashAlgoWakeup : 22|2@1+ (1,0) [0|2] "" Vector__XXX

BO_ 529 RCM_status: 6 RCM
 SG_ RCM_statusChecksum : 0|8@1+ (1,0) [0|255] "" Vector__XXX
 SG_ RCM_statusCounter : 8|4@1+ (1,0) [0|15] "" Vector__XXX
 SG_ RCM_armStatus : 12|2@1+ (1,0) [0|2] "" Vector__XXX
 SG_ RCM_warningIndicatorState : 14|2@1+ (1,0) [0|2] "" Vector__XXX
 SG_ RCM_passAirbagIndicatorRequest : 16|2@1+ (1,0) [0|2] "" Vector__XXX
 SG_ RCM_airbagCutoffStatus : 18|2@1+ (1,0) [0|2] "" Vector__XXX
 SG_ RCM_alrSwitchStatus : 20|2@1+ (1,0) [0|2] "" Vector__XXX
 SG_ RCM_vinLearnFlag : 22|2@1+ (1,0) [0|2] "" Vector__XXX
 SG_ RCM_seatTrackPositionDrvr : 24|2@1+ (1,0) [0|2] "" Vector__XXX
 SG_ RCM_seatTrackPositionPass : 26|2@1+ (1,0) [0|2] "" Vector__XXX
 SG_ RCM_edr1State : 28|2@1+ (1,0) [0|3] "" Vector__XXX
 SG_ RCM_edr2State : 30|2@1+ (1,0) [0|3] "" Vector__XXX
 SG_ RCM_keepPowerReason : 32|4@1+ (1,0) [0|15] "" Vector__XXX
 SG_ RCM_imuOffsetLearnState : 36|2@1+ (1,0) [0|3] "" Vector__XXX
 SG_ RCM_edr3State : 38|2@1+ (1,0) [0|3] "" Vector__XXX
 SG_ RCM_driverOrientationInitStatus : 40|3@1+ (1,0) [0|6] "" Vector__XXX
 SG_ RCM_occupantClassificationSource : 43|1@1+ (1,0) [0|1] "" Vector__XXX
 SG_ RCM_pedProEDR1State : 44|2@1+ (1,0) [0|3] "" Vector__XXX
 SG_ RCM_pedProEDR2State : 46|2@1+ (1,0) [0|3] "" Vector__XXX

BO_ 1471 RCU_alertLog: 8 RCU
 SG_ RCU_alertID M : 0|6@1+ (1,0) [0|63] "" Vector__XXX
 SG_ RCU_alertState : 15|1@1+ (1,0) [0|1] "" Vector__XXX
 SG_ RCU_a010_sensorPowerSupply m10 : 16|1@1+ (1,0) [0|1] "" Vector__XXX
 SG_ RCU_a010_sensorHardware m10 : 17|1@1+ (1,0) [0|1] "" Vector__XXX
 SG_ RCU_a010_sensorSignal m10 : 18|1@1+ (1,0) [0|1] "" Vector__XXX
 SG_ RCU_a023_validityOnChassisBus m23 : 16|1@1+ (1,0) [0|1] "" Vector__XXX
 SG_ RCU_a023_validityOnPartyBus m23 : 17|1@1+ (1,0) [0|1] "" Vector__XXX
 SG_ RCU_a024_validityOnChassisBus m24 : 16|1@1+ (1,0) [0|1] "" Vector__XXX
 SG_ RCU_a024_validityOnPartyBus m24 : 17|1@1+ (1,0) [0|1] "" Vector__XXX
 SG_ RCU_a025_validityOnChassisBus m25 : 16|1@1+ (1,0) [0|1] "" Vector__XXX
 SG_ RCU_a025_validityOnPartyBus m25 : 17|1@1+ (1,0) [0|1] "" Vector__XXX
 SG_ RCU_a035_validityOnChassisBus m35 : 16|1@1+ (1,0) [0|1] "" Vector__XXX
 SG_ RCU_a035_validityOnPartyBus m35 : 17|1@1+ (1,0) [0|1] "" Vector__XXX
 SG_ RCU_a036_validityOnChassisBus m36 : 16|1@1+ (1,0) [0|1] "" Vector__XXX
 SG_ RCU_a036_validityOnPartyBus m36 : 17|1@1+ (1,0) [0|1] "" Vector__XXX

BO_TX_BU_ 881 : RCM;
BO_TX_BU_ 17 : RCM;
BO_TX_BU_ 257 : RCM;
BO_TX_BU_ 278 : RCM;
BO_TX_BU_ 849 : RCM;
BO_TX_BU_ 2032 : RCM;
BO_TX_BU_ 529 : RCM;
BO_TX_BU_ 1471 : RCU;
CM_ SG_ 1297 RCM_a069_eventDriveOrientation "Restraint control module: a069 event drive orientation";
CM_ SG_ 1297 RCM_a069_comChassisCANPH7MIA "Restraint control module: a069 com chassis CANPH7 MIA";
CM_ SG_ 1297 RCM_a069_comChassisCANPH7ChkSm "Restraint control module: a069 com chassis CANPH7 chk sm";
CM_ SG_ 1297 RCM_a069_comChassisCANPH7Cntr "Restraint control module: a069 com chassis CANPH7 cntr";
CM_ SG_ 1297 RCM_a069_eventIDFsignal "Restraint control module: a069 event ID fsignal";
CM_ SG_ 1297 RCM_a069_eventFrontLeftSeatbelt "Restraint control module: a069 event front left seatbelt";
CM_ SG_ 1297 RCM_a069_eventFrontRightSeatbelt "Restraint control module: a069 event front right seatbelt";
CM_ SG_ 1297 RCM_a069_eventVehicleSpeed "Restraint control module: a069 event vehicle speed";
CM_ SG_ 1297 RCM_a069_eventSteeringAngle "Restraint control module: a069 event steering angle";
CM_ SG_ 1297 RCM_a069_eventDriverBrakeApply "Restraint control module: a069 event driver brake apply; raw 3 = signal not available (SNA)";
CM_ SG_ 1297 RCM_a069_eventAccelPedalPos "Restraint control module: a069 event accel pedal pos; raw 255 = signal not available (SNA)";
CM_ SG_ 1297 RCM_a070_eventArmStatus "Restraint control module: a070 event arm status";
CM_ SG_ 1297 RCM_a070_eventFactoryMode "Restraint control module: a070 event factory mode";
CM_ SG_ 1297 RCM_a070_eventDiagEnabled "Restraint control module: a070 event diag enabled";
CM_ SG_ 1297 RCM_a070_eventDriveOrientation "Restraint control module: a070 event drive orientation";
CM_ SG_ 1297 RCM_a070_comChassisCANPH8MIA "Restraint control module: a070 com chassis CANPH8 MIA";
CM_ SG_ 1297 RCM_a070_comChassisCANPH8ChkSm "Restraint control module: a070 com chassis CANPH8 chk sm";
CM_ SG_ 1297 RCM_a070_comChassisCANPH8Cntr "Restraint control module: a070 com chassis CANPH8 cntr";
CM_ SG_ 1297 RCM_a070_eventIDFsignal "Restraint control module: a070 event ID fsignal";
CM_ SG_ 1297 RCM_a070_eventFrontLeftSeatbelt "Restraint control module: a070 event front left seatbelt";
CM_ SG_ 1297 RCM_a070_eventFrontRightSeatbelt "Restraint control module: a070 event front right seatbelt";
CM_ SG_ 1297 RCM_a070_eventVehicleSpeed "Restraint control module: a070 event vehicle speed";
CM_ SG_ 1297 RCM_a070_eventSteeringAngle "Restraint control module: a070 event steering angle";
CM_ SG_ 1297 RCM_a070_eventDriverBrakeApply "Restraint control module: a070 event driver brake apply; raw 3 = signal not available (SNA)";
CM_ SG_ 1297 RCM_a070_eventAccelPedalPos "Restraint control module: a070 event accel pedal pos; raw 255 = signal not available (SNA)";
CM_ SG_ 1297 RCM_a071_eventArmStatus "Restraint control module: a071 event arm status";
CM_ SG_ 1297 RCM_a071_eventFactoryMode "Restraint control module: a071 event factory mode";
CM_ SG_ 1297 RCM_a071_eventDiagEnabled "Restraint control module: a071 event diag enabled";
CM_ SG_ 1297 RCM_a071_eventDriveOrientation "Restraint control module: a071 event drive orientation";
CM_ SG_ 1297 RCM_a071_comChassisCANPH9MIA "Restraint control module: a071 com chassis CANPH9 MIA";
CM_ SG_ 1297 RCM_a071_comChassisCANPH9ChkSm "Restraint control module: a071 com chassis CANPH9 chk sm";
CM_ SG_ 1297 RCM_a071_comChassisCANPH9Cntr "Restraint control module: a071 com chassis CANPH9 cntr";
CM_ SG_ 1297 RCM_a071_eventIDFsignal "Restraint control module: a071 event ID fsignal";
CM_ SG_ 1297 RCM_a071_eventFrontLeftSeatbelt "Restraint control module: a071 event front left seatbelt";
CM_ SG_ 1297 RCM_a071_eventFrontRightSeatbelt "Restraint control module: a071 event front right seatbelt";
CM_ SG_ 1297 RCM_a071_eventVehicleSpeed "Restraint control module: a071 event vehicle speed";
CM_ SG_ 1297 RCM_a071_eventSteeringAngle "Restraint control module: a071 event steering angle";
CM_ SG_ 1297 RCM_a071_eventDriverBrakeApply "Restraint control module: a071 event driver brake apply; raw 3 = signal not available (SNA)";
CM_ SG_ 1297 RCM_a071_eventAccelPedalPos "Restraint control module: a071 event accel pedal pos; raw 255 = signal not available (SNA)";
CM_ SG_ 1297 RCM_a072_eventArmStatus "Restraint control module: a072 event arm status";
CM_ SG_ 1297 RCM_a072_eventFactoryMode "Restraint control module: a072 event factory mode";
CM_ SG_ 1297 RCM_a072_eventDiagEnabled "Restraint control module: a072 event diag enabled";
CM_ SG_ 1297 RCM_a072_eventDriveOrientation "Restraint control module: a072 event drive orientation";
CM_ SG_ 1297 RCM_a072_comUnusedMIA "Restraint control module: a072 com unused MIA";
CM_ SG_ 1297 RCM_a072_comUnusedChkSm "Restraint control module: a072 com unused chk sm";
CM_ SG_ 1297 RCM_a072_comUnusedCntr "Restraint control module: a072 com unused cntr";
CM_ SG_ 1297 RCM_a072_eventIDFsignal "Restraint control module: a072 event ID fsignal";
CM_ SG_ 1297 RCM_a072_eventFrontLeftSeatbelt "Restraint control module: a072 event front left seatbelt";
CM_ SG_ 1297 RCM_a072_eventFrontRightSeatbelt "Restraint control module: a072 event front right seatbelt";
CM_ SG_ 1297 RCM_a072_eventVehicleSpeed "Restraint control module: a072 event vehicle speed";
CM_ SG_ 1297 RCM_a072_eventSteeringAngle "Restraint control module: a072 event steering angle";
CM_ SG_ 1297 RCM_a072_eventDriverBrakeApply "Restraint control module: a072 event driver brake apply; raw 3 = signal not available (SNA)";
CM_ SG_ 1297 RCM_a072_eventAccelPedalPos "Restraint control module: a072 event accel pedal pos; raw 255 = signal not available (SNA)";
CM_ SG_ 1297 RCM_a073_eventArmStatus "Restraint control module: a073 event arm status";
CM_ SG_ 1297 RCM_a073_eventFactoryMode "Restraint control module: a073 event factory mode";
CM_ SG_ 1297 RCM_a073_eventDiagEnabled "Restraint control module: a073 event diag enabled";
CM_ SG_ 1297 RCM_a073_eventDriveOrientation "Restraint control module: a073 event drive orientation";
CM_ SG_ 1297 RCM_a073_comChassisCANPH4MIA "Restraint control module: a073 com chassis CANPH4 MIA";
CM_ SG_ 1297 RCM_a073_comChassisCANPH4ChkSm "Restraint control module: a073 com chassis CANPH4 chk sm";
CM_ SG_ 1297 RCM_a073_comChassisCANPH4Cntr "Restraint control module: a073 com chassis CANPH4 cntr";
CM_ SG_ 1297 RCM_a073_eventIDFsignal "Restraint control module: a073 event ID fsignal";
CM_ SG_ 1297 RCM_a073_eventFrontLeftSeatbelt "Restraint control module: a073 event front left seatbelt";
CM_ SG_ 1297 RCM_a073_eventFrontRightSeatbelt "Restraint control module: a073 event front right seatbelt";
CM_ SG_ 1297 RCM_a073_eventVehicleSpeed "Restraint control module: a073 event vehicle speed";
CM_ SG_ 1297 RCM_a073_eventSteeringAngle "Restraint control module: a073 event steering angle";
CM_ SG_ 1297 RCM_a073_eventDriverBrakeApply "Restraint control module: a073 event driver brake apply; raw 3 = signal not available (SNA)";
CM_ SG_ 1297 RCM_a073_eventAccelPedalPos "Restraint control module: a073 event accel pedal pos; raw 255 = signal not available (SNA)";
CM_ SG_ 1297 RCM_a074_eventArmStatus "Restraint control module: a074 event arm status";
CM_ SG_ 1297 RCM_a074_eventFactoryMode "Restraint control module: a074 event factory mode";
CM_ SG_ 1297 RCM_a074_eventDiagEnabled "Restraint control module: a074 event diag enabled";
CM_ SG_ 1297 RCM_a074_eventDriveOrientation "Restraint control module: a074 event drive orientation";
CM_ SG_ 1297 RCM_a074_comChassisCANPH5MIA "Restraint control module: a074 com chassis CANPH5 MIA";
CM_ SG_ 1297 RCM_a074_comChassisCANPH5ChkSm "Restraint control module: a074 com chassis CANPH5 chk sm";
CM_ SG_ 1297 RCM_a074_comChassisCANPH5Cntr "Restraint control module: a074 com chassis CANPH5 cntr";
CM_ SG_ 1297 RCM_a074_eventIDFsignal "Restraint control module: a074 event ID fsignal";
CM_ SG_ 1297 RCM_a074_eventFrontLeftSeatbelt "Restraint control module: a074 event front left seatbelt";
CM_ SG_ 1297 RCM_a074_eventFrontRightSeatbelt "Restraint control module: a074 event front right seatbelt";
CM_ SG_ 1297 RCM_a074_eventVehicleSpeed "Restraint control module: a074 event vehicle speed";
CM_ SG_ 1297 RCM_a074_eventSteeringAngle "Restraint control module: a074 event steering angle";
CM_ SG_ 1297 RCM_a074_eventDriverBrakeApply "Restraint control module: a074 event driver brake apply; raw 3 = signal not available (SNA)";
CM_ SG_ 1297 RCM_a074_eventAccelPedalPos "Restraint control module: a074 event accel pedal pos; raw 255 = signal not available (SNA)";
CM_ SG_ 1297 RCM_a075_eventArmStatus "Restraint control module: a075 event arm status";
CM_ SG_ 1297 RCM_a075_eventFactoryMode "Restraint control module: a075 event factory mode";
CM_ SG_ 1297 RCM_a075_eventDiagEnabled "Restraint control module: a075 event diag enabled";
CM_ SG_ 1297 RCM_a075_eventDriveOrientation "Restraint control module: a075 event drive orientation";
CM_ SG_ 1297 RCM_a075_comChassisCANPH6MIA "Restraint control module: a075 com chassis CANPH6 MIA";
CM_ SG_ 1297 RCM_a075_comChassisCANPH6ChkSm "Restraint control module: a075 com chassis CANPH6 chk sm";
CM_ SG_ 1297 RCM_a075_comChassisCANPH6Cntr "Restraint control module: a075 com chassis CANPH6 cntr";
CM_ SG_ 1297 RCM_a075_eventIDFsignal "Restraint control module: a075 event ID fsignal";
CM_ SG_ 1297 RCM_a075_eventFrontLeftSeatbelt "Restraint control module: a075 event front left seatbelt";
CM_ SG_ 1297 RCM_a075_eventFrontRightSeatbelt "Restraint control module: a075 event front right seatbelt";
CM_ SG_ 1297 RCM_a075_eventVehicleSpeed "Restraint control module: a075 event vehicle speed";
CM_ SG_ 1297 RCM_a075_eventSteeringAngle "Restraint control module: a075 event steering angle";
CM_ SG_ 1297 RCM_a075_eventDriverBrakeApply "Restraint control module: a075 event driver brake apply; raw 3 = signal not available (SNA)";
CM_ SG_ 1297 RCM_a075_eventAccelPedalPos "Restraint control module: a075 event accel pedal pos; raw 255 = signal not available (SNA)";
CM_ SG_ 1297 RCM_a078_eventArmStatus "Restraint control module: a078 event arm status";
CM_ SG_ 1297 RCM_a078_eventFactoryMode "Restraint control module: a078 event factory mode";
CM_ SG_ 1297 RCM_a078_eventDiagEnabled "Restraint control module: a078 event diag enabled";
CM_ SG_ 1297 RCM_a078_eventDriveOrientation "Restraint control module: a078 event drive orientation";
CM_ SG_ 1297 RCM_a078_comOCS1PMIA "Restraint control module: a078 com OCS1 PMIA";
CM_ SG_ 1297 RCM_a078_comOCS1PChkSm "Restraint control module: a078 com OCS1 p chk sm";
CM_ SG_ 1297 RCM_a078_comOCS1PCntr "Restraint control module: a078 com OCS1 p cntr";
CM_ SG_ 1297 RCM_a078_eventIDFsignal "Restraint control module: a078 event ID fsignal";
CM_ SG_ 1297 RCM_a078_eventFrontLeftSeatbelt "Restraint control module: a078 event front left seatbelt";
CM_ SG_ 1297 RCM_a078_eventFrontRightSeatbelt "Restraint control module: a078 event front right seatbelt";
CM_ SG_ 1297 RCM_a078_eventVehicleSpeed "Restraint control module: a078 event vehicle speed";
CM_ SG_ 1297 RCM_a078_eventSteeringAngle "Restraint control module: a078 event steering angle";
CM_ SG_ 1297 RCM_a078_eventDriverBrakeApply "Restraint control module: a078 event driver brake apply; raw 3 = signal not available (SNA)";
CM_ SG_ 1297 RCM_a078_eventAccelPedalPos "Restraint control module: a078 event accel pedal pos; raw 255 = signal not available (SNA)";
CM_ SG_ 1297 RCM_a079_eventArmStatus "Restraint control module: a079 event arm status";
CM_ SG_ 1297 RCM_a079_eventFactoryMode "Restraint control module: a079 event factory mode";
CM_ SG_ 1297 RCM_a079_eventDiagEnabled "Restraint control module: a079 event diag enabled";
CM_ SG_ 1297 RCM_a079_eventDriveOrientation "Restraint control module: a079 event drive orientation";
CM_ SG_ 1297 RCM_a079_comOCS1DMIA "Restraint control module: a079 com OCS1 DMIA";
CM_ SG_ 1297 RCM_a079_comOCS1DChkSm "Restraint control module: a079 com OCS1 d chk sm";
CM_ SG_ 1297 RCM_a079_comOCS1DCntr "Restraint control module: a079 com OCS1 d cntr";
CM_ SG_ 1297 RCM_a079_eventIDFsignal "Restraint control module: a079 event ID fsignal";
CM_ SG_ 1297 RCM_a079_eventFrontLeftSeatbelt "Restraint control module: a079 event front left seatbelt";
CM_ SG_ 1297 RCM_a079_eventFrontRightSeatbelt "Restraint control module: a079 event front right seatbelt";
CM_ SG_ 1297 RCM_a079_eventVehicleSpeed "Restraint control module: a079 event vehicle speed";
CM_ SG_ 1297 RCM_a079_eventSteeringAngle "Restraint control module: a079 event steering angle";
CM_ SG_ 1297 RCM_a079_eventDriverBrakeApply "Restraint control module: a079 event driver brake apply; raw 3 = signal not available (SNA)";
CM_ SG_ 1297 RCM_a079_eventAccelPedalPos "Restraint control module: a079 event accel pedal pos; raw 255 = signal not available (SNA)";
CM_ SG_ 1297 RCM_a080_eventArmStatus "Restraint control module: a080 event arm status";
CM_ SG_ 1297 RCM_a080_eventFactoryMode "Restraint control module: a080 event factory mode";
CM_ SG_ 1297 RCM_a080_eventDiagEnabled "Restraint control module: a080 event diag enabled";
CM_ SG_ 1297 RCM_a080_eventDriveOrientation "Restraint control module: a080 event drive orientation";
CM_ SG_ 1297 RCM_a080_comGTWACSMIA "Restraint control module: a080 com GTWACSMIA";
CM_ SG_ 1297 RCM_a080_comGTWACSChkSm "Restraint control module: a080 com GTWACS chk sm";
CM_ SG_ 1297 RCM_a080_comGTWACSCntr "Restraint control module: a080 com GTWACS cntr";
CM_ SG_ 1297 RCM_a080_eventIDFsignal "Restraint control module: a080 event ID fsignal";
CM_ SG_ 1297 RCM_a080_eventFrontLeftSeatbelt "Restraint control module: a080 event front left seatbelt";
CM_ SG_ 1297 RCM_a080_eventFrontRightSeatbelt "Restraint control module: a080 event front right seatbelt";
CM_ SG_ 1297 RCM_a080_eventVehicleSpeed "Restraint control module: a080 event vehicle speed";
CM_ SG_ 1297 RCM_a080_eventSteeringAngle "Restraint control module: a080 event steering angle";
CM_ SG_ 1297 RCM_a080_eventDriverBrakeApply "Restraint control module: a080 event driver brake apply; raw 3 = signal not available (SNA)";
CM_ SG_ 1297 RCM_a080_eventAccelPedalPos "Restraint control module: a080 event accel pedal pos; raw 255 = signal not available (SNA)";
CM_ SG_ 1297 RCM_a083_eventArmStatus "Restraint control module: a083 event arm status";
CM_ SG_ 1297 RCM_a083_eventFactoryMode "Restraint control module: a083 event factory mode";
CM_ SG_ 1297 RCM_a083_eventDiagEnabled "Restraint control module: a083 event diag enabled";
CM_ SG_ 1297 RCM_a083_eventDriveOrientation "Restraint control module: a083 event drive orientation";
CM_ SG_ 1297 RCM_a083_comGTWCarStateMIA "Restraint control module: a083 com GTW car state MIA";
CM_ SG_ 1297 RCM_a083_eventIDFsignal "Restraint control module: a083 event ID fsignal";
CM_ SG_ 1297 RCM_a083_eventFrontLeftSeatbelt "Restraint control module: a083 event front left seatbelt";
CM_ SG_ 1297 RCM_a083_eventFrontRightSeatbelt "Restraint control module: a083 event front right seatbelt";
CM_ SG_ 1297 RCM_a083_eventVehicleSpeed "Restraint control module: a083 event vehicle speed";
CM_ SG_ 1297 RCM_a083_eventSteeringAngle "Restraint control module: a083 event steering angle";
CM_ SG_ 1297 RCM_a083_eventDriverBrakeApply "Restraint control module: a083 event driver brake apply; raw 3 = signal not available (SNA)";
CM_ SG_ 1297 RCM_a083_eventAccelPedalPos "Restraint control module: a083 event accel pedal pos; raw 255 = signal not available (SNA)";
CM_ SG_ 1297 RCM_a087_eventArmStatus "Restraint control module: a087 event arm status";
CM_ SG_ 1297 RCM_a087_eventFactoryMode "Restraint control module: a087 event factory mode";
CM_ SG_ 1297 RCM_a087_eventDiagEnabled "Restraint control module: a087 event diag enabled";
CM_ SG_ 1297 RCM_a087_eventDriveOrientation "Restraint control module: a087 event drive orientation";
CM_ SG_ 1297 RCM_a087_comChassisCANSilent "Restraint control module: a087 com chassis CAN silent";
CM_ SG_ 1297 RCM_a087_comPARTYCANSilent "Restraint control module: a087 com PARTYCAN silent";
CM_ SG_ 1297 RCM_a087_comUnusedCANSilent "Restraint control module: a087 com unused CAN silent";
CM_ SG_ 1297 RCM_a087_eventIDFsignal "Restraint control module: a087 event ID fsignal";
CM_ SG_ 1297 RCM_a087_eventFrontLeftSeatbelt "Restraint control module: a087 event front left seatbelt";
CM_ SG_ 1297 RCM_a087_eventFrontRightSeatbelt "Restraint control module: a087 event front right seatbelt";
CM_ SG_ 1297 RCM_a087_eventVehicleSpeed "Restraint control module: a087 event vehicle speed";
CM_ SG_ 1297 RCM_a087_eventSteeringAngle "Restraint control module: a087 event steering angle";
CM_ SG_ 1297 RCM_a087_eventDriverBrakeApply "Restraint control module: a087 event driver brake apply; raw 3 = signal not available (SNA)";
CM_ SG_ 1297 RCM_a087_eventAccelPedalPos "Restraint control module: a087 event accel pedal pos; raw 255 = signal not available (SNA)";
CM_ SG_ 1297 RCM_a088_eventArmStatus "Restraint control module: a088 event arm status";
CM_ SG_ 1297 RCM_a088_eventFactoryMode "Restraint control module: a088 event factory mode";
CM_ SG_ 1297 RCM_a088_eventDiagEnabled "Restraint control module: a088 event diag enabled";
CM_ SG_ 1297 RCM_a088_eventDriveOrientation "Restraint control module: a088 event drive orientation";
CM_ SG_ 1297 RCM_a088_comChassisCANPH2MIA "Restraint control module: a088 com chassis CANPH2 MIA";
CM_ SG_ 1297 RCM_a088_comChassisCANPH2ChkSm "Restraint control module: a088 com chassis CANPH2 chk sm";
CM_ SG_ 1297 RCM_a088_comChassisCANPH2Cntr "Restraint control module: a088 com chassis CANPH2 cntr";
CM_ SG_ 1297 RCM_a088_eventIDFsignal "Restraint control module: a088 event ID fsignal";
CM_ SG_ 1297 RCM_a088_eventFrontLeftSeatbelt "Restraint control module: a088 event front left seatbelt";
CM_ SG_ 1297 RCM_a088_eventFrontRightSeatbelt "Restraint control module: a088 event front right seatbelt";
CM_ SG_ 1297 RCM_a088_eventVehicleSpeed "Restraint control module: a088 event vehicle speed";
CM_ SG_ 1297 RCM_a088_eventSteeringAngle "Restraint control module: a088 event steering angle";
CM_ SG_ 1297 RCM_a088_eventDriverBrakeApply "Restraint control module: a088 event driver brake apply; raw 3 = signal not available (SNA)";
CM_ SG_ 1297 RCM_a088_eventAccelPedalPos "Restraint control module: a088 event accel pedal pos; raw 255 = signal not available (SNA)";
CM_ SG_ 1297 RCM_a089_eventArmStatus "Restraint control module: a089 event arm status";
CM_ SG_ 1297 RCM_a089_eventFactoryMode "Restraint control module: a089 event factory mode";
CM_ SG_ 1297 RCM_a089_eventDiagEnabled "Restraint control module: a089 event diag enabled";
CM_ SG_ 1297 RCM_a089_eventDriveOrientation "Restraint control module: a089 event drive orientation";
CM_ SG_ 1297 RCM_a089_comChassisCANPH3MIA "Restraint control module: a089 com chassis CANPH3 MIA";
CM_ SG_ 1297 RCM_a089_comChassisCANPH3ChkSm "Restraint control module: a089 com chassis CANPH3 chk sm";
CM_ SG_ 1297 RCM_a089_comChassisCANPH3Cntr "Restraint control module: a089 com chassis CANPH3 cntr";
CM_ SG_ 1297 RCM_a089_eventIDFsignal "Restraint control module: a089 event ID fsignal";
CM_ SG_ 1297 RCM_a089_eventFrontLeftSeatbelt "Restraint control module: a089 event front left seatbelt";
CM_ SG_ 1297 RCM_a089_eventFrontRightSeatbelt "Restraint control module: a089 event front right seatbelt";
CM_ SG_ 1297 RCM_a089_eventVehicleSpeed "Restraint control module: a089 event vehicle speed";
CM_ SG_ 1297 RCM_a089_eventSteeringAngle "Restraint control module: a089 event steering angle";
CM_ SG_ 1297 RCM_a089_eventDriverBrakeApply "Restraint control module: a089 event driver brake apply; raw 3 = signal not available (SNA)";
CM_ SG_ 1297 RCM_a089_eventAccelPedalPos "Restraint control module: a089 event accel pedal pos; raw 255 = signal not available (SNA)";
CM_ SG_ 1297 RCM_a090_eventArmStatus "Restraint control module: a090 event arm status";
CM_ SG_ 1297 RCM_a090_eventFactoryMode "Restraint control module: a090 event factory mode";
CM_ SG_ 1297 RCM_a090_eventDiagEnabled "Restraint control module: a090 event diag enabled";
CM_ SG_ 1297 RCM_a090_eventDriveOrientation "Restraint control module: a090 event drive orientation";
CM_ SG_ 1297 RCM_a090_comPartyCANBusOff "Restraint control module: a090 com party CAN bus off";
CM_ SG_ 1297 RCM_a090_eventIDFsignal "Restraint control module: a090 event ID fsignal";
CM_ SG_ 1297 RCM_a090_eventFrontLeftSeatbelt "Restraint control module: a090 event front left seatbelt";
CM_ SG_ 1297 RCM_a090_eventFrontRightSeatbelt "Restraint control module: a090 event front right seatbelt";
CM_ SG_ 1297 RCM_a090_eventVehicleSpeed "Restraint control module: a090 event vehicle speed";
CM_ SG_ 1297 RCM_a090_eventSteeringAngle "Restraint control module: a090 event steering angle";
CM_ SG_ 1297 RCM_a090_eventDriverBrakeApply "Restraint control module: a090 event driver brake apply; raw 3 = signal not available (SNA)";
CM_ SG_ 1297 RCM_a090_eventAccelPedalPos "Restraint control module: a090 event accel pedal pos; raw 255 = signal not available (SNA)";
CM_ SG_ 1297 RCM_a091_eventArmStatus "Restraint control module: a091 event arm status";
CM_ SG_ 1297 RCM_a091_eventFactoryMode "Restraint control module: a091 event factory mode";
CM_ SG_ 1297 RCM_a091_eventDiagEnabled "Restraint control module: a091 event diag enabled";
CM_ SG_ 1297 RCM_a091_eventDriveOrientation "Restraint control module: a091 event drive orientation";
CM_ SG_ 1297 RCM_a091_comEPAS3PStAnglInvlidQF "Restraint control module: a091 com EPAS3 p st angl invlid QF";
CM_ SG_ 1297 RCM_a091_comEPAS3PsysStatusMIA "Restraint control module: a091 com EPAS3 psys status MIA";
CM_ SG_ 1297 RCM_a091_comEPAS3PsysStatusChkSm "Restraint control module: a091 com EPAS3 psys status chk sm";
CM_ SG_ 1297 RCM_a091_comEPAS3PsysStatusCntr "Restraint control module: a091 com EPAS3 psys status cntr";
CM_ SG_ 1297 RCM_a091_eventIDFsignal "Restraint control module: a091 event ID fsignal";
CM_ SG_ 1297 RCM_a091_eventFrontLeftSeatbelt "Restraint control module: a091 event front left seatbelt";
CM_ SG_ 1297 RCM_a091_eventFrontRightSeatbelt "Restraint control module: a091 event front right seatbelt";
CM_ SG_ 1297 RCM_a091_eventVehicleSpeed "Restraint control module: a091 event vehicle speed";
CM_ SG_ 1297 RCM_a091_eventSteeringAngle "Restraint control module: a091 event steering angle";
CM_ SG_ 1297 RCM_a091_eventDriverBrakeApply "Restraint control module: a091 event driver brake apply; raw 3 = signal not available (SNA)";
CM_ SG_ 1297 RCM_a091_eventAccelPedalPos "Restraint control module: a091 event accel pedal pos; raw 255 = signal not available (SNA)";
CM_ SG_ 1297 RCM_a092_eventArmStatus "Restraint control module: a092 event arm status";
CM_ SG_ 1297 RCM_a092_eventFactoryMode "Restraint control module: a092 event factory mode";
CM_ SG_ 1297 RCM_a092_eventDiagEnabled "Restraint control module: a092 event diag enabled";
CM_ SG_ 1297 RCM_a092_eventDriveOrientation "Restraint control module: a092 event drive orientation";
CM_ SG_ 1297 RCM_a092_comDASSafetyFrontMIA "Restraint control module: a092 com DAS safety front MIA";
CM_ SG_ 1297 RCM_a092_comDASSafetyFrontChkSm "Restraint control module: a092 com DAS safety front chk sm";
CM_ SG_ 1297 RCM_a092_comDASSafetyFrontCntr "Restraint control module: a092 com DAS safety front cntr";
CM_ SG_ 1297 RCM_a092_eventIDFsignal "Restraint control module: a092 event ID fsignal";
CM_ SG_ 1297 RCM_a092_eventFrontLeftSeatbelt "Restraint control module: a092 event front left seatbelt";
CM_ SG_ 1297 RCM_a092_eventFrontRightSeatbelt "Restraint control module: a092 event front right seatbelt";
CM_ SG_ 1297 RCM_a092_eventVehicleSpeed "Restraint control module: a092 event vehicle speed";
CM_ SG_ 1297 RCM_a092_eventSteeringAngle "Restraint control module: a092 event steering angle";
CM_ SG_ 1297 RCM_a092_eventDriverBrakeApply "Restraint control module: a092 event driver brake apply; raw 3 = signal not available (SNA)";
CM_ SG_ 1297 RCM_a092_eventAccelPedalPos "Restraint control module: a092 event accel pedal pos; raw 255 = signal not available (SNA)";
CM_ SG_ 1297 RCM_a093_eventArmStatus "Restraint control module: a093 event arm status";
CM_ SG_ 1297 RCM_a093_eventFactoryMode "Restraint control module: a093 event factory mode";
CM_ SG_ 1297 RCM_a093_eventDiagEnabled "Restraint control module: a093 event diag enabled";
CM_ SG_ 1297 RCM_a093_eventDriveOrientation "Restraint control module: a093 event drive orientation";
CM_ SG_ 1297 RCM_a093_comVCLEFTStatusMIA "Restraint control module: a093 com VCLEFT status MIA";
CM_ SG_ 1297 RCM_a093_comVCLEFTStatusChkSm "Restraint control module: a093 com VCLEFT status chk sm";
CM_ SG_ 1297 RCM_a093_comVCLEFTStatusCntr "Restraint control module: a093 com VCLEFT status cntr";
CM_ SG_ 1297 RCM_a093_bucklSwVCFrontLeftFault "Restraint control module: a093 buckl sw VC front left fault";
CM_ SG_ 1297 RCM_a093_bucklSwVCRearLeftFault "Restraint control module: a093 buckl sw VC rear left fault";
CM_ SG_ 1297 RCM_a093_eventIDFsignal "Restraint control module: a093 event ID fsignal";
CM_ SG_ 1297 RCM_a093_eventFrontLeftSeatbelt "Restraint control module: a093 event front left seatbelt";
CM_ SG_ 1297 RCM_a093_eventFrontRightSeatbelt "Restraint control module: a093 event front right seatbelt";
CM_ SG_ 1297 RCM_a093_eventVehicleSpeed "Restraint control module: a093 event vehicle speed";
CM_ SG_ 1297 RCM_a093_eventSteeringAngle "Restraint control module: a093 event steering angle";
CM_ SG_ 1297 RCM_a093_eventDriverBrakeApply "Restraint control module: a093 event driver brake apply; raw 3 = signal not available (SNA)";
CM_ SG_ 1297 RCM_a093_eventAccelPedalPos "Restraint control module: a093 event accel pedal pos; raw 255 = signal not available (SNA)";
CM_ SG_ 1297 RCM_a094_eventArmStatus "Restraint control module: a094 event arm status";
CM_ SG_ 1297 RCM_a094_eventFactoryMode "Restraint control module: a094 event factory mode";
CM_ SG_ 1297 RCM_a094_eventDiagEnabled "Restraint control module: a094 event diag enabled";
CM_ SG_ 1297 RCM_a094_eventDriveOrientation "Restraint control module: a094 event drive orientation";
CM_ SG_ 1297 RCM_a094_comVCRIGHTStatusMIA "Restraint control module: a094 com VCRIGHT status MIA";
CM_ SG_ 1297 RCM_a094_comVCRIGHTStatusChkSm "Restraint control module: a094 com VCRIGHT status chk sm";
CM_ SG_ 1297 RCM_a094_comVCRIGHTStatusCntr "Restraint control module: a094 com VCRIGHT status cntr";
CM_ SG_ 1297 RCM_a094_bucklSwVCFrontRghtFault "Restraint control module: a094 buckl sw VC front rght fault";
CM_ SG_ 1297 RCM_a094_bucklSwVCRearRghtFault "Restraint control module: a094 buckl sw VC rear rght fault";
CM_ SG_ 1297 RCM_a094_bucklSwVCRearCnterFault "Restraint control module: a094 buckl sw VC rear cnter fault";
CM_ SG_ 1297 RCM_a094_eventIDFsignal "Restraint control module: a094 event ID fsignal";
CM_ SG_ 1297 RCM_a094_eventFrontLeftSeatbelt "Restraint control module: a094 event front left seatbelt";
CM_ SG_ 1297 RCM_a094_eventFrontRightSeatbelt "Restraint control module: a094 event front right seatbelt";
CM_ SG_ 1297 RCM_a094_eventVehicleSpeed "Restraint control module: a094 event vehicle speed";
CM_ SG_ 1297 RCM_a094_eventSteeringAngle "Restraint control module: a094 event steering angle";
CM_ SG_ 1297 RCM_a094_eventDriverBrakeApply "Restraint control module: a094 event driver brake apply; raw 3 = signal not available (SNA)";
CM_ SG_ 1297 RCM_a094_eventAccelPedalPos "Restraint control module: a094 event accel pedal pos; raw 255 = signal not available (SNA)";
CM_ SG_ 1297 RCM_a101_eventArmStatus "Restraint control module: a101 event arm status";
CM_ SG_ 1297 RCM_a101_eventFactoryMode "Restraint control module: a101 event factory mode";
CM_ SG_ 1297 RCM_a101_eventDiagEnabled "Restraint control module: a101 event diag enabled";
CM_ SG_ 1297 RCM_a101_eventDriveOrientation "Restraint control module: a101 event drive orientation";
CM_ SG_ 1297 RCM_a101_idfMisuseMonitoringErr "Restraint control module: a101 idf misuse monitoring err";
CM_ SG_ 1297 RCM_a101_idfEnviMonitoringError "Restraint control module: a101 idf envi monitoring error";
CM_ SG_ 1297 RCM_a101_idfEnviMonitoringEvent "Restraint control module: a101 idf envi monitoring event";
CM_ SG_ 1297 RCM_a101_eventIDFsignal "Restraint control module: a101 event ID fsignal";
CM_ SG_ 1297 RCM_a101_eventFrontLeftSeatbelt "Restraint control module: a101 event front left seatbelt";
CM_ SG_ 1297 RCM_a101_eventFrontRightSeatbelt "Restraint control module: a101 event front right seatbelt";
CM_ SG_ 1297 RCM_a101_eventVehicleSpeed "Restraint control module: a101 event vehicle speed";
CM_ SG_ 1297 RCM_a101_eventSteeringAngle "Restraint control module: a101 event steering angle";
CM_ SG_ 1297 RCM_a101_eventDriverBrakeApply "Restraint control module: a101 event driver brake apply; raw 3 = signal not available (SNA)";
CM_ SG_ 1297 RCM_a101_eventAccelPedalPos "Restraint control module: a101 event accel pedal pos; raw 255 = signal not available (SNA)";
CM_ SG_ 1297 RCM_a102_eventArmStatus "Restraint control module: a102 event arm status";
CM_ SG_ 1297 RCM_a102_eventFactoryMode "Restraint control module: a102 event factory mode";
CM_ SG_ 1297 RCM_a102_eventDiagEnabled "Restraint control module: a102 event diag enabled";
CM_ SG_ 1297 RCM_a102_eventDriveOrientation "Restraint control module: a102 event drive orientation";
CM_ SG_ 1297 RCM_a102_imuYawR8OffCompPosLife "Restraint control module: a102 imu yaw R8 off comp pos life";
CM_ SG_ 1297 RCM_a102_imuYawR8OffCompNegLife "Restraint control module: a102 imu yaw R8 off comp neg life";
CM_ SG_ 1297 RCM_a102_imuYawR8OffCompPosFLDC "Restraint control module: a102 imu yaw R8 off comp pos FLDC";
CM_ SG_ 1297 RCM_a102_imuYawR8OffCompNegFLDC "Restraint control module: a102 imu yaw R8 off comp neg FLDC";
CM_ SG_ 1297 RCM_a102_imuYawR8OffCompPosSLDC "Restraint control module: a102 imu yaw R8 off comp pos SLDC";
CM_ SG_ 1297 RCM_a102_imuYawR8OffCompNegSLDC "Restraint control module: a102 imu yaw R8 off comp neg SLDC";
CM_ SG_ 1297 RCM_a102_eventIDFsignal "Restraint control module: a102 event ID fsignal";
CM_ SG_ 1297 RCM_a102_eventFrontLeftSeatbelt "Restraint control module: a102 event front left seatbelt";
CM_ SG_ 1297 RCM_a102_eventFrontRightSeatbelt "Restraint control module: a102 event front right seatbelt";
CM_ SG_ 1297 RCM_a102_eventVehicleSpeed "Restraint control module: a102 event vehicle speed";
CM_ SG_ 1297 RCM_a102_eventSteeringAngle "Restraint control module: a102 event steering angle";
CM_ SG_ 1297 RCM_a102_eventDriverBrakeApply "Restraint control module: a102 event driver brake apply; raw 3 = signal not available (SNA)";
CM_ SG_ 1297 RCM_a102_eventAccelPedalPos "Restraint control module: a102 event accel pedal pos; raw 255 = signal not available (SNA)";
CM_ SG_ 1297 RCM_a103_eventArmStatus "Restraint control module: a103 event arm status";
CM_ SG_ 1297 RCM_a103_eventFactoryMode "Restraint control module: a103 event factory mode";
CM_ SG_ 1297 RCM_a103_eventDiagEnabled "Restraint control module: a103 event diag enabled";
CM_ SG_ 1297 RCM_a103_eventDriveOrientation "Restraint control module: a103 event drive orientation";
CM_ SG_ 1297 RCM_a103_imuPtchR8OffCompPosLife "Restraint control module: a103 imu ptch R8 off comp pos life";
CM_ SG_ 1297 RCM_a103_imuPtchR8OffCompNegLife "Restraint control module: a103 imu ptch R8 off comp neg life";
CM_ SG_ 1297 RCM_a103_imuPtchR8OffCompPosFLDC "Restraint control module: a103 imu ptch R8 off comp pos FLDC";
CM_ SG_ 1297 RCM_a103_imuPtchR8OffCompNegFLDC "Restraint control module: a103 imu ptch R8 off comp neg FLDC";
CM_ SG_ 1297 RCM_a103_imuPtchR8OffCompPosSLDC "Restraint control module: a103 imu ptch R8 off comp pos SLDC";
CM_ SG_ 1297 RCM_a103_imuPtchR8OffCompNegSLDC "Restraint control module: a103 imu ptch R8 off comp neg SLDC";
CM_ SG_ 1297 RCM_a103_eventIDFsignal "Restraint control module: a103 event ID fsignal";
CM_ SG_ 1297 RCM_a103_eventFrontLeftSeatbelt "Restraint control module: a103 event front left seatbelt";
CM_ SG_ 1297 RCM_a103_eventFrontRightSeatbelt "Restraint control module: a103 event front right seatbelt";
CM_ SG_ 1297 RCM_a103_eventVehicleSpeed "Restraint control module: a103 event vehicle speed";
CM_ SG_ 1297 RCM_a103_eventSteeringAngle "Restraint control module: a103 event steering angle";
CM_ SG_ 1297 RCM_a103_eventDriverBrakeApply "Restraint control module: a103 event driver brake apply; raw 3 = signal not available (SNA)";
CM_ SG_ 1297 RCM_a103_eventAccelPedalPos "Restraint control module: a103 event accel pedal pos; raw 255 = signal not available (SNA)";
CM_ SG_ 1297 RCM_a104_eventArmStatus "Restraint control module: a104 event arm status";
CM_ SG_ 1297 RCM_a104_eventFactoryMode "Restraint control module: a104 event factory mode";
CM_ SG_ 1297 RCM_a104_eventDiagEnabled "Restraint control module: a104 event diag enabled";
CM_ SG_ 1297 RCM_a104_eventDriveOrientation "Restraint control module: a104 event drive orientation";
CM_ SG_ 1297 RCM_a104_imuRollR8OffCompPosLife "Restraint control module: a104 imu roll R8 off comp pos life";
CM_ SG_ 1297 RCM_a104_imuRollR8OffCompNegLife "Restraint control module: a104 imu roll R8 off comp neg life";
CM_ SG_ 1297 RCM_a104_imuRollR8OffCompPosFLDC "Restraint control module: a104 imu roll R8 off comp pos FLDC";
CM_ SG_ 1297 RCM_a104_imuRollR8OffCompNegFLDC "Restraint control module: a104 imu roll R8 off comp neg FLDC";
CM_ SG_ 1297 RCM_a104_imuRollR8OffCompPosSLDC "Restraint control module: a104 imu roll R8 off comp pos SLDC";
CM_ SG_ 1297 RCM_a104_imuRollR8OffCompNegSLDC "Restraint control module: a104 imu roll R8 off comp neg SLDC";
CM_ SG_ 1297 RCM_a104_eventIDFsignal "Restraint control module: a104 event ID fsignal";
CM_ SG_ 1297 RCM_a104_eventFrontLeftSeatbelt "Restraint control module: a104 event front left seatbelt";
CM_ SG_ 1297 RCM_a104_eventFrontRightSeatbelt "Restraint control module: a104 event front right seatbelt";
CM_ SG_ 1297 RCM_a104_eventVehicleSpeed "Restraint control module: a104 event vehicle speed";
CM_ SG_ 1297 RCM_a104_eventSteeringAngle "Restraint control module: a104 event steering angle";
CM_ SG_ 1297 RCM_a104_eventDriverBrakeApply "Restraint control module: a104 event driver brake apply; raw 3 = signal not available (SNA)";
CM_ SG_ 1297 RCM_a104_eventAccelPedalPos "Restraint control module: a104 event accel pedal pos; raw 255 = signal not available (SNA)";
CM_ SG_ 1297 RCM_a105_eventArmStatus "Restraint control module: a105 event arm status";
CM_ SG_ 1297 RCM_a105_eventFactoryMode "Restraint control module: a105 event factory mode";
CM_ SG_ 1297 RCM_a105_eventDiagEnabled "Restraint control module: a105 event diag enabled";
CM_ SG_ 1297 RCM_a105_eventDriveOrientation "Restraint control module: a105 event drive orientation";
CM_ SG_ 1297 RCM_a105_imuLongAOffCompPosLife "Restraint control module: a105 imu long a off comp pos life";
CM_ SG_ 1297 RCM_a105_imuLongAOffCompNegLife "Restraint control module: a105 imu long a off comp neg life";
CM_ SG_ 1297 RCM_a105_imuLongAOffCompPosFLDC "Restraint control module: a105 imu long a off comp pos FLDC";
CM_ SG_ 1297 RCM_a105_imuLongAOffCompNegFLDC "Restraint control module: a105 imu long a off comp neg FLDC";
CM_ SG_ 1297 RCM_a105_imuLongAOffCompPosSLDC "Restraint control module: a105 imu long a off comp pos SLDC";
CM_ SG_ 1297 RCM_a105_imuLongAOffCompNegSLDC "Restraint control module: a105 imu long a off comp neg SLDC";
CM_ SG_ 1297 RCM_a105_eventIDFsignal "Restraint control module: a105 event ID fsignal";
CM_ SG_ 1297 RCM_a105_eventFrontLeftSeatbelt "Restraint control module: a105 event front left seatbelt";
CM_ SG_ 1297 RCM_a105_eventFrontRightSeatbelt "Restraint control module: a105 event front right seatbelt";
CM_ SG_ 1297 RCM_a105_eventVehicleSpeed "Restraint control module: a105 event vehicle speed";
CM_ SG_ 1297 RCM_a105_eventSteeringAngle "Restraint control module: a105 event steering angle";
CM_ SG_ 1297 RCM_a105_eventDriverBrakeApply "Restraint control module: a105 event driver brake apply; raw 3 = signal not available (SNA)";
CM_ SG_ 1297 RCM_a105_eventAccelPedalPos "Restraint control module: a105 event accel pedal pos; raw 255 = signal not available (SNA)";
CM_ SG_ 1297 RCM_a106_eventArmStatus "Restraint control module: a106 event arm status";
CM_ SG_ 1297 RCM_a106_eventFactoryMode "Restraint control module: a106 event factory mode";
CM_ SG_ 1297 RCM_a106_eventDiagEnabled "Restraint control module: a106 event diag enabled";
CM_ SG_ 1297 RCM_a106_eventDriveOrientation "Restraint control module: a106 event drive orientation";
CM_ SG_ 1297 RCM_a106_imuLatAcOffCompPosLife "Restraint control module: a106 imu lat ac off comp pos life";
CM_ SG_ 1297 RCM_a106_imuLatAcOffCompNegLife "Restraint control module: a106 imu lat ac off comp neg life";
CM_ SG_ 1297 RCM_a106_imuLatAcOffCompPosFLDC "Restraint control module: a106 imu lat ac off comp pos FLDC";
CM_ SG_ 1297 RCM_a106_imuLatAcOffCompNegFLDC "Restraint control module: a106 imu lat ac off comp neg FLDC";
CM_ SG_ 1297 RCM_a106_imuLatAcOffCompPosSLDC "Restraint control module: a106 imu lat ac off comp pos SLDC";
CM_ SG_ 1297 RCM_a106_imuLatAcOffCompNegSLDC "Restraint control module: a106 imu lat ac off comp neg SLDC";
CM_ SG_ 1297 RCM_a106_eventIDFsignal "Restraint control module: a106 event ID fsignal";
CM_ SG_ 1297 RCM_a106_eventFrontLeftSeatbelt "Restraint control module: a106 event front left seatbelt";
CM_ SG_ 1297 RCM_a106_eventFrontRightSeatbelt "Restraint control module: a106 event front right seatbelt";
CM_ SG_ 1297 RCM_a106_eventVehicleSpeed "Restraint control module: a106 event vehicle speed";
CM_ SG_ 1297 RCM_a106_eventSteeringAngle "Restraint control module: a106 event steering angle";
CM_ SG_ 1297 RCM_a106_eventDriverBrakeApply "Restraint control module: a106 event driver brake apply; raw 3 = signal not available (SNA)";
CM_ SG_ 1297 RCM_a106_eventAccelPedalPos "Restraint control module: a106 event accel pedal pos; raw 255 = signal not available (SNA)";
CM_ SG_ 1297 RCM_a107_eventArmStatus "Restraint control module: a107 event arm status";
CM_ SG_ 1297 RCM_a107_eventFactoryMode "Restraint control module: a107 event factory mode";
CM_ SG_ 1297 RCM_a107_eventDiagEnabled "Restraint control module: a107 event diag enabled";
CM_ SG_ 1297 RCM_a107_eventDriveOrientation "Restraint control module: a107 event drive orientation";
CM_ SG_ 1297 RCM_a107_imuVertAOffCompPosLife "Restraint control module: a107 imu vert a off comp pos life";
CM_ SG_ 1297 RCM_a107_imuVertAOffCompNegLife "Restraint control module: a107 imu vert a off comp neg life";
CM_ SG_ 1297 RCM_a107_imuVertAOffCompPosFLDC "Restraint control module: a107 imu vert a off comp pos FLDC";
CM_ SG_ 1297 RCM_a107_imuVertAOffCompNegFLDC "Restraint control module: a107 imu vert a off comp neg FLDC";
CM_ SG_ 1297 RCM_a107_imuVertAOffCompPosSLDC "Restraint control module: a107 imu vert a off comp pos SLDC";
CM_ SG_ 1297 RCM_a107_imuVertAOffCompNegSLDC "Restraint control module: a107 imu vert a off comp neg SLDC";
CM_ SG_ 1297 RCM_a107_eventIDFsignal "Restraint control module: a107 event ID fsignal";
CM_ SG_ 1297 RCM_a107_eventFrontLeftSeatbelt "Restraint control module: a107 event front left seatbelt";
CM_ SG_ 1297 RCM_a107_eventFrontRightSeatbelt "Restraint control module: a107 event front right seatbelt";
CM_ SG_ 1297 RCM_a107_eventVehicleSpeed "Restraint control module: a107 event vehicle speed";
CM_ SG_ 1297 RCM_a107_eventSteeringAngle "Restraint control module: a107 event steering angle";
CM_ SG_ 1297 RCM_a107_eventDriverBrakeApply "Restraint control module: a107 event driver brake apply; raw 3 = signal not available (SNA)";
CM_ SG_ 1297 RCM_a107_eventAccelPedalPos "Restraint control module: a107 event accel pedal pos; raw 255 = signal not available (SNA)";
CM_ SG_ 1297 RCM_a108_eventArmStatus "Restraint control module: a108 event arm status";
CM_ SG_ 1297 RCM_a108_eventFactoryMode "Restraint control module: a108 event factory mode";
CM_ SG_ 1297 RCM_a108_eventDiagEnabled "Restraint control module: a108 event diag enabled";
CM_ SG_ 1297 RCM_a108_eventDriveOrientation "Restraint control module: a108 event drive orientation";
CM_ SG_ 1297 RCM_a108_crashAlgoWakeupSig "Restraint control module: a108 crash algo wakeup sig";
CM_ SG_ 1297 RCM_a108_eventIDFsignal "Restraint control module: a108 event ID fsignal";
CM_ SG_ 1297 RCM_a108_eventFrontLeftSeatbelt "Restraint control module: a108 event front left seatbelt";
CM_ SG_ 1297 RCM_a108_eventFrontRightSeatbelt "Restraint control module: a108 event front right seatbelt";
CM_ SG_ 1297 RCM_a108_eventVehicleSpeed "Restraint control module: a108 event vehicle speed";
CM_ SG_ 1297 RCM_a108_eventSteeringAngle "Restraint control module: a108 event steering angle";
CM_ SG_ 1297 RCM_a108_eventDriverBrakeApply "Restraint control module: a108 event driver brake apply; raw 3 = signal not available (SNA)";
CM_ SG_ 1297 RCM_a108_eventAccelPedalPos "Restraint control module: a108 event accel pedal pos; raw 255 = signal not available (SNA)";
CM_ SG_ 1297 RCM_a109_eventArmStatus "Restraint control module: a109 event arm status";
CM_ SG_ 1297 RCM_a109_eventFactoryMode "Restraint control module: a109 event factory mode";
CM_ SG_ 1297 RCM_a109_eventDiagEnabled "Restraint control module: a109 event diag enabled";
CM_ SG_ 1297 RCM_a109_eventDriveOrientation "Restraint control module: a109 event drive orientation";
CM_ SG_ 1297 RCM_a109_immunityThrsholdCrossed "Restraint control module: a109 immunity thrshold crossed";
CM_ SG_ 1297 RCM_a109_eventIDFsignal "Restraint control module: a109 event ID fsignal";
CM_ SG_ 1297 RCM_a109_eventFrontLeftSeatbelt "Restraint control module: a109 event front left seatbelt";
CM_ SG_ 1297 RCM_a109_eventFrontRightSeatbelt "Restraint control module: a109 event front right seatbelt";
CM_ SG_ 1297 RCM_a109_eventVehicleSpeed "Restraint control module: a109 event vehicle speed";
CM_ SG_ 1297 RCM_a109_eventSteeringAngle "Restraint control module: a109 event steering angle";
CM_ SG_ 1297 RCM_a109_eventDriverBrakeApply "Restraint control module: a109 event driver brake apply; raw 3 = signal not available (SNA)";
CM_ SG_ 1297 RCM_a109_eventAccelPedalPos "Restraint control module: a109 event accel pedal pos; raw 255 = signal not available (SNA)";
CM_ SG_ 1297 RCM_a110_eventArmStatus "Restraint control module: a110 event arm status";
CM_ SG_ 1297 RCM_a110_eventFactoryMode "Restraint control module: a110 event factory mode";
CM_ SG_ 1297 RCM_a110_eventDiagEnabled "Restraint control module: a110 event diag enabled";
CM_ SG_ 1297 RCM_a110_eventDriveOrientation "Restraint control module: a110 event drive orientation";
CM_ SG_ 1297 RCM_a110_inFactoryMode "Restraint control module: a110 in factory mode";
CM_ SG_ 1297 RCM_a110_eventIDFsignal "Restraint control module: a110 event ID fsignal";
CM_ SG_ 1297 RCM_a110_eventFrontLeftSeatbelt "Restraint control module: a110 event front left seatbelt";
CM_ SG_ 1297 RCM_a110_eventFrontRightSeatbelt "Restraint control module: a110 event front right seatbelt";
CM_ SG_ 1297 RCM_a110_eventVehicleSpeed "Restraint control module: a110 event vehicle speed";
CM_ SG_ 1297 RCM_a110_eventSteeringAngle "Restraint control module: a110 event steering angle";
CM_ SG_ 1297 RCM_a110_eventDriverBrakeApply "Restraint control module: a110 event driver brake apply; raw 3 = signal not available (SNA)";
CM_ SG_ 1297 RCM_a110_eventAccelPedalPos "Restraint control module: a110 event accel pedal pos; raw 255 = signal not available (SNA)";
CM_ SG_ 1297 RCM_a112_eventArmStatus "Restraint control module: a112 event arm status";
CM_ SG_ 1297 RCM_a112_eventFactoryMode "Restraint control module: a112 event factory mode";
CM_ SG_ 1297 RCM_a112_eventDiagEnabled "Restraint control module: a112 event diag enabled";
CM_ SG_ 1297 RCM_a112_eventDriveOrientation "Restraint control module: a112 event drive orientation";
CM_ SG_ 1297 RCM_a112_imuYawR8SnsrMonitTmp "Restraint control module: a112 imu yaw R8 snsr monit tmp";
CM_ SG_ 1297 RCM_a112_imuYawR8SnsrMonitPerm "Restraint control module: a112 imu yaw R8 snsr monit perm";
CM_ SG_ 1297 RCM_a112_imuYawR8ChnlMonitTmp "Restraint control module: a112 imu yaw R8 chnl monit tmp";
CM_ SG_ 1297 RCM_a112_imuYawR8ChnlMonitPerm "Restraint control module: a112 imu yaw R8 chnl monit perm";
CM_ SG_ 1297 RCM_a112_eventIDFsignal "Restraint control module: a112 event ID fsignal";
CM_ SG_ 1297 RCM_a112_eventFrontLeftSeatbelt "Restraint control module: a112 event front left seatbelt";
CM_ SG_ 1297 RCM_a112_eventFrontRightSeatbelt "Restraint control module: a112 event front right seatbelt";
CM_ SG_ 1297 RCM_a112_eventVehicleSpeed "Restraint control module: a112 event vehicle speed";
CM_ SG_ 1297 RCM_a112_eventSteeringAngle "Restraint control module: a112 event steering angle";
CM_ SG_ 1297 RCM_a112_eventDriverBrakeApply "Restraint control module: a112 event driver brake apply; raw 3 = signal not available (SNA)";
CM_ SG_ 1297 RCM_a112_eventAccelPedalPos "Restraint control module: a112 event accel pedal pos; raw 255 = signal not available (SNA)";
CM_ SG_ 1297 RCM_a113_eventArmStatus "Restraint control module: a113 event arm status";
CM_ SG_ 1297 RCM_a113_eventFactoryMode "Restraint control module: a113 event factory mode";
CM_ SG_ 1297 RCM_a113_eventDiagEnabled "Restraint control module: a113 event diag enabled";
CM_ SG_ 1297 RCM_a113_eventDriveOrientation "Restraint control module: a113 event drive orientation";
CM_ SG_ 1297 RCM_a113_imuPitchR8SnsrMonitTmp "Restraint control module: a113 imu pitch R8 snsr monit tmp";
CM_ SG_ 1297 RCM_a113_imuPitchR8SnsrMonitPerm "Restraint control module: a113 imu pitch R8 snsr monit perm";
CM_ SG_ 1297 RCM_a113_imuPitchR8ChnlMonitTmp "Restraint control module: a113 imu pitch R8 chnl monit tmp";
CM_ SG_ 1297 RCM_a113_imuPitchR8ChnlMonitPerm "Restraint control module: a113 imu pitch R8 chnl monit perm";
CM_ SG_ 1297 RCM_a113_eventIDFsignal "Restraint control module: a113 event ID fsignal";
CM_ SG_ 1297 RCM_a113_eventFrontLeftSeatbelt "Restraint control module: a113 event front left seatbelt";
CM_ SG_ 1297 RCM_a113_eventFrontRightSeatbelt "Restraint control module: a113 event front right seatbelt";
CM_ SG_ 1297 RCM_a113_eventVehicleSpeed "Restraint control module: a113 event vehicle speed";
CM_ SG_ 1297 RCM_a113_eventSteeringAngle "Restraint control module: a113 event steering angle";
CM_ SG_ 1297 RCM_a113_eventDriverBrakeApply "Restraint control module: a113 event driver brake apply; raw 3 = signal not available (SNA)";
CM_ SG_ 1297 RCM_a113_eventAccelPedalPos "Restraint control module: a113 event accel pedal pos; raw 255 = signal not available (SNA)";
CM_ SG_ 1297 RCM_a114_eventArmStatus "Restraint control module: a114 event arm status";
CM_ SG_ 1297 RCM_a114_eventFactoryMode "Restraint control module: a114 event factory mode";
CM_ SG_ 1297 RCM_a114_eventDiagEnabled "Restraint control module: a114 event diag enabled";
CM_ SG_ 1297 RCM_a114_eventDriveOrientation "Restraint control module: a114 event drive orientation";
CM_ SG_ 1297 RCM_a114_imuRollR8SnsrMonitTmp "Restraint control module: a114 imu roll R8 snsr monit tmp";
CM_ SG_ 1297 RCM_a114_imuRollR8SnsrMonitPerm "Restraint control module: a114 imu roll R8 snsr monit perm";
CM_ SG_ 1297 RCM_a114_imuRollR8ChnlMonitTmp "Restraint control module: a114 imu roll R8 chnl monit tmp";
CM_ SG_ 1297 RCM_a114_imuRollR8ChnlMonitPerm "Restraint control module: a114 imu roll R8 chnl monit perm";
CM_ SG_ 1297 RCM_a114_eventIDFsignal "Restraint control module: a114 event ID fsignal";
CM_ SG_ 1297 RCM_a114_eventFrontLeftSeatbelt "Restraint control module: a114 event front left seatbelt";
CM_ SG_ 1297 RCM_a114_eventFrontRightSeatbelt "Restraint control module: a114 event front right seatbelt";
CM_ SG_ 1297 RCM_a114_eventVehicleSpeed "Restraint control module: a114 event vehicle speed";
CM_ SG_ 1297 RCM_a114_eventSteeringAngle "Restraint control module: a114 event steering angle";
CM_ SG_ 1297 RCM_a114_eventDriverBrakeApply "Restraint control module: a114 event driver brake apply; raw 3 = signal not available (SNA)";
CM_ SG_ 1297 RCM_a114_eventAccelPedalPos "Restraint control module: a114 event accel pedal pos; raw 255 = signal not available (SNA)";
CM_ SG_ 1297 RCM_a115_eventArmStatus "Restraint control module: a115 event arm status";
CM_ SG_ 1297 RCM_a115_eventFactoryMode "Restraint control module: a115 event factory mode";
CM_ SG_ 1297 RCM_a115_eventDiagEnabled "Restraint control module: a115 event diag enabled";
CM_ SG_ 1297 RCM_a115_eventDriveOrientation "Restraint control module: a115 event drive orientation";
CM_ SG_ 1297 RCM_a115_imuLinAccChnlMonitTmp "Restraint control module: a115 imu lin acc chnl monit tmp";
CM_ SG_ 1297 RCM_a115_imuLinAccChnlMonitPerm "Restraint control module: a115 imu lin acc chnl monit perm";
CM_ SG_ 1297 RCM_a115_eventIDFsignal "Restraint control module: a115 event ID fsignal";
CM_ SG_ 1297 RCM_a115_eventFrontLeftSeatbelt "Restraint control module: a115 event front left seatbelt";
CM_ SG_ 1297 RCM_a115_eventFrontRightSeatbelt "Restraint control module: a115 event front right seatbelt";
CM_ SG_ 1297 RCM_a115_eventVehicleSpeed "Restraint control module: a115 event vehicle speed";
CM_ SG_ 1297 RCM_a115_eventSteeringAngle "Restraint control module: a115 event steering angle";
CM_ SG_ 1297 RCM_a115_eventDriverBrakeApply "Restraint control module: a115 event driver brake apply; raw 3 = signal not available (SNA)";
CM_ SG_ 1297 RCM_a115_eventAccelPedalPos "Restraint control module: a115 event accel pedal pos; raw 255 = signal not available (SNA)";
CM_ SG_ 1297 RCM_a116_eventArmStatus "Restraint control module: a116 event arm status";
CM_ SG_ 1297 RCM_a116_eventFactoryMode "Restraint control module: a116 event factory mode";
CM_ SG_ 1297 RCM_a116_eventDiagEnabled "Restraint control module: a116 event diag enabled";
CM_ SG_ 1297 RCM_a116_eventDriveOrientation "Restraint control module: a116 event drive orientation";
CM_ SG_ 1297 RCM_a116_imuLatAccChnlMonitTmp "Restraint control module: a116 imu lat acc chnl monit tmp";
CM_ SG_ 1297 RCM_a116_imuLatAccChnlMonitPerm "Restraint control module: a116 imu lat acc chnl monit perm";
CM_ SG_ 1297 RCM_a116_eventIDFsignal "Restraint control module: a116 event ID fsignal";
CM_ SG_ 1297 RCM_a116_eventFrontLeftSeatbelt "Restraint control module: a116 event front left seatbelt";
CM_ SG_ 1297 RCM_a116_eventFrontRightSeatbelt "Restraint control module: a116 event front right seatbelt";
CM_ SG_ 1297 RCM_a116_eventVehicleSpeed "Restraint control module: a116 event vehicle speed";
CM_ SG_ 1297 RCM_a116_eventSteeringAngle "Restraint control module: a116 event steering angle";
CM_ SG_ 1297 RCM_a116_eventDriverBrakeApply "Restraint control module: a116 event driver brake apply; raw 3 = signal not available (SNA)";
CM_ SG_ 1297 RCM_a116_eventAccelPedalPos "Restraint control module: a116 event accel pedal pos; raw 255 = signal not available (SNA)";
CM_ SG_ 1297 RCM_a117_eventArmStatus "Restraint control module: a117 event arm status";
CM_ SG_ 1297 RCM_a117_eventFactoryMode "Restraint control module: a117 event factory mode";
CM_ SG_ 1297 RCM_a117_eventDiagEnabled "Restraint control module: a117 event diag enabled";
CM_ SG_ 1297 RCM_a117_eventDriveOrientation "Restraint control module: a117 event drive orientation";
CM_ SG_ 1297 RCM_a117_imuZaccelChnlMonitTmp "Restraint control module: a117 imu zaccel chnl monit tmp";
CM_ SG_ 1297 RCM_a117_imuZaccelChnlMonitPerm "Restraint control module: a117 imu zaccel chnl monit perm";
CM_ SG_ 1297 RCM_a117_eventIDFsignal "Restraint control module: a117 event ID fsignal";
CM_ SG_ 1297 RCM_a117_eventFrontLeftSeatbelt "Restraint control module: a117 event front left seatbelt";
CM_ SG_ 1297 RCM_a117_eventFrontRightSeatbelt "Restraint control module: a117 event front right seatbelt";
CM_ SG_ 1297 RCM_a117_eventVehicleSpeed "Restraint control module: a117 event vehicle speed";
CM_ SG_ 1297 RCM_a117_eventSteeringAngle "Restraint control module: a117 event steering angle";
CM_ SG_ 1297 RCM_a117_eventDriverBrakeApply "Restraint control module: a117 event driver brake apply; raw 3 = signal not available (SNA)";
CM_ SG_ 1297 RCM_a117_eventAccelPedalPos "Restraint control module: a117 event accel pedal pos; raw 255 = signal not available (SNA)";
CM_ SG_ 1297 RCM_a118_eventArmStatus "Restraint control module: a118 event arm status";
CM_ SG_ 1297 RCM_a118_eventFactoryMode "Restraint control module: a118 event factory mode";
CM_ SG_ 1297 RCM_a118_eventDiagEnabled "Restraint control module: a118 event diag enabled";
CM_ SG_ 1297 RCM_a118_eventDriveOrientation "Restraint control module: a118 event drive orientation";
CM_ SG_ 1297 RCM_a118_imuInPlaneSnsrMonitTmp "Restraint control module: a118 imu in plane snsr monit tmp";
CM_ SG_ 1297 RCM_a118_imuInPlaneSnsrMonitPerm "Restraint control module: a118 imu in plane snsr monit perm";
CM_ SG_ 1297 RCM_a118_eventIDFsignal "Restraint control module: a118 event ID fsignal";
CM_ SG_ 1297 RCM_a118_eventFrontLeftSeatbelt "Restraint control module: a118 event front left seatbelt";
CM_ SG_ 1297 RCM_a118_eventFrontRightSeatbelt "Restraint control module: a118 event front right seatbelt";
CM_ SG_ 1297 RCM_a118_eventVehicleSpeed "Restraint control module: a118 event vehicle speed";
CM_ SG_ 1297 RCM_a118_eventSteeringAngle "Restraint control module: a118 event steering angle";
CM_ SG_ 1297 RCM_a118_eventDriverBrakeApply "Restraint control module: a118 event driver brake apply; raw 3 = signal not available (SNA)";
CM_ SG_ 1297 RCM_a118_eventAccelPedalPos "Restraint control module: a118 event accel pedal pos; raw 255 = signal not available (SNA)";
CM_ BO_ 881 "Restraint control module message: alert matrix";
CM_ SG_ 881 RCM_matrixIndex "Restraint control module: matrix index";
CM_ SG_ 881 RCM_a000_crashDetected "Restraint control module: a000 crash detected";
CM_ SG_ 881 RCM_a001_nearDeploy "Restraint control module: a001 near deploy";
CM_ SG_ 881 RCM_a002_airbagsNotArmed "Restraint control module: a002 airbags not armed";
CM_ SG_ 881 RCM_a003_warningIndicator "Restraint control module: a003 warning indicator";
CM_ SG_ 881 RCM_a004_internalFault "Restraint control module: a004 internal fault";
CM_ SG_ 881 RCM_a005_crcError "Restraint control module: a005 crc error";
CM_ SG_ 881 RCM_a006_batteryVoltageRange "Restraint control module: a006 battery voltage range";
CM_ SG_ 881 RCM_a007_powerSupplyExternal "Restraint control module: a007 power supply external";
CM_ SG_ 881 RCM_a008_powerSupplyInternal "Restraint control module: a008 power supply internal";
CM_ SG_ 881 RCM_a009_reprogramLimit "Restraint control module: a009 reprogram limit";
CM_ SG_ 881 RCM_a010_scmDisabled "Restraint control module: a010 scm disabled";
CM_ SG_ 881 RCM_a011_eepromDataLocked "Restraint control module: a011 eeprom data locked";
CM_ SG_ 881 RCM_a012_vinStorage "Restraint control module: a012 vin storage";
CM_ SG_ 881 RCM_a013_driverOrientation "Restraint control module: a013 driver orientation";
CM_ SG_ 881 RCM_a014_driverABStage1 "Restraint control module: a014 driver AB stage1";
CM_ SG_ 881 RCM_a015_driverABStage2 "Restraint control module: a015 driver AB stage2";
CM_ SG_ 881 RCM_a016_passABStage1 "Restraint control module: a016 pass AB stage1";
CM_ SG_ 881 RCM_a017_passABStage2 "Restraint control module: a017 pass AB stage2";
CM_ SG_ 881 RCM_a018_passengerActiveVent "Restraint control module: a018 passenger active vent";
CM_ SG_ 881 RCM_a019_pretenShldrFrontLeft "Restraint control module: a019 preten shldr front left";
CM_ SG_ 881 RCM_a020_pretenShldFrontRight "Restraint control module: a020 preten shld front right";
CM_ SG_ 881 RCM_a021_pretenLapFrontLeft "Restraint control module: a021 preten lap front left";
CM_ SG_ 881 RCM_a022_pretenLapFrontRight "Restraint control module: a022 preten lap front right";
CM_ SG_ 881 RCM_a023_loadLimiterLeftSide "Restraint control module: a023 load limiter left side";
CM_ SG_ 881 RCM_a024_loadLimiterRightSide "Restraint control module: a024 load limiter right side";
CM_ SG_ 881 RCM_a025_kneeABDriver "Restraint control module: a025 knee AB driver";
CM_ SG_ 881 RCM_a026_kneeABFrontPassenger "Restraint control module: a026 knee AB front passenger";
CM_ SG_ 881 RCM_a027_sideAB1stRowLeft "Restraint control module: a027 side ab1st row left";
CM_ SG_ 881 RCM_a028_sideAB1stRowRight "Restraint control module: a028 side ab1st row right";
CM_ SG_ 881 RCM_a029_driverABActiveVent "Restraint control module: a029 driver AB active vent";
CM_ SG_ 881 RCM_a030_farSideInboardAirbag "Restraint control module: a030 far side inboard airbag";
CM_ SG_ 881 RCM_a031_frontCenterAirbag "Restraint control module: a031 front center airbag";
CM_ SG_ 881 RCM_a032_curtainABLeft "Restraint control module: a032 curtain AB left";
CM_ SG_ 881 RCM_a033_curtainABRight "Restraint control module: a033 curtain AB right";
CM_ SG_ 881 RCM_a034_preten2ndRowLeft "Restraint control module: a034 preten2nd row left";
CM_ SG_ 881 RCM_a035_preten2ndRowRight "Restraint control module: a035 preten2nd row right";
CM_ SG_ 881 RCM_a036_curAB2ndRowLeft "Restraint control module: a036 cur ab2nd row left";
CM_ SG_ 881 RCM_a037_curAB2ndRowRight "Restraint control module: a037 cur ab2nd row right";
CM_ SG_ 881 RCM_a038_unusedA "Restraint control module: a038 unused a";
CM_ SG_ 881 RCM_a039_unusedB "Restraint control module: a039 unused b";
CM_ SG_ 881 RCM_a040_hoodActuatorRight "Restraint control module: a040 hood actuator right";
CM_ SG_ 881 RCM_a041_hoodActuatorLeft "Restraint control module: a041 hood actuator left";
CM_ SG_ 881 RCM_a042_ens1Line "Restraint control module: a042 ens1 line";
CM_ SG_ 881 RCM_a043_ens2Line "Restraint control module: a043 ens2 line";
CM_ SG_ 881 RCM_a044_upFrontSensorLeft "Restraint control module: a044 up front sensor left";
CM_ SG_ 881 RCM_a045_upFrontSensorRight "Restraint control module: a045 up front sensor right";
CM_ SG_ 881 RCM_a046_sideAccelBPillarLeft "Restraint control module: a046 side accel b pillar left";
CM_ SG_ 881 RCM_a047_sideAccelBPillarRight "Restraint control module: a047 side accel b pillar right";
CM_ SG_ 881 RCM_a048_sideAccelCPillarLeft "Restraint control module: a048 side accel c pillar left";
CM_ SG_ 881 RCM_a049_sideAccelCPillarRight "Restraint control module: a049 side accel c pillar right";
CM_ SG_ 881 RCM_a050_upFrontSensorCenter "Restraint control module: a050 up front sensor center";
CM_ SG_ 881 RCM_a051_pressureFrontLftDoor "Restraint control module: a051 pressure front lft door";
CM_ SG_ 881 RCM_a052_pressureFrontRtDoor "Restraint control module: a052 pressure front rt door";
CM_ SG_ 881 RCM_a053_pressurePedProLeft "Restraint control module: a053 pressure ped pro left";
CM_ SG_ 881 RCM_a054_pressurePedProRight "Restraint control module: a054 pressure ped pro right";
CM_ SG_ 881 RCM_a055_inertialMeasurement "Restraint control module: a055 inertial measurement";
CM_ SG_ 881 RCM_a056_passengerFrontOCS "Restraint control module: a056 passenger front OCS";
CM_ SG_ 881 RCM_a057_driverOCS "Restraint control module: a057 driver OCS";
CM_ SG_ 881 RCM_a058_buckle1stRowLeft "Restraint control module: a058 buckle1st row left";
CM_ SG_ 881 RCM_a059_buckle1stRowRight "Restraint control module: a059 buckle1st row right";
CM_ SG_ 881 RCM_a060_stpsLeft "Restraint control module: a060 stps left";
CM_ SG_ 881 RCM_a061_stpsRight "Restraint control module: a061 stps right";
CM_ SG_ 881 RCM_a062_alrSwitch "Restraint control module: a062 alr switch";
CM_ SG_ 881 RCM_a063_sbsw2ndRowRight "Restraint control module: a063 sbsw2nd row right";
CM_ SG_ 881 RCM_a064_hardwareCodingPin1 "Restraint control module: a064 hardware coding pin1";
CM_ SG_ 881 RCM_a065_driverOrientConfigPin "Restraint control module: a065 driver orient config pin";
CM_ SG_ 881 RCM_a066_seatBackSw2ndRowLeft "Restraint control module: a066 seat back sw2nd row left";
CM_ SG_ 881 RCM_a067_comCANInitFailure "Restraint control module: a067 com CAN init failure";
CM_ SG_ 881 RCM_a068_comChassisBusOff "Restraint control module: a068 com chassis bus off";
CM_ SG_ 881 RCM_a069_comCHCANPH7 "Restraint control module: a069 com CHCANPH7";
CM_ SG_ 881 RCM_a070_comCHCANPH8 "Restraint control module: a070 com CHCANPH8";
CM_ SG_ 881 RCM_a071_comCHCANPH9 "Restraint control module: a071 com CHCANPH9";
CM_ SG_ 881 RCM_a072_comUnused "Restraint control module: a072 com unused";
CM_ SG_ 881 RCM_a073_comCHCANPH4 "Restraint control module: a073 com CHCANPH4";
CM_ SG_ 881 RCM_a074_comCHCANPH5 "Restraint control module: a074 com CHCANPH5";
CM_ SG_ 881 RCM_a075_comCHCANPH6 "Restraint control module: a075 com CHCANPH6";
CM_ SG_ 881 RCM_a076_comEPBLStatus "Restraint control module: a076 com EPBL status";
CM_ SG_ 881 RCM_a077_comEPBRStatus "Restraint control module: a077 com EPBR status";
CM_ SG_ 881 RCM_a078_comOCS1PStatus "Restraint control module: a078 com OCS1 p status";
CM_ SG_ 881 RCM_a079_comOCS1DStatus "Restraint control module: a079 com OCS1 d status";
CM_ SG_ 881 RCM_a080_comGTWACS "Restraint control module: a080 com GTWACS";
CM_ SG_ 881 RCM_a081_comVCFRONTLVPwr "Restraint control module: a081 com VCFRONTLV pwr";
CM_ SG_ 881 RCM_a082_comUIodo "Restraint control module: a082 com u iodo";
CM_ SG_ 881 RCM_a083_comGTWCarState "Restraint control module: a083 com GTW car state";
CM_ SG_ 881 RCM_a084_comTPMSStatus "Restraint control module: a084 com TPMS status";
CM_ SG_ 881 RCM_a085_comGTWCarConfig "Restraint control module: a085 com GTW car config";
CM_ SG_ 881 RCM_a086_comVINMIA "Restraint control module: a086 com VINMIA";
CM_ SG_ 881 RCM_a087_comCANSilent "Restraint control module: a087 com CAN silent";
CM_ SG_ 881 RCM_a088_comCHCANPH2 "Restraint control module: a088 com CHCANPH2";
CM_ SG_ 881 RCM_a089_comCHCANPH3 "Restraint control module: a089 com CHCANPH3";
CM_ SG_ 881 RCM_a090_comPartyBusOff "Restraint control module: a090 com party bus off";
CM_ SG_ 881 RCM_a091_comEPAS3PsysStatus "Restraint control module: a091 com EPAS3 psys status";
CM_ SG_ 881 RCM_a092_comDASISF "Restraint control module: a092 com DASISF";
CM_ SG_ 881 RCM_a093_comVCLEFTStatus "Restraint control module: a093 com VCLEFT status";
CM_ SG_ 881 RCM_a094_comVCRIGHTStatus "Restraint control module: a094 com VCRIGHT status";
CM_ SG_ 881 RCM_a095_comESPstatus "Restraint control module: a095 com ES pstatus";
CM_ SG_ 881 RCM_a096_comESPwheelSpeeds "Restraint control module: a096 com ES pwheel speeds";
CM_ SG_ 881 RCM_a097_comDIspeed "Restraint control module: a097 com d ispeed";
CM_ SG_ 881 RCM_a098_comDIchassisControl "Restraint control module: a098 com d ichassis control";
CM_ SG_ 881 RCM_a099_comDItorque "Restraint control module: a099 com d itorque";
CM_ SG_ 881 RCM_a100_comDIsystemStatus "Restraint control module: a100 com d isystem status";
CM_ SG_ 881 RCM_a101_idfSystem "Restraint control module: a101 idf system";
CM_ SG_ 881 RCM_a102_imuYawR8OffstCompLim "Restraint control module: a102 imu yaw R8 offst comp lim";
CM_ SG_ 881 RCM_a103_imuPtchR8OffstCompLim "Restraint control module: a103 imu ptch R8 offst comp lim";
CM_ SG_ 881 RCM_a104_imuRollR8OffstCompLim "Restraint control module: a104 imu roll R8 offst comp lim";
CM_ SG_ 881 RCM_a105_imuLongAccOffstCompLim "Restraint control module: a105 imu long acc offst comp lim";
CM_ SG_ 881 RCM_a106_imuLatAccOffstCompLim "Restraint control module: a106 imu lat acc offst comp lim";
CM_ SG_ 881 RCM_a107_imuVertAccOffstCompLim "Restraint control module: a107 imu vert acc offst comp lim";
CM_ SG_ 881 RCM_a108_crashAlgoWakeup "Restraint control module: a108 crash algo wakeup";
CM_ SG_ 881 RCM_a109_abuseImmunity "Restraint control module: a109 abuse immunity";
CM_ SG_ 881 RCM_a110_factoryMode "Restraint control module: a110 factory mode";
CM_ SG_ 881 RCM_a111_diagnosticsEnabled "Restraint control module: a111 diagnostics enabled";
CM_ SG_ 881 RCM_a112_imuYawRate "Restraint control module: a112 imu yaw rate";
CM_ SG_ 881 RCM_a113_imuPitchRate "Restraint control module: a113 imu pitch rate";
CM_ SG_ 881 RCM_a114_imuRollRate "Restraint control module: a114 imu roll rate";
CM_ SG_ 881 RCM_a115_imuLinearAcceleration "Restraint control module: a115 imu linear acceleration";
CM_ SG_ 881 RCM_a116_imuLateralAcceleration "Restraint control module: a116 imu lateral acceleration";
CM_ SG_ 881 RCM_a117_imuVerticalAcceleration "Restraint control module: a117 imu vertical acceleration";
CM_ SG_ 881 RCM_a118_imuInPlaneAcceleration "Restraint control module: a118 imu in plane acceleration";
CM_ BO_ 17 "Restraint control module message: collision";
CM_ SG_ 17 RCM_collisionChecksum "Restraint control module: collision checksum";
CM_ SG_ 17 RCM_collisionCounter "Restraint control module: collision counter";
CM_ SG_ 17 RCM_collisionRear "Indicates that a rear collision occurred; raw 3 = signal not available (SNA)";
CM_ SG_ 17 RCM_collisionRight "Indicates that a right side collision occurred; raw 3 = signal not available (SNA)";
CM_ SG_ 17 RCM_collisionLeft "Indicates that a left side collision occurred; raw 3 = signal not available (SNA)";
CM_ SG_ 17 RCM_collisionFront "Indicates that a frontal collision occurred; raw 3 = signal not available (SNA)";
CM_ SG_ 17 RCM_collisionRollover "Indicates that a rollover has occurred; raw 3 = signal not available (SNA)";
CM_ SG_ 17 RCM_collisionPedPro "Indicates that a pedestrian impact has occurred; raw 3 = signal not available (SNA)";
CM_ SG_ 17 RCM_collisionSeverity "Collision severity";
CM_ BO_ 257 "Restraint control module message: inertial1";
CM_ SG_ 257 RCM_yawRate "Offset compensated yaw rate measured by the airbag ECU. ISO axis convention (Positive during left turn); raw 32768 = signal not available (SNA)";
CM_ SG_ 257 RCM_pitchRate "Offset compensated pitch rate measured by the airbag ECU. ISO axis convention (positive when the nose pitches down); raw 16384 = signal not available (SNA)";
CM_ SG_ 257 RCM_rollRate "Offset compensated roll rate measured by the airbag ECU. ISO axis convention (positive during left turn); raw 16384 = signal not available (SNA)";
CM_ SG_ 257 RCM_rollRateQF "Restraint control module: roll rate QF";
CM_ SG_ 257 RCM_yawRateQF "Restraint control module: yaw rate QF";
CM_ SG_ 257 RCM_pitchRateQF "Restraint control module: pitch rate QF";
CM_ SG_ 257 RCM_inertial1Counter "Restraint control module: inertial1 counter";
CM_ SG_ 257 RCM_inertial1Checksum "Restraint control module: inertial1 checksum";
CM_ BO_ 278 "Restraint control module message: inertial2";
CM_ SG_ 278 RCM_longitudinalAccel "Offset compensated longitudinal acceleration measured by the airbag ECU. ISO axis convention (positive during forward acceleration); raw 32768 = signal not available (SNA)";
CM_ SG_ 278 RCM_lateralAccel "Reports offset compensated lateral acceleration measured by the airbag ECU. Follows ISO axis convention that measurements are positive during left turns and negative during right turns.; raw 32768 = signal not available (SNA)";
CM_ SG_ 278 RCM_verticalAccel "Offset compensated vertical acceleration measured by the airbag ECU. ISO axis convention (positive up); raw 32768 = signal not available (SNA)";
CM_ SG_ 278 RCM_longitudinalAccelQF "Restraint control module: longitudinal accel QF";
CM_ SG_ 278 RCM_lateralAccelQF "Restraint control module: lateral accel QF";
CM_ SG_ 278 RCM_verticalAccelQF "Restraint control module: vertical accel QF";
CM_ SG_ 278 RCM_CGTranslationFault "Restraint control module: CG translation fault";
CM_ SG_ 278 RCM_inertial2Counter "Restraint control module: inertial2 counter";
CM_ SG_ 278 RCM_inertial2Checksum "Restraint control module: inertial2 checksum";
CM_ BO_ 849 "Restraint control module message: info";
CM_ SG_ 849 RCM_infoIndex "Restraint control module: info index";
CM_ SG_ 849 RCM_infoBuildType "Restraint control module: info build type";
CM_ SG_ 849 RCM_infoComponentID "Restraint control module: info component ID";
CM_ SG_ 849 RCM_infoPcbaID "Reports the Restraint Control Module (RCM) Printed Circuit Board Assembly (PCBA) identifier.";
CM_ SG_ 849 RCM_infoAssemblyID "Restraint control module: info assembly ID";
CM_ SG_ 849 RCM_infoUsageID "Reports the Restraint Control Module (RCM) usage identification.";
CM_ SG_ 849 RCM_infoApplicationCRC "Reports the Restraint Control Module (RCM) application Cyclic Redundancy Check (CRC).";
CM_ SG_ 849 RCM_infoBootUdsProtoVersion "Reports the Restraint Control Module (RCM) boot Unified Diagnostic Services (UDS) protocol version.";
CM_ SG_ 849 RCM_infoBootloaderCRC "Reports the Restraint Control Module (RCM) bootloader Cyclic Redundancy Check (CRC).";
CM_ SG_ 849 RCM_infoAlgoCalID "Reports the Restraint Control Module (RCM) algorithm calibration identification.";
CM_ SG_ 849 RCM_infoVariantCRC "Reports the Restraint Control Module (RCM) variant Cyclic Redundancy Check (CRC).";
CM_ BO_ 2032 "Restraint control module message: near deploy";
CM_ SG_ 2032 RCM_nearDeployChecksum "Restraint control module: near deploy checksum";
CM_ SG_ 2032 RCM_nearDeployCounter "Restraint control module: near deploy counter";
CM_ SG_ 2032 RCM_nearDeployRear "Indicates that a rear near deploy event has occurred. No airbags have been deployed.; raw 3 = signal not available (SNA)";
CM_ SG_ 2032 RCM_nearDeployRight "Indicates that a right side near deploy event has occurred. No airbags have been deployed.; raw 3 = signal not available (SNA)";
CM_ SG_ 2032 RCM_nearDeployLeft "Indicates that a left side near deploy event has occurred. No airbags have been deployed.; raw 3 = signal not available (SNA)";
CM_ SG_ 2032 RCM_nearDeployFront "Indicates that a frontal near deploy event has occurred. No airbags have been deployed.; raw 3 = signal not available (SNA)";
CM_ SG_ 2032 RCM_nearDeployRollover "Indicates that a roll over near deploy event has occurred. No airbags have been deployed.; raw 3 = signal not available (SNA)";
CM_ SG_ 2032 RCM_crashAlgoWakeup "Crash Algorithm Wakeup status; raw 3 = signal not available (SNA)";
CM_ BO_ 529 "Restraint control module message: status";
CM_ SG_ 529 RCM_statusChecksum "Restraint control module: status checksum";
CM_ SG_ 529 RCM_statusCounter "Restraint control module: status counter";
CM_ SG_ 529 RCM_armStatus "Reports the arm status of the Restraint Control Module (RCM).; raw 3 = signal not available (SNA)";
CM_ SG_ 529 RCM_warningIndicatorState "Reports whether the Restraint Control Module (RCM) warning indicator is present on the User Interface (UI).; raw 3 = signal not available (SNA)";
CM_ SG_ 529 RCM_passAirbagIndicatorRequest "Reports status of the Front Passenger Airbag Off telltale.; raw 3 = signal not available (SNA)";
CM_ SG_ 529 RCM_airbagCutoffStatus "Reports the front passenger airbag enabled or disabled status.; raw 3 = signal not available (SNA)";
CM_ SG_ 529 RCM_alrSwitchStatus "Reports status of the front passenger automatic locking seat belt retractor.; raw 3 = signal not available (SNA)";
CM_ SG_ 529 RCM_vinLearnFlag "Reports whether the Vehicle Identification Number has been learned.; raw 3 = signal not available (SNA)";
CM_ SG_ 529 RCM_seatTrackPositionDrvr "Driver seat track position status; raw 3 = signal not available (SNA)";
CM_ SG_ 529 RCM_seatTrackPositionPass "Passenger seat track position status; raw 3 = signal not available (SNA)";
CM_ SG_ 529 RCM_edr1State "Reports status of Restraint Control Module (RCM) Event Data Recorder (EDR) memory slot 1.";
CM_ SG_ 529 RCM_edr2State "Reports status of Restraint Control Module (RCM) Event Data Recorder (EDR) memory slot 2.";
CM_ SG_ 529 RCM_keepPowerReason "Restraint Control Module request to maintain power; raw 8 = signal not available (SNA)";
CM_ SG_ 529 RCM_imuOffsetLearnState "Restraint control module: imu offset learn state";
CM_ SG_ 529 RCM_edr3State "Reports status of Restraint Control Module (RCM) Event Data Recorder (EDR) memory slot 3.";
CM_ SG_ 529 RCM_driverOrientationInitStatus "Restraint control module: driver orientation init status; raw 7 = signal not available (SNA)";
CM_ SG_ 529 RCM_occupantClassificationSource "Indicates whether the occupant classification source is the Right Vehicle Controller (VCRIGHT) or the Occupancy Classification System - 1st Row Passenger (OCS1P).";
CM_ SG_ 529 RCM_pedProEDR1State "Reports status of the PedPro Event Data Recorder (EDR) memory slot 1.";
CM_ SG_ 529 RCM_pedProEDR2State "Reports status of the PedPro Event Data Recorder (EDR) memory slot 2.";
CM_ BO_ 1471 "RCU ECU message: alert log";
CM_ SG_ 1471 RCU_alertID "RCU ECU: alert ID";
CM_ SG_ 1471 RCU_alertState "RCU ECU: alert state";
CM_ SG_ 1471 RCU_a010_sensorPowerSupply "RCU ECU: a010 sensor power supply";
CM_ SG_ 1471 RCU_a010_sensorHardware "RCU ECU: a010 sensor hardware";
CM_ SG_ 1471 RCU_a010_sensorSignal "RCU ECU: a010 sensor signal";
CM_ SG_ 1471 RCU_a023_validityOnChassisBus "RCU ECU: a023 validity on chassis bus";
CM_ SG_ 1471 RCU_a023_validityOnPartyBus "RCU ECU: a023 validity on party bus";
CM_ SG_ 1471 RCU_a024_validityOnChassisBus "RCU ECU: a024 validity on chassis bus";
CM_ SG_ 1471 RCU_a024_validityOnPartyBus "RCU ECU: a024 validity on party bus";
CM_ SG_ 1471 RCU_a025_validityOnChassisBus "RCU ECU: a025 validity on chassis bus";
CM_ SG_ 1471 RCU_a025_validityOnPartyBus "RCU ECU: a025 validity on party bus";
CM_ SG_ 1471 RCU_a035_validityOnChassisBus "RCU ECU: a035 validity on chassis bus";
CM_ SG_ 1471 RCU_a035_validityOnPartyBus "RCU ECU: a035 validity on party bus";
CM_ SG_ 1471 RCU_a036_validityOnChassisBus "RCU ECU: a036 validity on chassis bus";
CM_ SG_ 1471 RCU_a036_validityOnPartyBus "RCU ECU: a036 validity on party bus";
BA_DEF_ BO_ "GenMsgCycleTime" INT 0 3600000;
BA_DEF_ BO_ "GenMsgSendType" ENUM "Cyclic","NotUsed","NotUsed","NotUsed","NotUsed","NotUsed","NotUsed","IfActive","NoMsgSendType","NotUsed";
BA_DEF_ BO_ "VFrameFormat" ENUM "StandardCAN","ExtendedCAN","reserved","J1939PG","reserved","reserved","reserved","reserved","reserved","reserved","reserved","reserved","reserved","reserved","StandardCAN_FD","ExtendedCAN_FD";
BA_DEF_ BO_ "CANFD_BRS" ENUM "0","1";
BA_DEF_ SG_ "GenSigSNA" STRING;
BA_DEF_ SG_ "SystemSignalLongSymbol" STRING;
BA_DEF_ SG_ "Confidence" ENUM "validated","plausible","layout-only","contradicted";
BA_DEF_DEF_ "GenMsgCycleTime" 0;
BA_DEF_DEF_ "GenMsgSendType" "NoMsgSendType";
BA_DEF_DEF_ "VFrameFormat" "StandardCAN";
BA_DEF_DEF_ "CANFD_BRS" "1";
BA_DEF_DEF_ "GenSigSNA" "";
BA_DEF_DEF_ "SystemSignalLongSymbol" "";
BA_DEF_DEF_ "Confidence" "layout-only";
BA_ "GenMsgCycleTime" BO_ 881 1000;
BA_ "GenMsgSendType" BO_ 881 0;
BA_ "GenMsgCycleTime" BO_ 17 10;
BA_ "GenMsgSendType" BO_ 17 0;
BA_ "GenMsgCycleTime" BO_ 257 20;
BA_ "GenMsgSendType" BO_ 257 0;
BA_ "GenMsgCycleTime" BO_ 278 20;
BA_ "GenMsgSendType" BO_ 278 0;
BA_ "GenMsgCycleTime" BO_ 849 2000;
BA_ "GenMsgSendType" BO_ 849 0;
BA_ "GenMsgCycleTime" BO_ 2032 10;
BA_ "GenMsgSendType" BO_ 2032 0;
BA_ "GenMsgCycleTime" BO_ 529 100;
BA_ "GenMsgSendType" BO_ 529 0;
BA_ "Confidence" SG_ 1297 RCM_a069_eventDriveOrientation 1;
BA_ "Confidence" SG_ 1297 RCM_a069_eventIDFsignal 1;
BA_ "Confidence" SG_ 1297 RCM_a069_eventFrontLeftSeatbelt 1;
BA_ "Confidence" SG_ 1297 RCM_a069_eventFrontRightSeatbelt 1;
BA_ "Confidence" SG_ 1297 RCM_a069_eventVehicleSpeed 1;
BA_ "Confidence" SG_ 1297 RCM_a069_eventSteeringAngle 1;
BA_ "Confidence" SG_ 1297 RCM_a069_eventDriverBrakeApply 1;
BA_ "GenSigSNA" SG_ 1297 RCM_a069_eventDriverBrakeApply "3";
BA_ "Confidence" SG_ 1297 RCM_a069_eventAccelPedalPos 1;
BA_ "GenSigSNA" SG_ 1297 RCM_a069_eventAccelPedalPos "255";
BA_ "Confidence" SG_ 1297 RCM_a070_eventArmStatus 1;
BA_ "Confidence" SG_ 1297 RCM_a070_eventFactoryMode 1;
BA_ "Confidence" SG_ 1297 RCM_a070_eventDiagEnabled 1;
BA_ "Confidence" SG_ 1297 RCM_a070_eventDriveOrientation 1;
BA_ "Confidence" SG_ 1297 RCM_a070_eventIDFsignal 1;
BA_ "Confidence" SG_ 1297 RCM_a070_eventFrontLeftSeatbelt 1;
BA_ "Confidence" SG_ 1297 RCM_a070_eventFrontRightSeatbelt 1;
BA_ "Confidence" SG_ 1297 RCM_a070_eventVehicleSpeed 1;
BA_ "Confidence" SG_ 1297 RCM_a070_eventSteeringAngle 1;
BA_ "Confidence" SG_ 1297 RCM_a070_eventDriverBrakeApply 1;
BA_ "GenSigSNA" SG_ 1297 RCM_a070_eventDriverBrakeApply "3";
BA_ "Confidence" SG_ 1297 RCM_a070_eventAccelPedalPos 1;
BA_ "GenSigSNA" SG_ 1297 RCM_a070_eventAccelPedalPos "255";
BA_ "Confidence" SG_ 1297 RCM_a071_eventArmStatus 1;
BA_ "Confidence" SG_ 1297 RCM_a071_eventFactoryMode 1;
BA_ "Confidence" SG_ 1297 RCM_a071_eventDiagEnabled 1;
BA_ "Confidence" SG_ 1297 RCM_a071_eventDriveOrientation 1;
BA_ "Confidence" SG_ 1297 RCM_a071_eventIDFsignal 1;
BA_ "Confidence" SG_ 1297 RCM_a071_eventFrontLeftSeatbelt 1;
BA_ "Confidence" SG_ 1297 RCM_a071_eventFrontRightSeatbelt 1;
BA_ "Confidence" SG_ 1297 RCM_a071_eventVehicleSpeed 1;
BA_ "Confidence" SG_ 1297 RCM_a071_eventSteeringAngle 1;
BA_ "Confidence" SG_ 1297 RCM_a071_eventDriverBrakeApply 1;
BA_ "GenSigSNA" SG_ 1297 RCM_a071_eventDriverBrakeApply "3";
BA_ "Confidence" SG_ 1297 RCM_a071_eventAccelPedalPos 1;
BA_ "GenSigSNA" SG_ 1297 RCM_a071_eventAccelPedalPos "255";
BA_ "Confidence" SG_ 1297 RCM_a072_eventArmStatus 1;
BA_ "Confidence" SG_ 1297 RCM_a072_eventFactoryMode 1;
BA_ "Confidence" SG_ 1297 RCM_a072_eventDiagEnabled 1;
BA_ "Confidence" SG_ 1297 RCM_a072_eventDriveOrientation 1;
BA_ "Confidence" SG_ 1297 RCM_a072_eventIDFsignal 1;
BA_ "Confidence" SG_ 1297 RCM_a072_eventFrontLeftSeatbelt 1;
BA_ "Confidence" SG_ 1297 RCM_a072_eventFrontRightSeatbelt 1;
BA_ "Confidence" SG_ 1297 RCM_a072_eventVehicleSpeed 1;
BA_ "Confidence" SG_ 1297 RCM_a072_eventSteeringAngle 1;
BA_ "Confidence" SG_ 1297 RCM_a072_eventDriverBrakeApply 1;
BA_ "GenSigSNA" SG_ 1297 RCM_a072_eventDriverBrakeApply "3";
BA_ "Confidence" SG_ 1297 RCM_a072_eventAccelPedalPos 1;
BA_ "GenSigSNA" SG_ 1297 RCM_a072_eventAccelPedalPos "255";
BA_ "Confidence" SG_ 1297 RCM_a073_eventArmStatus 1;
BA_ "Confidence" SG_ 1297 RCM_a073_eventFactoryMode 1;
BA_ "Confidence" SG_ 1297 RCM_a073_eventDiagEnabled 1;
BA_ "Confidence" SG_ 1297 RCM_a073_eventDriveOrientation 1;
BA_ "Confidence" SG_ 1297 RCM_a073_eventIDFsignal 1;
BA_ "Confidence" SG_ 1297 RCM_a073_eventFrontLeftSeatbelt 1;
BA_ "Confidence" SG_ 1297 RCM_a073_eventFrontRightSeatbelt 1;
BA_ "Confidence" SG_ 1297 RCM_a073_eventVehicleSpeed 1;
BA_ "Confidence" SG_ 1297 RCM_a073_eventSteeringAngle 1;
BA_ "Confidence" SG_ 1297 RCM_a073_eventDriverBrakeApply 1;
BA_ "GenSigSNA" SG_ 1297 RCM_a073_eventDriverBrakeApply "3";
BA_ "Confidence" SG_ 1297 RCM_a073_eventAccelPedalPos 1;
BA_ "GenSigSNA" SG_ 1297 RCM_a073_eventAccelPedalPos "255";
BA_ "Confidence" SG_ 1297 RCM_a074_eventArmStatus 1;
BA_ "Confidence" SG_ 1297 RCM_a074_eventFactoryMode 1;
BA_ "Confidence" SG_ 1297 RCM_a074_eventDiagEnabled 1;
BA_ "Confidence" SG_ 1297 RCM_a074_eventDriveOrientation 1;
BA_ "Confidence" SG_ 1297 RCM_a074_eventIDFsignal 1;
BA_ "Confidence" SG_ 1297 RCM_a074_eventFrontLeftSeatbelt 1;
BA_ "Confidence" SG_ 1297 RCM_a074_eventFrontRightSeatbelt 1;
BA_ "Confidence" SG_ 1297 RCM_a074_eventVehicleSpeed 1;
BA_ "Confidence" SG_ 1297 RCM_a074_eventSteeringAngle 1;
BA_ "Confidence" SG_ 1297 RCM_a074_eventDriverBrakeApply 1;
BA_ "GenSigSNA" SG_ 1297 RCM_a074_eventDriverBrakeApply "3";
BA_ "Confidence" SG_ 1297 RCM_a074_eventAccelPedalPos 1;
BA_ "GenSigSNA" SG_ 1297 RCM_a074_eventAccelPedalPos "255";
BA_ "Confidence" SG_ 1297 RCM_a075_eventArmStatus 1;
BA_ "Confidence" SG_ 1297 RCM_a075_eventFactoryMode 1;
BA_ "Confidence" SG_ 1297 RCM_a075_eventDiagEnabled 1;
BA_ "Confidence" SG_ 1297 RCM_a075_eventDriveOrientation 1;
BA_ "Confidence" SG_ 1297 RCM_a075_eventIDFsignal 1;
BA_ "Confidence" SG_ 1297 RCM_a075_eventFrontLeftSeatbelt 1;
BA_ "Confidence" SG_ 1297 RCM_a075_eventFrontRightSeatbelt 1;
BA_ "Confidence" SG_ 1297 RCM_a075_eventVehicleSpeed 1;
BA_ "Confidence" SG_ 1297 RCM_a075_eventSteeringAngle 1;
BA_ "Confidence" SG_ 1297 RCM_a075_eventDriverBrakeApply 1;
BA_ "GenSigSNA" SG_ 1297 RCM_a075_eventDriverBrakeApply "3";
BA_ "Confidence" SG_ 1297 RCM_a075_eventAccelPedalPos 1;
BA_ "GenSigSNA" SG_ 1297 RCM_a075_eventAccelPedalPos "255";
BA_ "Confidence" SG_ 1297 RCM_a078_eventArmStatus 1;
BA_ "Confidence" SG_ 1297 RCM_a078_eventFactoryMode 1;
BA_ "Confidence" SG_ 1297 RCM_a078_eventDiagEnabled 1;
BA_ "Confidence" SG_ 1297 RCM_a078_eventDriveOrientation 1;
BA_ "Confidence" SG_ 1297 RCM_a078_eventIDFsignal 1;
BA_ "Confidence" SG_ 1297 RCM_a078_eventFrontLeftSeatbelt 1;
BA_ "Confidence" SG_ 1297 RCM_a078_eventFrontRightSeatbelt 1;
BA_ "Confidence" SG_ 1297 RCM_a078_eventVehicleSpeed 1;
BA_ "Confidence" SG_ 1297 RCM_a078_eventSteeringAngle 1;
BA_ "Confidence" SG_ 1297 RCM_a078_eventDriverBrakeApply 1;
BA_ "GenSigSNA" SG_ 1297 RCM_a078_eventDriverBrakeApply "3";
BA_ "Confidence" SG_ 1297 RCM_a078_eventAccelPedalPos 1;
BA_ "GenSigSNA" SG_ 1297 RCM_a078_eventAccelPedalPos "255";
BA_ "Confidence" SG_ 1297 RCM_a079_eventArmStatus 1;
BA_ "Confidence" SG_ 1297 RCM_a079_eventFactoryMode 1;
BA_ "Confidence" SG_ 1297 RCM_a079_eventDiagEnabled 1;
BA_ "Confidence" SG_ 1297 RCM_a079_eventDriveOrientation 1;
BA_ "Confidence" SG_ 1297 RCM_a079_eventIDFsignal 1;
BA_ "Confidence" SG_ 1297 RCM_a079_eventFrontLeftSeatbelt 1;
BA_ "Confidence" SG_ 1297 RCM_a079_eventFrontRightSeatbelt 1;
BA_ "Confidence" SG_ 1297 RCM_a079_eventVehicleSpeed 1;
BA_ "Confidence" SG_ 1297 RCM_a079_eventSteeringAngle 1;
BA_ "Confidence" SG_ 1297 RCM_a079_eventDriverBrakeApply 1;
BA_ "GenSigSNA" SG_ 1297 RCM_a079_eventDriverBrakeApply "3";
BA_ "Confidence" SG_ 1297 RCM_a079_eventAccelPedalPos 1;
BA_ "GenSigSNA" SG_ 1297 RCM_a079_eventAccelPedalPos "255";
BA_ "Confidence" SG_ 1297 RCM_a080_eventArmStatus 1;
BA_ "Confidence" SG_ 1297 RCM_a080_eventFactoryMode 1;
BA_ "Confidence" SG_ 1297 RCM_a080_eventDiagEnabled 1;
BA_ "Confidence" SG_ 1297 RCM_a080_eventDriveOrientation 1;
BA_ "Confidence" SG_ 1297 RCM_a080_eventIDFsignal 1;
BA_ "Confidence" SG_ 1297 RCM_a080_eventFrontLeftSeatbelt 1;
BA_ "Confidence" SG_ 1297 RCM_a080_eventFrontRightSeatbelt 1;
BA_ "Confidence" SG_ 1297 RCM_a080_eventVehicleSpeed 1;
BA_ "Confidence" SG_ 1297 RCM_a080_eventSteeringAngle 1;
BA_ "Confidence" SG_ 1297 RCM_a080_eventDriverBrakeApply 1;
BA_ "GenSigSNA" SG_ 1297 RCM_a080_eventDriverBrakeApply "3";
BA_ "Confidence" SG_ 1297 RCM_a080_eventAccelPedalPos 1;
BA_ "GenSigSNA" SG_ 1297 RCM_a080_eventAccelPedalPos "255";
BA_ "Confidence" SG_ 1297 RCM_a083_eventArmStatus 1;
BA_ "Confidence" SG_ 1297 RCM_a083_eventFactoryMode 1;
BA_ "Confidence" SG_ 1297 RCM_a083_eventDiagEnabled 1;
BA_ "Confidence" SG_ 1297 RCM_a083_eventDriveOrientation 1;
BA_ "Confidence" SG_ 1297 RCM_a083_eventIDFsignal 1;
BA_ "Confidence" SG_ 1297 RCM_a083_eventFrontLeftSeatbelt 1;
BA_ "Confidence" SG_ 1297 RCM_a083_eventFrontRightSeatbelt 1;
BA_ "Confidence" SG_ 1297 RCM_a083_eventVehicleSpeed 1;
BA_ "Confidence" SG_ 1297 RCM_a083_eventSteeringAngle 1;
BA_ "Confidence" SG_ 1297 RCM_a083_eventDriverBrakeApply 1;
BA_ "GenSigSNA" SG_ 1297 RCM_a083_eventDriverBrakeApply "3";
BA_ "Confidence" SG_ 1297 RCM_a083_eventAccelPedalPos 1;
BA_ "GenSigSNA" SG_ 1297 RCM_a083_eventAccelPedalPos "255";
BA_ "Confidence" SG_ 1297 RCM_a087_eventArmStatus 1;
BA_ "Confidence" SG_ 1297 RCM_a087_eventFactoryMode 1;
BA_ "Confidence" SG_ 1297 RCM_a087_eventDiagEnabled 1;
BA_ "Confidence" SG_ 1297 RCM_a087_eventDriveOrientation 1;
BA_ "Confidence" SG_ 1297 RCM_a087_eventIDFsignal 1;
BA_ "Confidence" SG_ 1297 RCM_a087_eventFrontLeftSeatbelt 1;
BA_ "Confidence" SG_ 1297 RCM_a087_eventFrontRightSeatbelt 1;
BA_ "Confidence" SG_ 1297 RCM_a087_eventVehicleSpeed 1;
BA_ "Confidence" SG_ 1297 RCM_a087_eventSteeringAngle 1;
BA_ "Confidence" SG_ 1297 RCM_a087_eventDriverBrakeApply 1;
BA_ "GenSigSNA" SG_ 1297 RCM_a087_eventDriverBrakeApply "3";
BA_ "Confidence" SG_ 1297 RCM_a087_eventAccelPedalPos 1;
BA_ "GenSigSNA" SG_ 1297 RCM_a087_eventAccelPedalPos "255";
BA_ "Confidence" SG_ 1297 RCM_a088_eventArmStatus 1;
BA_ "Confidence" SG_ 1297 RCM_a088_eventFactoryMode 1;
BA_ "Confidence" SG_ 1297 RCM_a088_eventDiagEnabled 1;
BA_ "Confidence" SG_ 1297 RCM_a088_eventDriveOrientation 1;
BA_ "Confidence" SG_ 1297 RCM_a088_eventIDFsignal 1;
BA_ "Confidence" SG_ 1297 RCM_a088_eventFrontLeftSeatbelt 1;
BA_ "Confidence" SG_ 1297 RCM_a088_eventFrontRightSeatbelt 1;
BA_ "Confidence" SG_ 1297 RCM_a088_eventVehicleSpeed 1;
BA_ "Confidence" SG_ 1297 RCM_a088_eventSteeringAngle 1;
BA_ "Confidence" SG_ 1297 RCM_a088_eventDriverBrakeApply 1;
BA_ "GenSigSNA" SG_ 1297 RCM_a088_eventDriverBrakeApply "3";
BA_ "Confidence" SG_ 1297 RCM_a088_eventAccelPedalPos 1;
BA_ "GenSigSNA" SG_ 1297 RCM_a088_eventAccelPedalPos "255";
BA_ "Confidence" SG_ 1297 RCM_a089_eventArmStatus 1;
BA_ "Confidence" SG_ 1297 RCM_a089_eventFactoryMode 1;
BA_ "Confidence" SG_ 1297 RCM_a089_eventDiagEnabled 1;
BA_ "Confidence" SG_ 1297 RCM_a089_eventDriveOrientation 1;
BA_ "Confidence" SG_ 1297 RCM_a089_eventIDFsignal 1;
BA_ "Confidence" SG_ 1297 RCM_a089_eventFrontLeftSeatbelt 1;
BA_ "Confidence" SG_ 1297 RCM_a089_eventFrontRightSeatbelt 1;
BA_ "Confidence" SG_ 1297 RCM_a089_eventVehicleSpeed 1;
BA_ "Confidence" SG_ 1297 RCM_a089_eventSteeringAngle 1;
BA_ "Confidence" SG_ 1297 RCM_a089_eventDriverBrakeApply 1;
BA_ "GenSigSNA" SG_ 1297 RCM_a089_eventDriverBrakeApply "3";
BA_ "Confidence" SG_ 1297 RCM_a089_eventAccelPedalPos 1;
BA_ "GenSigSNA" SG_ 1297 RCM_a089_eventAccelPedalPos "255";
BA_ "Confidence" SG_ 1297 RCM_a090_eventArmStatus 1;
BA_ "Confidence" SG_ 1297 RCM_a090_eventFactoryMode 1;
BA_ "Confidence" SG_ 1297 RCM_a090_eventDiagEnabled 1;
BA_ "Confidence" SG_ 1297 RCM_a090_eventDriveOrientation 1;
BA_ "Confidence" SG_ 1297 RCM_a090_eventIDFsignal 1;
BA_ "Confidence" SG_ 1297 RCM_a090_eventFrontLeftSeatbelt 1;
BA_ "Confidence" SG_ 1297 RCM_a090_eventFrontRightSeatbelt 1;
BA_ "Confidence" SG_ 1297 RCM_a090_eventVehicleSpeed 1;
BA_ "Confidence" SG_ 1297 RCM_a090_eventSteeringAngle 1;
BA_ "Confidence" SG_ 1297 RCM_a090_eventDriverBrakeApply 1;
BA_ "GenSigSNA" SG_ 1297 RCM_a090_eventDriverBrakeApply "3";
BA_ "Confidence" SG_ 1297 RCM_a090_eventAccelPedalPos 1;
BA_ "GenSigSNA" SG_ 1297 RCM_a090_eventAccelPedalPos "255";
BA_ "Confidence" SG_ 1297 RCM_a091_eventArmStatus 1;
BA_ "Confidence" SG_ 1297 RCM_a091_eventFactoryMode 1;
BA_ "Confidence" SG_ 1297 RCM_a091_eventDiagEnabled 1;
BA_ "Confidence" SG_ 1297 RCM_a091_eventDriveOrientation 1;
BA_ "Confidence" SG_ 1297 RCM_a091_eventIDFsignal 1;
BA_ "Confidence" SG_ 1297 RCM_a091_eventFrontLeftSeatbelt 1;
BA_ "Confidence" SG_ 1297 RCM_a091_eventFrontRightSeatbelt 1;
BA_ "Confidence" SG_ 1297 RCM_a091_eventVehicleSpeed 1;
BA_ "Confidence" SG_ 1297 RCM_a091_eventSteeringAngle 1;
BA_ "Confidence" SG_ 1297 RCM_a091_eventDriverBrakeApply 1;
BA_ "GenSigSNA" SG_ 1297 RCM_a091_eventDriverBrakeApply "3";
BA_ "Confidence" SG_ 1297 RCM_a091_eventAccelPedalPos 1;
BA_ "GenSigSNA" SG_ 1297 RCM_a091_eventAccelPedalPos "255";
BA_ "Confidence" SG_ 1297 RCM_a092_eventArmStatus 1;
BA_ "Confidence" SG_ 1297 RCM_a092_eventFactoryMode 1;
BA_ "Confidence" SG_ 1297 RCM_a092_eventDiagEnabled 1;
BA_ "Confidence" SG_ 1297 RCM_a092_eventDriveOrientation 1;
BA_ "Confidence" SG_ 1297 RCM_a092_eventIDFsignal 1;
BA_ "Confidence" SG_ 1297 RCM_a092_eventFrontLeftSeatbelt 1;
BA_ "Confidence" SG_ 1297 RCM_a092_eventFrontRightSeatbelt 1;
BA_ "Confidence" SG_ 1297 RCM_a092_eventVehicleSpeed 1;
BA_ "Confidence" SG_ 1297 RCM_a092_eventSteeringAngle 1;
BA_ "Confidence" SG_ 1297 RCM_a092_eventDriverBrakeApply 1;
BA_ "GenSigSNA" SG_ 1297 RCM_a092_eventDriverBrakeApply "3";
BA_ "Confidence" SG_ 1297 RCM_a092_eventAccelPedalPos 1;
BA_ "GenSigSNA" SG_ 1297 RCM_a092_eventAccelPedalPos "255";
BA_ "Confidence" SG_ 1297 RCM_a093_eventArmStatus 1;
BA_ "Confidence" SG_ 1297 RCM_a093_eventFactoryMode 1;
BA_ "Confidence" SG_ 1297 RCM_a093_eventDiagEnabled 1;
BA_ "Confidence" SG_ 1297 RCM_a093_eventDriveOrientation 1;
BA_ "Confidence" SG_ 1297 RCM_a093_eventIDFsignal 1;
BA_ "Confidence" SG_ 1297 RCM_a093_eventFrontLeftSeatbelt 1;
BA_ "Confidence" SG_ 1297 RCM_a093_eventFrontRightSeatbelt 1;
BA_ "Confidence" SG_ 1297 RCM_a093_eventVehicleSpeed 1;
BA_ "Confidence" SG_ 1297 RCM_a093_eventSteeringAngle 1;
BA_ "Confidence" SG_ 1297 RCM_a093_eventDriverBrakeApply 1;
BA_ "GenSigSNA" SG_ 1297 RCM_a093_eventDriverBrakeApply "3";
BA_ "Confidence" SG_ 1297 RCM_a093_eventAccelPedalPos 1;
BA_ "GenSigSNA" SG_ 1297 RCM_a093_eventAccelPedalPos "255";
BA_ "Confidence" SG_ 1297 RCM_a094_eventArmStatus 1;
BA_ "Confidence" SG_ 1297 RCM_a094_eventFactoryMode 1;
BA_ "Confidence" SG_ 1297 RCM_a094_eventDiagEnabled 1;
BA_ "Confidence" SG_ 1297 RCM_a094_eventDriveOrientation 1;
BA_ "Confidence" SG_ 1297 RCM_a094_eventIDFsignal 1;
BA_ "Confidence" SG_ 1297 RCM_a094_eventFrontLeftSeatbelt 1;
BA_ "Confidence" SG_ 1297 RCM_a094_eventFrontRightSeatbelt 1;
BA_ "Confidence" SG_ 1297 RCM_a094_eventVehicleSpeed 1;
BA_ "Confidence" SG_ 1297 RCM_a094_eventSteeringAngle 1;
BA_ "Confidence" SG_ 1297 RCM_a094_eventDriverBrakeApply 1;
BA_ "GenSigSNA" SG_ 1297 RCM_a094_eventDriverBrakeApply "3";
BA_ "Confidence" SG_ 1297 RCM_a094_eventAccelPedalPos 1;
BA_ "GenSigSNA" SG_ 1297 RCM_a094_eventAccelPedalPos "255";
BA_ "Confidence" SG_ 1297 RCM_a101_eventArmStatus 1;
BA_ "Confidence" SG_ 1297 RCM_a101_eventFactoryMode 1;
BA_ "Confidence" SG_ 1297 RCM_a101_eventDiagEnabled 1;
BA_ "Confidence" SG_ 1297 RCM_a101_eventDriveOrientation 1;
BA_ "Confidence" SG_ 1297 RCM_a101_eventIDFsignal 1;
BA_ "Confidence" SG_ 1297 RCM_a101_eventFrontLeftSeatbelt 1;
BA_ "Confidence" SG_ 1297 RCM_a101_eventFrontRightSeatbelt 1;
BA_ "Confidence" SG_ 1297 RCM_a101_eventVehicleSpeed 1;
BA_ "Confidence" SG_ 1297 RCM_a101_eventSteeringAngle 1;
BA_ "Confidence" SG_ 1297 RCM_a101_eventDriverBrakeApply 1;
BA_ "GenSigSNA" SG_ 1297 RCM_a101_eventDriverBrakeApply "3";
BA_ "Confidence" SG_ 1297 RCM_a101_eventAccelPedalPos 1;
BA_ "GenSigSNA" SG_ 1297 RCM_a101_eventAccelPedalPos "255";
BA_ "Confidence" SG_ 1297 RCM_a102_eventArmStatus 1;
BA_ "Confidence" SG_ 1297 RCM_a102_eventFactoryMode 1;
BA_ "Confidence" SG_ 1297 RCM_a102_eventDiagEnabled 1;
BA_ "Confidence" SG_ 1297 RCM_a102_eventDriveOrientation 1;
BA_ "Confidence" SG_ 1297 RCM_a102_eventIDFsignal 1;
BA_ "Confidence" SG_ 1297 RCM_a102_eventFrontLeftSeatbelt 1;
BA_ "Confidence" SG_ 1297 RCM_a102_eventFrontRightSeatbelt 1;
BA_ "Confidence" SG_ 1297 RCM_a102_eventVehicleSpeed 1;
BA_ "Confidence" SG_ 1297 RCM_a102_eventSteeringAngle 1;
BA_ "Confidence" SG_ 1297 RCM_a102_eventDriverBrakeApply 1;
BA_ "GenSigSNA" SG_ 1297 RCM_a102_eventDriverBrakeApply "3";
BA_ "Confidence" SG_ 1297 RCM_a102_eventAccelPedalPos 1;
BA_ "GenSigSNA" SG_ 1297 RCM_a102_eventAccelPedalPos "255";
BA_ "Confidence" SG_ 1297 RCM_a103_eventArmStatus 1;
BA_ "Confidence" SG_ 1297 RCM_a103_eventFactoryMode 1;
BA_ "Confidence" SG_ 1297 RCM_a103_eventDiagEnabled 1;
BA_ "Confidence" SG_ 1297 RCM_a103_eventDriveOrientation 1;
BA_ "Confidence" SG_ 1297 RCM_a103_eventIDFsignal 1;
BA_ "Confidence" SG_ 1297 RCM_a103_eventFrontLeftSeatbelt 1;
BA_ "Confidence" SG_ 1297 RCM_a103_eventFrontRightSeatbelt 1;
BA_ "Confidence" SG_ 1297 RCM_a103_eventVehicleSpeed 1;
BA_ "Confidence" SG_ 1297 RCM_a103_eventSteeringAngle 1;
BA_ "Confidence" SG_ 1297 RCM_a103_eventDriverBrakeApply 1;
BA_ "GenSigSNA" SG_ 1297 RCM_a103_eventDriverBrakeApply "3";
BA_ "Confidence" SG_ 1297 RCM_a103_eventAccelPedalPos 1;
BA_ "GenSigSNA" SG_ 1297 RCM_a103_eventAccelPedalPos "255";
BA_ "Confidence" SG_ 1297 RCM_a104_eventArmStatus 1;
BA_ "Confidence" SG_ 1297 RCM_a104_eventFactoryMode 1;
BA_ "Confidence" SG_ 1297 RCM_a104_eventDiagEnabled 1;
BA_ "Confidence" SG_ 1297 RCM_a104_eventDriveOrientation 1;
BA_ "Confidence" SG_ 1297 RCM_a104_eventIDFsignal 1;
BA_ "Confidence" SG_ 1297 RCM_a104_eventFrontLeftSeatbelt 1;
BA_ "Confidence" SG_ 1297 RCM_a104_eventFrontRightSeatbelt 1;
BA_ "Confidence" SG_ 1297 RCM_a104_eventVehicleSpeed 1;
BA_ "Confidence" SG_ 1297 RCM_a104_eventSteeringAngle 1;
BA_ "Confidence" SG_ 1297 RCM_a104_eventDriverBrakeApply 1;
BA_ "GenSigSNA" SG_ 1297 RCM_a104_eventDriverBrakeApply "3";
BA_ "Confidence" SG_ 1297 RCM_a104_eventAccelPedalPos 1;
BA_ "GenSigSNA" SG_ 1297 RCM_a104_eventAccelPedalPos "255";
BA_ "Confidence" SG_ 1297 RCM_a105_eventArmStatus 1;
BA_ "Confidence" SG_ 1297 RCM_a105_eventFactoryMode 1;
BA_ "Confidence" SG_ 1297 RCM_a105_eventDiagEnabled 1;
BA_ "Confidence" SG_ 1297 RCM_a105_eventDriveOrientation 1;
BA_ "Confidence" SG_ 1297 RCM_a105_eventIDFsignal 1;
BA_ "Confidence" SG_ 1297 RCM_a105_eventFrontLeftSeatbelt 1;
BA_ "Confidence" SG_ 1297 RCM_a105_eventFrontRightSeatbelt 1;
BA_ "Confidence" SG_ 1297 RCM_a105_eventVehicleSpeed 1;
BA_ "Confidence" SG_ 1297 RCM_a105_eventSteeringAngle 1;
BA_ "Confidence" SG_ 1297 RCM_a105_eventDriverBrakeApply 1;
BA_ "GenSigSNA" SG_ 1297 RCM_a105_eventDriverBrakeApply "3";
BA_ "Confidence" SG_ 1297 RCM_a105_eventAccelPedalPos 1;
BA_ "GenSigSNA" SG_ 1297 RCM_a105_eventAccelPedalPos "255";
BA_ "Confidence" SG_ 1297 RCM_a106_eventArmStatus 1;
BA_ "Confidence" SG_ 1297 RCM_a106_eventFactoryMode 1;
BA_ "Confidence" SG_ 1297 RCM_a106_eventDiagEnabled 1;
BA_ "Confidence" SG_ 1297 RCM_a106_eventDriveOrientation 1;
BA_ "Confidence" SG_ 1297 RCM_a106_eventIDFsignal 1;
BA_ "Confidence" SG_ 1297 RCM_a106_eventFrontLeftSeatbelt 1;
BA_ "Confidence" SG_ 1297 RCM_a106_eventFrontRightSeatbelt 1;
BA_ "Confidence" SG_ 1297 RCM_a106_eventVehicleSpeed 1;
BA_ "Confidence" SG_ 1297 RCM_a106_eventSteeringAngle 1;
BA_ "Confidence" SG_ 1297 RCM_a106_eventDriverBrakeApply 1;
BA_ "GenSigSNA" SG_ 1297 RCM_a106_eventDriverBrakeApply "3";
BA_ "Confidence" SG_ 1297 RCM_a106_eventAccelPedalPos 1;
BA_ "GenSigSNA" SG_ 1297 RCM_a106_eventAccelPedalPos "255";
BA_ "Confidence" SG_ 1297 RCM_a107_eventArmStatus 1;
BA_ "Confidence" SG_ 1297 RCM_a107_eventFactoryMode 1;
BA_ "Confidence" SG_ 1297 RCM_a107_eventDiagEnabled 1;
BA_ "Confidence" SG_ 1297 RCM_a107_eventDriveOrientation 1;
BA_ "Confidence" SG_ 1297 RCM_a107_eventIDFsignal 1;
BA_ "Confidence" SG_ 1297 RCM_a107_eventFrontLeftSeatbelt 1;
BA_ "Confidence" SG_ 1297 RCM_a107_eventFrontRightSeatbelt 1;
BA_ "Confidence" SG_ 1297 RCM_a107_eventVehicleSpeed 1;
BA_ "Confidence" SG_ 1297 RCM_a107_eventSteeringAngle 1;
BA_ "Confidence" SG_ 1297 RCM_a107_eventDriverBrakeApply 1;
BA_ "GenSigSNA" SG_ 1297 RCM_a107_eventDriverBrakeApply "3";
BA_ "Confidence" SG_ 1297 RCM_a107_eventAccelPedalPos 1;
BA_ "GenSigSNA" SG_ 1297 RCM_a107_eventAccelPedalPos "255";
BA_ "Confidence" SG_ 1297 RCM_a108_eventArmStatus 1;
BA_ "Confidence" SG_ 1297 RCM_a108_eventFactoryMode 1;
BA_ "Confidence" SG_ 1297 RCM_a108_eventDiagEnabled 1;
BA_ "Confidence" SG_ 1297 RCM_a108_eventDriveOrientation 1;
BA_ "Confidence" SG_ 1297 RCM_a108_eventIDFsignal 1;
BA_ "Confidence" SG_ 1297 RCM_a108_eventFrontLeftSeatbelt 1;
BA_ "Confidence" SG_ 1297 RCM_a108_eventFrontRightSeatbelt 1;
BA_ "Confidence" SG_ 1297 RCM_a108_eventVehicleSpeed 1;
BA_ "Confidence" SG_ 1297 RCM_a108_eventSteeringAngle 1;
BA_ "Confidence" SG_ 1297 RCM_a108_eventDriverBrakeApply 1;
BA_ "GenSigSNA" SG_ 1297 RCM_a108_eventDriverBrakeApply "3";
BA_ "Confidence" SG_ 1297 RCM_a108_eventAccelPedalPos 1;
BA_ "GenSigSNA" SG_ 1297 RCM_a108_eventAccelPedalPos "255";
BA_ "Confidence" SG_ 1297 RCM_a109_eventArmStatus 1;
BA_ "Confidence" SG_ 1297 RCM_a109_eventFactoryMode 1;
BA_ "Confidence" SG_ 1297 RCM_a109_eventDiagEnabled 1;
BA_ "Confidence" SG_ 1297 RCM_a109_eventDriveOrientation 1;
BA_ "Confidence" SG_ 1297 RCM_a109_eventIDFsignal 1;
BA_ "Confidence" SG_ 1297 RCM_a109_eventFrontLeftSeatbelt 1;
BA_ "Confidence" SG_ 1297 RCM_a109_eventFrontRightSeatbelt 1;
BA_ "Confidence" SG_ 1297 RCM_a109_eventVehicleSpeed 1;
BA_ "Confidence" SG_ 1297 RCM_a109_eventSteeringAngle 1;
BA_ "Confidence" SG_ 1297 RCM_a109_eventDriverBrakeApply 1;
BA_ "GenSigSNA" SG_ 1297 RCM_a109_eventDriverBrakeApply "3";
BA_ "Confidence" SG_ 1297 RCM_a109_eventAccelPedalPos 1;
BA_ "GenSigSNA" SG_ 1297 RCM_a109_eventAccelPedalPos "255";
BA_ "Confidence" SG_ 1297 RCM_a110_eventArmStatus 1;
BA_ "Confidence" SG_ 1297 RCM_a110_eventFactoryMode 1;
BA_ "Confidence" SG_ 1297 RCM_a110_eventDiagEnabled 1;
BA_ "Confidence" SG_ 1297 RCM_a110_eventDriveOrientation 1;
BA_ "Confidence" SG_ 1297 RCM_a110_eventIDFsignal 1;
BA_ "Confidence" SG_ 1297 RCM_a110_eventFrontLeftSeatbelt 1;
BA_ "Confidence" SG_ 1297 RCM_a110_eventFrontRightSeatbelt 1;
BA_ "Confidence" SG_ 1297 RCM_a110_eventVehicleSpeed 1;
BA_ "Confidence" SG_ 1297 RCM_a110_eventSteeringAngle 1;
BA_ "Confidence" SG_ 1297 RCM_a110_eventDriverBrakeApply 1;
BA_ "GenSigSNA" SG_ 1297 RCM_a110_eventDriverBrakeApply "3";
BA_ "Confidence" SG_ 1297 RCM_a110_eventAccelPedalPos 1;
BA_ "GenSigSNA" SG_ 1297 RCM_a110_eventAccelPedalPos "255";
BA_ "Confidence" SG_ 1297 RCM_a112_eventArmStatus 1;
BA_ "Confidence" SG_ 1297 RCM_a112_eventFactoryMode 1;
BA_ "Confidence" SG_ 1297 RCM_a112_eventDiagEnabled 1;
BA_ "Confidence" SG_ 1297 RCM_a112_eventDriveOrientation 1;
BA_ "Confidence" SG_ 1297 RCM_a112_eventIDFsignal 1;
BA_ "Confidence" SG_ 1297 RCM_a112_eventFrontLeftSeatbelt 1;
BA_ "Confidence" SG_ 1297 RCM_a112_eventFrontRightSeatbelt 1;
BA_ "Confidence" SG_ 1297 RCM_a112_eventVehicleSpeed 1;
BA_ "Confidence" SG_ 1297 RCM_a112_eventSteeringAngle 1;
BA_ "Confidence" SG_ 1297 RCM_a112_eventDriverBrakeApply 1;
BA_ "GenSigSNA" SG_ 1297 RCM_a112_eventDriverBrakeApply "3";
BA_ "Confidence" SG_ 1297 RCM_a112_eventAccelPedalPos 1;
BA_ "GenSigSNA" SG_ 1297 RCM_a112_eventAccelPedalPos "255";
BA_ "Confidence" SG_ 1297 RCM_a113_eventArmStatus 1;
BA_ "Confidence" SG_ 1297 RCM_a113_eventFactoryMode 1;
BA_ "Confidence" SG_ 1297 RCM_a113_eventDiagEnabled 1;
BA_ "Confidence" SG_ 1297 RCM_a113_eventDriveOrientation 1;
BA_ "Confidence" SG_ 1297 RCM_a113_eventIDFsignal 1;
BA_ "Confidence" SG_ 1297 RCM_a113_eventFrontLeftSeatbelt 1;
BA_ "Confidence" SG_ 1297 RCM_a113_eventFrontRightSeatbelt 1;
BA_ "Confidence" SG_ 1297 RCM_a113_eventVehicleSpeed 1;
BA_ "Confidence" SG_ 1297 RCM_a113_eventSteeringAngle 1;
BA_ "Confidence" SG_ 1297 RCM_a113_eventDriverBrakeApply 1;
BA_ "GenSigSNA" SG_ 1297 RCM_a113_eventDriverBrakeApply "3";
BA_ "Confidence" SG_ 1297 RCM_a113_eventAccelPedalPos 1;
BA_ "GenSigSNA" SG_ 1297 RCM_a113_eventAccelPedalPos "255";
BA_ "Confidence" SG_ 1297 RCM_a114_eventArmStatus 1;
BA_ "Confidence" SG_ 1297 RCM_a114_eventFactoryMode 1;
BA_ "Confidence" SG_ 1297 RCM_a114_eventDiagEnabled 1;
BA_ "Confidence" SG_ 1297 RCM_a114_eventDriveOrientation 1;
BA_ "Confidence" SG_ 1297 RCM_a114_eventIDFsignal 1;
BA_ "Confidence" SG_ 1297 RCM_a114_eventFrontLeftSeatbelt 1;
BA_ "Confidence" SG_ 1297 RCM_a114_eventFrontRightSeatbelt 1;
BA_ "Confidence" SG_ 1297 RCM_a114_eventVehicleSpeed 1;
BA_ "Confidence" SG_ 1297 RCM_a114_eventSteeringAngle 1;
BA_ "Confidence" SG_ 1297 RCM_a114_eventDriverBrakeApply 1;
BA_ "GenSigSNA" SG_ 1297 RCM_a114_eventDriverBrakeApply "3";
BA_ "Confidence" SG_ 1297 RCM_a114_eventAccelPedalPos 1;
BA_ "GenSigSNA" SG_ 1297 RCM_a114_eventAccelPedalPos "255";
BA_ "Confidence" SG_ 1297 RCM_a115_eventArmStatus 1;
BA_ "Confidence" SG_ 1297 RCM_a115_eventFactoryMode 1;
BA_ "Confidence" SG_ 1297 RCM_a115_eventDiagEnabled 1;
BA_ "Confidence" SG_ 1297 RCM_a115_eventDriveOrientation 1;
BA_ "Confidence" SG_ 1297 RCM_a115_eventIDFsignal 1;
BA_ "Confidence" SG_ 1297 RCM_a115_eventFrontLeftSeatbelt 1;
BA_ "Confidence" SG_ 1297 RCM_a115_eventFrontRightSeatbelt 1;
BA_ "Confidence" SG_ 1297 RCM_a115_eventVehicleSpeed 1;
BA_ "Confidence" SG_ 1297 RCM_a115_eventSteeringAngle 1;
BA_ "Confidence" SG_ 1297 RCM_a115_eventDriverBrakeApply 1;
BA_ "GenSigSNA" SG_ 1297 RCM_a115_eventDriverBrakeApply "3";
BA_ "Confidence" SG_ 1297 RCM_a115_eventAccelPedalPos 1;
BA_ "GenSigSNA" SG_ 1297 RCM_a115_eventAccelPedalPos "255";
BA_ "Confidence" SG_ 1297 RCM_a116_eventArmStatus 1;
BA_ "Confidence" SG_ 1297 RCM_a116_eventFactoryMode 1;
BA_ "Confidence" SG_ 1297 RCM_a116_eventDiagEnabled 1;
BA_ "Confidence" SG_ 1297 RCM_a116_eventDriveOrientation 1;
BA_ "Confidence" SG_ 1297 RCM_a116_eventIDFsignal 1;
BA_ "Confidence" SG_ 1297 RCM_a116_eventFrontLeftSeatbelt 1;
BA_ "Confidence" SG_ 1297 RCM_a116_eventFrontRightSeatbelt 1;
BA_ "Confidence" SG_ 1297 RCM_a116_eventVehicleSpeed 1;
BA_ "Confidence" SG_ 1297 RCM_a116_eventSteeringAngle 1;
BA_ "Confidence" SG_ 1297 RCM_a116_eventDriverBrakeApply 1;
BA_ "GenSigSNA" SG_ 1297 RCM_a116_eventDriverBrakeApply "3";
BA_ "Confidence" SG_ 1297 RCM_a116_eventAccelPedalPos 1;
BA_ "GenSigSNA" SG_ 1297 RCM_a116_eventAccelPedalPos "255";
BA_ "Confidence" SG_ 1297 RCM_a117_eventArmStatus 1;
BA_ "Confidence" SG_ 1297 RCM_a117_eventFactoryMode 1;
BA_ "Confidence" SG_ 1297 RCM_a117_eventDiagEnabled 1;
BA_ "Confidence" SG_ 1297 RCM_a117_eventDriveOrientation 1;
BA_ "Confidence" SG_ 1297 RCM_a117_eventIDFsignal 1;
BA_ "Confidence" SG_ 1297 RCM_a117_eventFrontLeftSeatbelt 1;
BA_ "Confidence" SG_ 1297 RCM_a117_eventFrontRightSeatbelt 1;
BA_ "Confidence" SG_ 1297 RCM_a117_eventVehicleSpeed 1;
BA_ "Confidence" SG_ 1297 RCM_a117_eventSteeringAngle 1;
BA_ "Confidence" SG_ 1297 RCM_a117_eventDriverBrakeApply 1;
BA_ "GenSigSNA" SG_ 1297 RCM_a117_eventDriverBrakeApply "3";
BA_ "Confidence" SG_ 1297 RCM_a117_eventAccelPedalPos 1;
BA_ "GenSigSNA" SG_ 1297 RCM_a117_eventAccelPedalPos "255";
BA_ "Confidence" SG_ 1297 RCM_a118_eventArmStatus 1;
BA_ "Confidence" SG_ 1297 RCM_a118_eventFactoryMode 1;
BA_ "Confidence" SG_ 1297 RCM_a118_eventDiagEnabled 1;
BA_ "Confidence" SG_ 1297 RCM_a118_eventDriveOrientation 1;
BA_ "Confidence" SG_ 1297 RCM_a118_eventIDFsignal 1;
BA_ "Confidence" SG_ 1297 RCM_a118_eventFrontLeftSeatbelt 1;
BA_ "Confidence" SG_ 1297 RCM_a118_eventFrontRightSeatbelt 1;
BA_ "Confidence" SG_ 1297 RCM_a118_eventVehicleSpeed 1;
BA_ "Confidence" SG_ 1297 RCM_a118_eventSteeringAngle 1;
BA_ "Confidence" SG_ 1297 RCM_a118_eventDriverBrakeApply 1;
BA_ "GenSigSNA" SG_ 1297 RCM_a118_eventDriverBrakeApply "3";
BA_ "Confidence" SG_ 1297 RCM_a118_eventAccelPedalPos 1;
BA_ "GenSigSNA" SG_ 1297 RCM_a118_eventAccelPedalPos "255";
BA_ "Confidence" SG_ 881 RCM_matrixIndex 1;
BA_ "Confidence" SG_ 17 RCM_collisionChecksum 0;
BA_ "Confidence" SG_ 17 RCM_collisionCounter 0;
BA_ "Confidence" SG_ 17 RCM_collisionRear 0;
BA_ "GenSigSNA" SG_ 17 RCM_collisionRear "3";
BA_ "Confidence" SG_ 17 RCM_collisionRight 0;
BA_ "GenSigSNA" SG_ 17 RCM_collisionRight "3";
BA_ "Confidence" SG_ 17 RCM_collisionLeft 0;
BA_ "GenSigSNA" SG_ 17 RCM_collisionLeft "3";
BA_ "Confidence" SG_ 17 RCM_collisionFront 0;
BA_ "GenSigSNA" SG_ 17 RCM_collisionFront "3";
BA_ "Confidence" SG_ 17 RCM_collisionRollover 0;
BA_ "GenSigSNA" SG_ 17 RCM_collisionRollover "3";
BA_ "Confidence" SG_ 17 RCM_collisionPedPro 0;
BA_ "GenSigSNA" SG_ 17 RCM_collisionPedPro "3";
BA_ "Confidence" SG_ 17 RCM_collisionSeverity 0;
BA_ "Confidence" SG_ 257 RCM_yawRate 0;
BA_ "GenSigSNA" SG_ 257 RCM_yawRate "32768";
BA_ "Confidence" SG_ 257 RCM_pitchRate 0;
BA_ "GenSigSNA" SG_ 257 RCM_pitchRate "16384";
BA_ "Confidence" SG_ 257 RCM_rollRate 0;
BA_ "GenSigSNA" SG_ 257 RCM_rollRate "16384";
BA_ "Confidence" SG_ 257 RCM_rollRateQF 0;
BA_ "Confidence" SG_ 257 RCM_yawRateQF 0;
BA_ "Confidence" SG_ 257 RCM_pitchRateQF 0;
BA_ "Confidence" SG_ 257 RCM_inertial1Counter 0;
BA_ "Confidence" SG_ 257 RCM_inertial1Checksum 0;
BA_ "Confidence" SG_ 278 RCM_longitudinalAccel 0;
BA_ "GenSigSNA" SG_ 278 RCM_longitudinalAccel "32768";
BA_ "Confidence" SG_ 278 RCM_lateralAccel 0;
BA_ "GenSigSNA" SG_ 278 RCM_lateralAccel "32768";
BA_ "Confidence" SG_ 278 RCM_verticalAccel 0;
BA_ "GenSigSNA" SG_ 278 RCM_verticalAccel "32768";
BA_ "Confidence" SG_ 278 RCM_longitudinalAccelQF 0;
BA_ "Confidence" SG_ 278 RCM_lateralAccelQF 0;
BA_ "Confidence" SG_ 278 RCM_verticalAccelQF 0;
BA_ "Confidence" SG_ 278 RCM_CGTranslationFault 0;
BA_ "Confidence" SG_ 278 RCM_inertial2Counter 0;
BA_ "Confidence" SG_ 278 RCM_inertial2Checksum 0;
BA_ "Confidence" SG_ 849 RCM_infoIndex 1;
BA_ "Confidence" SG_ 849 RCM_infoBuildType 0;
BA_ "Confidence" SG_ 849 RCM_infoComponentID 0;
BA_ "Confidence" SG_ 849 RCM_infoPcbaID 0;
BA_ "Confidence" SG_ 849 RCM_infoAssemblyID 0;
BA_ "Confidence" SG_ 849 RCM_infoUsageID 0;
BA_ "Confidence" SG_ 849 RCM_infoApplicationCRC 0;
BA_ "Confidence" SG_ 849 RCM_infoBootUdsProtoVersion 0;
BA_ "Confidence" SG_ 849 RCM_infoBootloaderCRC 0;
BA_ "Confidence" SG_ 849 RCM_infoAlgoCalID 0;
BA_ "Confidence" SG_ 849 RCM_infoVariantCRC 0;
BA_ "Confidence" SG_ 2032 RCM_nearDeployChecksum 0;
BA_ "Confidence" SG_ 2032 RCM_nearDeployCounter 0;
BA_ "Confidence" SG_ 2032 RCM_nearDeployRear 0;
BA_ "GenSigSNA" SG_ 2032 RCM_nearDeployRear "3";
BA_ "Confidence" SG_ 2032 RCM_nearDeployRight 0;
BA_ "GenSigSNA" SG_ 2032 RCM_nearDeployRight "3";
BA_ "Confidence" SG_ 2032 RCM_nearDeployLeft 0;
BA_ "GenSigSNA" SG_ 2032 RCM_nearDeployLeft "3";
BA_ "Confidence" SG_ 2032 RCM_nearDeployFront 0;
BA_ "GenSigSNA" SG_ 2032 RCM_nearDeployFront "3";
BA_ "Confidence" SG_ 2032 RCM_nearDeployRollover 0;
BA_ "GenSigSNA" SG_ 2032 RCM_nearDeployRollover "3";
BA_ "Confidence" SG_ 2032 RCM_crashAlgoWakeup 0;
BA_ "GenSigSNA" SG_ 2032 RCM_crashAlgoWakeup "3";
BA_ "Confidence" SG_ 529 RCM_statusChecksum 0;
BA_ "Confidence" SG_ 529 RCM_statusCounter 0;
BA_ "Confidence" SG_ 529 RCM_armStatus 0;
BA_ "GenSigSNA" SG_ 529 RCM_armStatus "3";
BA_ "Confidence" SG_ 529 RCM_warningIndicatorState 0;
BA_ "GenSigSNA" SG_ 529 RCM_warningIndicatorState "3";
BA_ "Confidence" SG_ 529 RCM_passAirbagIndicatorRequest 0;
BA_ "GenSigSNA" SG_ 529 RCM_passAirbagIndicatorRequest "3";
BA_ "Confidence" SG_ 529 RCM_airbagCutoffStatus 0;
BA_ "GenSigSNA" SG_ 529 RCM_airbagCutoffStatus "3";
BA_ "Confidence" SG_ 529 RCM_alrSwitchStatus 0;
BA_ "GenSigSNA" SG_ 529 RCM_alrSwitchStatus "3";
BA_ "Confidence" SG_ 529 RCM_vinLearnFlag 0;
BA_ "GenSigSNA" SG_ 529 RCM_vinLearnFlag "3";
BA_ "Confidence" SG_ 529 RCM_seatTrackPositionDrvr 0;
BA_ "GenSigSNA" SG_ 529 RCM_seatTrackPositionDrvr "3";
BA_ "Confidence" SG_ 529 RCM_seatTrackPositionPass 0;
BA_ "GenSigSNA" SG_ 529 RCM_seatTrackPositionPass "3";
BA_ "Confidence" SG_ 529 RCM_edr1State 0;
BA_ "Confidence" SG_ 529 RCM_edr2State 0;
BA_ "Confidence" SG_ 529 RCM_keepPowerReason 0;
BA_ "GenSigSNA" SG_ 529 RCM_keepPowerReason "8";
BA_ "Confidence" SG_ 529 RCM_imuOffsetLearnState 0;
BA_ "Confidence" SG_ 529 RCM_edr3State 0;
BA_ "Confidence" SG_ 529 RCM_driverOrientationInitStatus 0;
BA_ "GenSigSNA" SG_ 529 RCM_driverOrientationInitStatus "7";
BA_ "Confidence" SG_ 529 RCM_occupantClassificationSource 0;
BA_ "Confidence" SG_ 529 RCM_pedProEDR1State 0;
BA_ "Confidence" SG_ 529 RCM_pedProEDR2State 0;
BA_ "Confidence" SG_ 1471 RCU_alertID 1;
BA_ "Confidence" SG_ 1471 RCU_alertState 1;
BA_ "Confidence" SG_ 1471 RCU_a010_sensorPowerSupply 1;
BA_ "Confidence" SG_ 1471 RCU_a010_sensorHardware 1;
BA_ "Confidence" SG_ 1471 RCU_a010_sensorSignal 1;
BA_ "Confidence" SG_ 1471 RCU_a023_validityOnChassisBus 1;
BA_ "Confidence" SG_ 1471 RCU_a023_validityOnPartyBus 1;
BA_ "Confidence" SG_ 1471 RCU_a024_validityOnChassisBus 1;
BA_ "Confidence" SG_ 1471 RCU_a024_validityOnPartyBus 1;
BA_ "Confidence" SG_ 1471 RCU_a025_validityOnChassisBus 1;
BA_ "Confidence" SG_ 1471 RCU_a025_validityOnPartyBus 1;
BA_ "Confidence" SG_ 1471 RCU_a035_validityOnChassisBus 1;
BA_ "Confidence" SG_ 1471 RCU_a035_validityOnPartyBus 1;
BA_ "Confidence" SG_ 1471 RCU_a036_validityOnChassisBus 1;
BA_ "Confidence" SG_ 1471 RCU_a036_validityOnPartyBus 1;
VAL_ 1297 RCM_a069_eventDriveOrientation 1 "RIGHT_HAND_DRIVE" 0 "LEFT_HAND_DRIVE" ;
VAL_ 1297 RCM_a069_eventIDFsignal 1 "ACTIVE" 0 "NOT_ACTIVE" ;
VAL_ 1297 RCM_a069_eventFrontLeftSeatbelt 1 "LATCHED" 0 "UNLATCHED" ;
VAL_ 1297 RCM_a069_eventFrontRightSeatbelt 1 "LATCHED" 0 "UNLATCHED" ;
VAL_ 1297 RCM_a069_eventDriverBrakeApply 3 "Faulty_SNA" 2 "Driver_applying_brakes" 1 "Not_Applied" 0 "NotInit_orOff" ;
VAL_ 1297 RCM_a069_eventAccelPedalPos 255 "SNA" ;
VAL_ 1297 RCM_a070_eventArmStatus 1 "ARMED" 0 "UNARMED" ;
VAL_ 1297 RCM_a070_eventFactoryMode 1 "ENABLED" 0 "DISABLED" ;
VAL_ 1297 RCM_a070_eventDiagEnabled 1 "ENABLED" 0 "DISABLED" ;
VAL_ 1297 RCM_a070_eventDriveOrientation 1 "RIGHT_HAND_DRIVE" 0 "LEFT_HAND_DRIVE" ;
VAL_ 1297 RCM_a070_eventIDFsignal 1 "ACTIVE" 0 "NOT_ACTIVE" ;
VAL_ 1297 RCM_a070_eventFrontLeftSeatbelt 1 "LATCHED" 0 "UNLATCHED" ;
VAL_ 1297 RCM_a070_eventFrontRightSeatbelt 1 "LATCHED" 0 "UNLATCHED" ;
VAL_ 1297 RCM_a070_eventDriverBrakeApply 3 "Faulty_SNA" 2 "Driver_applying_brakes" 1 "Not_Applied" 0 "NotInit_orOff" ;
VAL_ 1297 RCM_a070_eventAccelPedalPos 255 "SNA" ;
VAL_ 1297 RCM_a071_eventArmStatus 1 "ARMED" 0 "UNARMED" ;
VAL_ 1297 RCM_a071_eventFactoryMode 1 "ENABLED" 0 "DISABLED" ;
VAL_ 1297 RCM_a071_eventDiagEnabled 1 "ENABLED" 0 "DISABLED" ;
VAL_ 1297 RCM_a071_eventDriveOrientation 1 "RIGHT_HAND_DRIVE" 0 "LEFT_HAND_DRIVE" ;
VAL_ 1297 RCM_a071_eventIDFsignal 1 "ACTIVE" 0 "NOT_ACTIVE" ;
VAL_ 1297 RCM_a071_eventFrontLeftSeatbelt 1 "LATCHED" 0 "UNLATCHED" ;
VAL_ 1297 RCM_a071_eventFrontRightSeatbelt 1 "LATCHED" 0 "UNLATCHED" ;
VAL_ 1297 RCM_a071_eventDriverBrakeApply 3 "Faulty_SNA" 2 "Driver_applying_brakes" 1 "Not_Applied" 0 "NotInit_orOff" ;
VAL_ 1297 RCM_a071_eventAccelPedalPos 255 "SNA" ;
VAL_ 1297 RCM_a072_eventArmStatus 1 "ARMED" 0 "UNARMED" ;
VAL_ 1297 RCM_a072_eventFactoryMode 1 "ENABLED" 0 "DISABLED" ;
VAL_ 1297 RCM_a072_eventDiagEnabled 1 "ENABLED" 0 "DISABLED" ;
VAL_ 1297 RCM_a072_eventDriveOrientation 1 "RIGHT_HAND_DRIVE" 0 "LEFT_HAND_DRIVE" ;
VAL_ 1297 RCM_a072_eventIDFsignal 1 "ACTIVE" 0 "NOT_ACTIVE" ;
VAL_ 1297 RCM_a072_eventFrontLeftSeatbelt 1 "LATCHED" 0 "UNLATCHED" ;
VAL_ 1297 RCM_a072_eventFrontRightSeatbelt 1 "LATCHED" 0 "UNLATCHED" ;
VAL_ 1297 RCM_a072_eventDriverBrakeApply 3 "Faulty_SNA" 2 "Driver_applying_brakes" 1 "Not_Applied" 0 "NotInit_orOff" ;
VAL_ 1297 RCM_a072_eventAccelPedalPos 255 "SNA" ;
VAL_ 1297 RCM_a073_eventArmStatus 1 "ARMED" 0 "UNARMED" ;
VAL_ 1297 RCM_a073_eventFactoryMode 1 "ENABLED" 0 "DISABLED" ;
VAL_ 1297 RCM_a073_eventDiagEnabled 1 "ENABLED" 0 "DISABLED" ;
VAL_ 1297 RCM_a073_eventDriveOrientation 1 "RIGHT_HAND_DRIVE" 0 "LEFT_HAND_DRIVE" ;
VAL_ 1297 RCM_a073_eventIDFsignal 1 "ACTIVE" 0 "NOT_ACTIVE" ;
VAL_ 1297 RCM_a073_eventFrontLeftSeatbelt 1 "LATCHED" 0 "UNLATCHED" ;
VAL_ 1297 RCM_a073_eventFrontRightSeatbelt 1 "LATCHED" 0 "UNLATCHED" ;
VAL_ 1297 RCM_a073_eventDriverBrakeApply 3 "Faulty_SNA" 2 "Driver_applying_brakes" 1 "Not_Applied" 0 "NotInit_orOff" ;
VAL_ 1297 RCM_a073_eventAccelPedalPos 255 "SNA" ;
VAL_ 1297 RCM_a074_eventArmStatus 1 "ARMED" 0 "UNARMED" ;
VAL_ 1297 RCM_a074_eventFactoryMode 1 "ENABLED" 0 "DISABLED" ;
VAL_ 1297 RCM_a074_eventDiagEnabled 1 "ENABLED" 0 "DISABLED" ;
VAL_ 1297 RCM_a074_eventDriveOrientation 1 "RIGHT_HAND_DRIVE" 0 "LEFT_HAND_DRIVE" ;
VAL_ 1297 RCM_a074_eventIDFsignal 1 "ACTIVE" 0 "NOT_ACTIVE" ;
VAL_ 1297 RCM_a074_eventFrontLeftSeatbelt 1 "LATCHED" 0 "UNLATCHED" ;
VAL_ 1297 RCM_a074_eventFrontRightSeatbelt 1 "LATCHED" 0 "UNLATCHED" ;
VAL_ 1297 RCM_a074_eventDriverBrakeApply 3 "Faulty_SNA" 2 "Driver_applying_brakes" 1 "Not_Applied" 0 "NotInit_orOff" ;
VAL_ 1297 RCM_a074_eventAccelPedalPos 255 "SNA" ;
VAL_ 1297 RCM_a075_eventArmStatus 1 "ARMED" 0 "UNARMED" ;
VAL_ 1297 RCM_a075_eventFactoryMode 1 "ENABLED" 0 "DISABLED" ;
VAL_ 1297 RCM_a075_eventDiagEnabled 1 "ENABLED" 0 "DISABLED" ;
VAL_ 1297 RCM_a075_eventDriveOrientation 1 "RIGHT_HAND_DRIVE" 0 "LEFT_HAND_DRIVE" ;
VAL_ 1297 RCM_a075_eventIDFsignal 1 "ACTIVE" 0 "NOT_ACTIVE" ;
VAL_ 1297 RCM_a075_eventFrontLeftSeatbelt 1 "LATCHED" 0 "UNLATCHED" ;
VAL_ 1297 RCM_a075_eventFrontRightSeatbelt 1 "LATCHED" 0 "UNLATCHED" ;
VAL_ 1297 RCM_a075_eventDriverBrakeApply 3 "Faulty_SNA" 2 "Driver_applying_brakes" 1 "Not_Applied" 0 "NotInit_orOff" ;
VAL_ 1297 RCM_a075_eventAccelPedalPos 255 "SNA" ;
VAL_ 1297 RCM_a078_eventArmStatus 1 "ARMED" 0 "UNARMED" ;
VAL_ 1297 RCM_a078_eventFactoryMode 1 "ENABLED" 0 "DISABLED" ;
VAL_ 1297 RCM_a078_eventDiagEnabled 1 "ENABLED" 0 "DISABLED" ;
VAL_ 1297 RCM_a078_eventDriveOrientation 1 "RIGHT_HAND_DRIVE" 0 "LEFT_HAND_DRIVE" ;
VAL_ 1297 RCM_a078_eventIDFsignal 1 "ACTIVE" 0 "NOT_ACTIVE" ;
VAL_ 1297 RCM_a078_eventFrontLeftSeatbelt 1 "LATCHED" 0 "UNLATCHED" ;
VAL_ 1297 RCM_a078_eventFrontRightSeatbelt 1 "LATCHED" 0 "UNLATCHED" ;
VAL_ 1297 RCM_a078_eventDriverBrakeApply 3 "Faulty_SNA" 2 "Driver_applying_brakes" 1 "Not_Applied" 0 "NotInit_orOff" ;
VAL_ 1297 RCM_a078_eventAccelPedalPos 255 "SNA" ;
VAL_ 1297 RCM_a079_eventArmStatus 1 "ARMED" 0 "UNARMED" ;
VAL_ 1297 RCM_a079_eventFactoryMode 1 "ENABLED" 0 "DISABLED" ;
VAL_ 1297 RCM_a079_eventDiagEnabled 1 "ENABLED" 0 "DISABLED" ;
VAL_ 1297 RCM_a079_eventDriveOrientation 1 "RIGHT_HAND_DRIVE" 0 "LEFT_HAND_DRIVE" ;
VAL_ 1297 RCM_a079_eventIDFsignal 1 "ACTIVE" 0 "NOT_ACTIVE" ;
VAL_ 1297 RCM_a079_eventFrontLeftSeatbelt 1 "LATCHED" 0 "UNLATCHED" ;
VAL_ 1297 RCM_a079_eventFrontRightSeatbelt 1 "LATCHED" 0 "UNLATCHED" ;
VAL_ 1297 RCM_a079_eventDriverBrakeApply 3 "Faulty_SNA" 2 "Driver_applying_brakes" 1 "Not_Applied" 0 "NotInit_orOff" ;
VAL_ 1297 RCM_a079_eventAccelPedalPos 255 "SNA" ;
VAL_ 1297 RCM_a080_eventArmStatus 1 "ARMED" 0 "UNARMED" ;
VAL_ 1297 RCM_a080_eventFactoryMode 1 "ENABLED" 0 "DISABLED" ;
VAL_ 1297 RCM_a080_eventDiagEnabled 1 "ENABLED" 0 "DISABLED" ;
VAL_ 1297 RCM_a080_eventDriveOrientation 1 "RIGHT_HAND_DRIVE" 0 "LEFT_HAND_DRIVE" ;
VAL_ 1297 RCM_a080_eventIDFsignal 1 "ACTIVE" 0 "NOT_ACTIVE" ;
VAL_ 1297 RCM_a080_eventFrontLeftSeatbelt 1 "LATCHED" 0 "UNLATCHED" ;
VAL_ 1297 RCM_a080_eventFrontRightSeatbelt 1 "LATCHED" 0 "UNLATCHED" ;
VAL_ 1297 RCM_a080_eventDriverBrakeApply 3 "Faulty_SNA" 2 "Driver_applying_brakes" 1 "Not_Applied" 0 "NotInit_orOff" ;
VAL_ 1297 RCM_a080_eventAccelPedalPos 255 "SNA" ;
VAL_ 1297 RCM_a083_eventArmStatus 1 "ARMED" 0 "UNARMED" ;
VAL_ 1297 RCM_a083_eventFactoryMode 1 "ENABLED" 0 "DISABLED" ;
VAL_ 1297 RCM_a083_eventDiagEnabled 1 "ENABLED" 0 "DISABLED" ;
VAL_ 1297 RCM_a083_eventDriveOrientation 1 "RIGHT_HAND_DRIVE" 0 "LEFT_HAND_DRIVE" ;
VAL_ 1297 RCM_a083_eventIDFsignal 1 "ACTIVE" 0 "NOT_ACTIVE" ;
VAL_ 1297 RCM_a083_eventFrontLeftSeatbelt 1 "LATCHED" 0 "UNLATCHED" ;
VAL_ 1297 RCM_a083_eventFrontRightSeatbelt 1 "LATCHED" 0 "UNLATCHED" ;
VAL_ 1297 RCM_a083_eventDriverBrakeApply 3 "Faulty_SNA" 2 "Driver_applying_brakes" 1 "Not_Applied" 0 "NotInit_orOff" ;
VAL_ 1297 RCM_a083_eventAccelPedalPos 255 "SNA" ;
VAL_ 1297 RCM_a087_eventArmStatus 1 "ARMED" 0 "UNARMED" ;
VAL_ 1297 RCM_a087_eventFactoryMode 1 "ENABLED" 0 "DISABLED" ;
VAL_ 1297 RCM_a087_eventDiagEnabled 1 "ENABLED" 0 "DISABLED" ;
VAL_ 1297 RCM_a087_eventDriveOrientation 1 "RIGHT_HAND_DRIVE" 0 "LEFT_HAND_DRIVE" ;
VAL_ 1297 RCM_a087_eventIDFsignal 1 "ACTIVE" 0 "NOT_ACTIVE" ;
VAL_ 1297 RCM_a087_eventFrontLeftSeatbelt 1 "LATCHED" 0 "UNLATCHED" ;
VAL_ 1297 RCM_a087_eventFrontRightSeatbelt 1 "LATCHED" 0 "UNLATCHED" ;
VAL_ 1297 RCM_a087_eventDriverBrakeApply 3 "Faulty_SNA" 2 "Driver_applying_brakes" 1 "Not_Applied" 0 "NotInit_orOff" ;
VAL_ 1297 RCM_a087_eventAccelPedalPos 255 "SNA" ;
VAL_ 1297 RCM_a088_eventArmStatus 1 "ARMED" 0 "UNARMED" ;
VAL_ 1297 RCM_a088_eventFactoryMode 1 "ENABLED" 0 "DISABLED" ;
VAL_ 1297 RCM_a088_eventDiagEnabled 1 "ENABLED" 0 "DISABLED" ;
VAL_ 1297 RCM_a088_eventDriveOrientation 1 "RIGHT_HAND_DRIVE" 0 "LEFT_HAND_DRIVE" ;
VAL_ 1297 RCM_a088_eventIDFsignal 1 "ACTIVE" 0 "NOT_ACTIVE" ;
VAL_ 1297 RCM_a088_eventFrontLeftSeatbelt 1 "LATCHED" 0 "UNLATCHED" ;
VAL_ 1297 RCM_a088_eventFrontRightSeatbelt 1 "LATCHED" 0 "UNLATCHED" ;
VAL_ 1297 RCM_a088_eventDriverBrakeApply 3 "Faulty_SNA" 2 "Driver_applying_brakes" 1 "Not_Applied" 0 "NotInit_orOff" ;
VAL_ 1297 RCM_a088_eventAccelPedalPos 255 "SNA" ;
VAL_ 1297 RCM_a089_eventArmStatus 1 "ARMED" 0 "UNARMED" ;
VAL_ 1297 RCM_a089_eventFactoryMode 1 "ENABLED" 0 "DISABLED" ;
VAL_ 1297 RCM_a089_eventDiagEnabled 1 "ENABLED" 0 "DISABLED" ;
VAL_ 1297 RCM_a089_eventDriveOrientation 1 "RIGHT_HAND_DRIVE" 0 "LEFT_HAND_DRIVE" ;
VAL_ 1297 RCM_a089_eventIDFsignal 1 "ACTIVE" 0 "NOT_ACTIVE" ;
VAL_ 1297 RCM_a089_eventFrontLeftSeatbelt 1 "LATCHED" 0 "UNLATCHED" ;
VAL_ 1297 RCM_a089_eventFrontRightSeatbelt 1 "LATCHED" 0 "UNLATCHED" ;
VAL_ 1297 RCM_a089_eventDriverBrakeApply 3 "Faulty_SNA" 2 "Driver_applying_brakes" 1 "Not_Applied" 0 "NotInit_orOff" ;
VAL_ 1297 RCM_a089_eventAccelPedalPos 255 "SNA" ;
VAL_ 1297 RCM_a090_eventArmStatus 1 "ARMED" 0 "UNARMED" ;
VAL_ 1297 RCM_a090_eventFactoryMode 1 "ENABLED" 0 "DISABLED" ;
VAL_ 1297 RCM_a090_eventDiagEnabled 1 "ENABLED" 0 "DISABLED" ;
VAL_ 1297 RCM_a090_eventDriveOrientation 1 "RIGHT_HAND_DRIVE" 0 "LEFT_HAND_DRIVE" ;
VAL_ 1297 RCM_a090_eventIDFsignal 1 "ACTIVE" 0 "NOT_ACTIVE" ;
VAL_ 1297 RCM_a090_eventFrontLeftSeatbelt 1 "LATCHED" 0 "UNLATCHED" ;
VAL_ 1297 RCM_a090_eventFrontRightSeatbelt 1 "LATCHED" 0 "UNLATCHED" ;
VAL_ 1297 RCM_a090_eventDriverBrakeApply 3 "Faulty_SNA" 2 "Driver_applying_brakes" 1 "Not_Applied" 0 "NotInit_orOff" ;
VAL_ 1297 RCM_a090_eventAccelPedalPos 255 "SNA" ;
VAL_ 1297 RCM_a091_eventArmStatus 1 "ARMED" 0 "UNARMED" ;
VAL_ 1297 RCM_a091_eventFactoryMode 1 "ENABLED" 0 "DISABLED" ;
VAL_ 1297 RCM_a091_eventDiagEnabled 1 "ENABLED" 0 "DISABLED" ;
VAL_ 1297 RCM_a091_eventDriveOrientation 1 "RIGHT_HAND_DRIVE" 0 "LEFT_HAND_DRIVE" ;
VAL_ 1297 RCM_a091_eventIDFsignal 1 "ACTIVE" 0 "NOT_ACTIVE" ;
VAL_ 1297 RCM_a091_eventFrontLeftSeatbelt 1 "LATCHED" 0 "UNLATCHED" ;
VAL_ 1297 RCM_a091_eventFrontRightSeatbelt 1 "LATCHED" 0 "UNLATCHED" ;
VAL_ 1297 RCM_a091_eventDriverBrakeApply 3 "Faulty_SNA" 2 "Driver_applying_brakes" 1 "Not_Applied" 0 "NotInit_orOff" ;
VAL_ 1297 RCM_a091_eventAccelPedalPos 255 "SNA" ;
VAL_ 1297 RCM_a092_eventArmStatus 1 "ARMED" 0 "UNARMED" ;
VAL_ 1297 RCM_a092_eventFactoryMode 1 "ENABLED" 0 "DISABLED" ;
VAL_ 1297 RCM_a092_eventDiagEnabled 1 "ENABLED" 0 "DISABLED" ;
VAL_ 1297 RCM_a092_eventDriveOrientation 1 "RIGHT_HAND_DRIVE" 0 "LEFT_HAND_DRIVE" ;
VAL_ 1297 RCM_a092_eventIDFsignal 1 "ACTIVE" 0 "NOT_ACTIVE" ;
VAL_ 1297 RCM_a092_eventFrontLeftSeatbelt 1 "LATCHED" 0 "UNLATCHED" ;
VAL_ 1297 RCM_a092_eventFrontRightSeatbelt 1 "LATCHED" 0 "UNLATCHED" ;
VAL_ 1297 RCM_a092_eventDriverBrakeApply 3 "Faulty_SNA" 2 "Driver_applying_brakes" 1 "Not_Applied" 0 "NotInit_orOff" ;
VAL_ 1297 RCM_a092_eventAccelPedalPos 255 "SNA" ;
VAL_ 1297 RCM_a093_eventArmStatus 1 "ARMED" 0 "UNARMED" ;
VAL_ 1297 RCM_a093_eventFactoryMode 1 "ENABLED" 0 "DISABLED" ;
VAL_ 1297 RCM_a093_eventDiagEnabled 1 "ENABLED" 0 "DISABLED" ;
VAL_ 1297 RCM_a093_eventDriveOrientation 1 "RIGHT_HAND_DRIVE" 0 "LEFT_HAND_DRIVE" ;
VAL_ 1297 RCM_a093_eventIDFsignal 1 "ACTIVE" 0 "NOT_ACTIVE" ;
VAL_ 1297 RCM_a093_eventFrontLeftSeatbelt 1 "LATCHED" 0 "UNLATCHED" ;
VAL_ 1297 RCM_a093_eventFrontRightSeatbelt 1 "LATCHED" 0 "UNLATCHED" ;
VAL_ 1297 RCM_a093_eventDriverBrakeApply 3 "Faulty_SNA" 2 "Driver_applying_brakes" 1 "Not_Applied" 0 "NotInit_orOff" ;
VAL_ 1297 RCM_a093_eventAccelPedalPos 255 "SNA" ;
VAL_ 1297 RCM_a094_eventArmStatus 1 "ARMED" 0 "UNARMED" ;
VAL_ 1297 RCM_a094_eventFactoryMode 1 "ENABLED" 0 "DISABLED" ;
VAL_ 1297 RCM_a094_eventDiagEnabled 1 "ENABLED" 0 "DISABLED" ;
VAL_ 1297 RCM_a094_eventDriveOrientation 1 "RIGHT_HAND_DRIVE" 0 "LEFT_HAND_DRIVE" ;
VAL_ 1297 RCM_a094_eventIDFsignal 1 "ACTIVE" 0 "NOT_ACTIVE" ;
VAL_ 1297 RCM_a094_eventFrontLeftSeatbelt 1 "LATCHED" 0 "UNLATCHED" ;
VAL_ 1297 RCM_a094_eventFrontRightSeatbelt 1 "LATCHED" 0 "UNLATCHED" ;
VAL_ 1297 RCM_a094_eventDriverBrakeApply 3 "Faulty_SNA" 2 "Driver_applying_brakes" 1 "Not_Applied" 0 "NotInit_orOff" ;
VAL_ 1297 RCM_a094_eventAccelPedalPos 255 "SNA" ;
VAL_ 1297 RCM_a101_eventArmStatus 1 "ARMED" 0 "UNARMED" ;
VAL_ 1297 RCM_a101_eventFactoryMode 1 "ENABLED" 0 "DISABLED" ;
VAL_ 1297 RCM_a101_eventDiagEnabled 1 "ENABLED" 0 "DISABLED" ;
VAL_ 1297 RCM_a101_eventDriveOrientation 1 "RIGHT_HAND_DRIVE" 0 "LEFT_HAND_DRIVE" ;
VAL_ 1297 RCM_a101_eventIDFsignal 1 "ACTIVE" 0 "NOT_ACTIVE" ;
VAL_ 1297 RCM_a101_eventFrontLeftSeatbelt 1 "LATCHED" 0 "UNLATCHED" ;
VAL_ 1297 RCM_a101_eventFrontRightSeatbelt 1 "LATCHED" 0 "UNLATCHED" ;
VAL_ 1297 RCM_a101_eventDriverBrakeApply 3 "Faulty_SNA" 2 "Driver_applying_brakes" 1 "Not_Applied" 0 "NotInit_orOff" ;
VAL_ 1297 RCM_a101_eventAccelPedalPos 255 "SNA" ;
VAL_ 1297 RCM_a102_eventArmStatus 1 "ARMED" 0 "UNARMED" ;
VAL_ 1297 RCM_a102_eventFactoryMode 1 "ENABLED" 0 "DISABLED" ;
VAL_ 1297 RCM_a102_eventDiagEnabled 1 "ENABLED" 0 "DISABLED" ;
VAL_ 1297 RCM_a102_eventDriveOrientation 1 "RIGHT_HAND_DRIVE" 0 "LEFT_HAND_DRIVE" ;
VAL_ 1297 RCM_a102_eventIDFsignal 1 "ACTIVE" 0 "NOT_ACTIVE" ;
VAL_ 1297 RCM_a102_eventFrontLeftSeatbelt 1 "LATCHED" 0 "UNLATCHED" ;
VAL_ 1297 RCM_a102_eventFrontRightSeatbelt 1 "LATCHED" 0 "UNLATCHED" ;
VAL_ 1297 RCM_a102_eventDriverBrakeApply 3 "Faulty_SNA" 2 "Driver_applying_brakes" 1 "Not_Applied" 0 "NotInit_orOff" ;
VAL_ 1297 RCM_a102_eventAccelPedalPos 255 "SNA" ;
VAL_ 1297 RCM_a103_eventArmStatus 1 "ARMED" 0 "UNARMED" ;
VAL_ 1297 RCM_a103_eventFactoryMode 1 "ENABLED" 0 "DISABLED" ;
VAL_ 1297 RCM_a103_eventDiagEnabled 1 "ENABLED" 0 "DISABLED" ;
VAL_ 1297 RCM_a103_eventDriveOrientation 1 "RIGHT_HAND_DRIVE" 0 "LEFT_HAND_DRIVE" ;
VAL_ 1297 RCM_a103_eventIDFsignal 1 "ACTIVE" 0 "NOT_ACTIVE" ;
VAL_ 1297 RCM_a103_eventFrontLeftSeatbelt 1 "LATCHED" 0 "UNLATCHED" ;
VAL_ 1297 RCM_a103_eventFrontRightSeatbelt 1 "LATCHED" 0 "UNLATCHED" ;
VAL_ 1297 RCM_a103_eventDriverBrakeApply 3 "Faulty_SNA" 2 "Driver_applying_brakes" 1 "Not_Applied" 0 "NotInit_orOff" ;
VAL_ 1297 RCM_a103_eventAccelPedalPos 255 "SNA" ;
VAL_ 1297 RCM_a104_eventArmStatus 1 "ARMED" 0 "UNARMED" ;
VAL_ 1297 RCM_a104_eventFactoryMode 1 "ENABLED" 0 "DISABLED" ;
VAL_ 1297 RCM_a104_eventDiagEnabled 1 "ENABLED" 0 "DISABLED" ;
VAL_ 1297 RCM_a104_eventDriveOrientation 1 "RIGHT_HAND_DRIVE" 0 "LEFT_HAND_DRIVE" ;
VAL_ 1297 RCM_a104_eventIDFsignal 1 "ACTIVE" 0 "NOT_ACTIVE" ;
VAL_ 1297 RCM_a104_eventFrontLeftSeatbelt 1 "LATCHED" 0 "UNLATCHED" ;
VAL_ 1297 RCM_a104_eventFrontRightSeatbelt 1 "LATCHED" 0 "UNLATCHED" ;
VAL_ 1297 RCM_a104_eventDriverBrakeApply 3 "Faulty_SNA" 2 "Driver_applying_brakes" 1 "Not_Applied" 0 "NotInit_orOff" ;
VAL_ 1297 RCM_a104_eventAccelPedalPos 255 "SNA" ;
VAL_ 1297 RCM_a105_eventArmStatus 1 "ARMED" 0 "UNARMED" ;
VAL_ 1297 RCM_a105_eventFactoryMode 1 "ENABLED" 0 "DISABLED" ;
VAL_ 1297 RCM_a105_eventDiagEnabled 1 "ENABLED" 0 "DISABLED" ;
VAL_ 1297 RCM_a105_eventDriveOrientation 1 "RIGHT_HAND_DRIVE" 0 "LEFT_HAND_DRIVE" ;
VAL_ 1297 RCM_a105_eventIDFsignal 1 "ACTIVE" 0 "NOT_ACTIVE" ;
VAL_ 1297 RCM_a105_eventFrontLeftSeatbelt 1 "LATCHED" 0 "UNLATCHED" ;
VAL_ 1297 RCM_a105_eventFrontRightSeatbelt 1 "LATCHED" 0 "UNLATCHED" ;
VAL_ 1297 RCM_a105_eventDriverBrakeApply 3 "Faulty_SNA" 2 "Driver_applying_brakes" 1 "Not_Applied" 0 "NotInit_orOff" ;
VAL_ 1297 RCM_a105_eventAccelPedalPos 255 "SNA" ;
VAL_ 1297 RCM_a106_eventArmStatus 1 "ARMED" 0 "UNARMED" ;
VAL_ 1297 RCM_a106_eventFactoryMode 1 "ENABLED" 0 "DISABLED" ;
VAL_ 1297 RCM_a106_eventDiagEnabled 1 "ENABLED" 0 "DISABLED" ;
VAL_ 1297 RCM_a106_eventDriveOrientation 1 "RIGHT_HAND_DRIVE" 0 "LEFT_HAND_DRIVE" ;
VAL_ 1297 RCM_a106_eventIDFsignal 1 "ACTIVE" 0 "NOT_ACTIVE" ;
VAL_ 1297 RCM_a106_eventFrontLeftSeatbelt 1 "LATCHED" 0 "UNLATCHED" ;
VAL_ 1297 RCM_a106_eventFrontRightSeatbelt 1 "LATCHED" 0 "UNLATCHED" ;
VAL_ 1297 RCM_a106_eventDriverBrakeApply 3 "Faulty_SNA" 2 "Driver_applying_brakes" 1 "Not_Applied" 0 "NotInit_orOff" ;
VAL_ 1297 RCM_a106_eventAccelPedalPos 255 "SNA" ;
VAL_ 1297 RCM_a107_eventArmStatus 1 "ARMED" 0 "UNARMED" ;
VAL_ 1297 RCM_a107_eventFactoryMode 1 "ENABLED" 0 "DISABLED" ;
VAL_ 1297 RCM_a107_eventDiagEnabled 1 "ENABLED" 0 "DISABLED" ;
VAL_ 1297 RCM_a107_eventDriveOrientation 1 "RIGHT_HAND_DRIVE" 0 "LEFT_HAND_DRIVE" ;
VAL_ 1297 RCM_a107_eventIDFsignal 1 "ACTIVE" 0 "NOT_ACTIVE" ;
VAL_ 1297 RCM_a107_eventFrontLeftSeatbelt 1 "LATCHED" 0 "UNLATCHED" ;
VAL_ 1297 RCM_a107_eventFrontRightSeatbelt 1 "LATCHED" 0 "UNLATCHED" ;
VAL_ 1297 RCM_a107_eventDriverBrakeApply 3 "Faulty_SNA" 2 "Driver_applying_brakes" 1 "Not_Applied" 0 "NotInit_orOff" ;
VAL_ 1297 RCM_a107_eventAccelPedalPos 255 "SNA" ;
VAL_ 1297 RCM_a108_eventArmStatus 1 "ARMED" 0 "UNARMED" ;
VAL_ 1297 RCM_a108_eventFactoryMode 1 "ENABLED" 0 "DISABLED" ;
VAL_ 1297 RCM_a108_eventDiagEnabled 1 "ENABLED" 0 "DISABLED" ;
VAL_ 1297 RCM_a108_eventDriveOrientation 1 "RIGHT_HAND_DRIVE" 0 "LEFT_HAND_DRIVE" ;
VAL_ 1297 RCM_a108_eventIDFsignal 1 "ACTIVE" 0 "NOT_ACTIVE" ;
VAL_ 1297 RCM_a108_eventFrontLeftSeatbelt 1 "LATCHED" 0 "UNLATCHED" ;
VAL_ 1297 RCM_a108_eventFrontRightSeatbelt 1 "LATCHED" 0 "UNLATCHED" ;
VAL_ 1297 RCM_a108_eventDriverBrakeApply 3 "Faulty_SNA" 2 "Driver_applying_brakes" 1 "Not_Applied" 0 "NotInit_orOff" ;
VAL_ 1297 RCM_a108_eventAccelPedalPos 255 "SNA" ;
VAL_ 1297 RCM_a109_eventArmStatus 1 "ARMED" 0 "UNARMED" ;
VAL_ 1297 RCM_a109_eventFactoryMode 1 "ENABLED" 0 "DISABLED" ;
VAL_ 1297 RCM_a109_eventDiagEnabled 1 "ENABLED" 0 "DISABLED" ;
VAL_ 1297 RCM_a109_eventDriveOrientation 1 "RIGHT_HAND_DRIVE" 0 "LEFT_HAND_DRIVE" ;
VAL_ 1297 RCM_a109_eventIDFsignal 1 "ACTIVE" 0 "NOT_ACTIVE" ;
VAL_ 1297 RCM_a109_eventFrontLeftSeatbelt 1 "LATCHED" 0 "UNLATCHED" ;
VAL_ 1297 RCM_a109_eventFrontRightSeatbelt 1 "LATCHED" 0 "UNLATCHED" ;
VAL_ 1297 RCM_a109_eventDriverBrakeApply 3 "Faulty_SNA" 2 "Driver_applying_brakes" 1 "Not_Applied" 0 "NotInit_orOff" ;
VAL_ 1297 RCM_a109_eventAccelPedalPos 255 "SNA" ;
VAL_ 1297 RCM_a110_eventArmStatus 1 "ARMED" 0 "UNARMED" ;
VAL_ 1297 RCM_a110_eventFactoryMode 1 "ENABLED" 0 "DISABLED" ;
VAL_ 1297 RCM_a110_eventDiagEnabled 1 "ENABLED" 0 "DISABLED" ;
VAL_ 1297 RCM_a110_eventDriveOrientation 1 "RIGHT_HAND_DRIVE" 0 "LEFT_HAND_DRIVE" ;
VAL_ 1297 RCM_a110_eventIDFsignal 1 "ACTIVE" 0 "NOT_ACTIVE" ;
VAL_ 1297 RCM_a110_eventFrontLeftSeatbelt 1 "LATCHED" 0 "UNLATCHED" ;
VAL_ 1297 RCM_a110_eventFrontRightSeatbelt 1 "LATCHED" 0 "UNLATCHED" ;
VAL_ 1297 RCM_a110_eventDriverBrakeApply 3 "Faulty_SNA" 2 "Driver_applying_brakes" 1 "Not_Applied" 0 "NotInit_orOff" ;
VAL_ 1297 RCM_a110_eventAccelPedalPos 255 "SNA" ;
VAL_ 1297 RCM_a112_eventArmStatus 1 "ARMED" 0 "UNARMED" ;
VAL_ 1297 RCM_a112_eventFactoryMode 1 "ENABLED" 0 "DISABLED" ;
VAL_ 1297 RCM_a112_eventDiagEnabled 1 "ENABLED" 0 "DISABLED" ;
VAL_ 1297 RCM_a112_eventDriveOrientation 1 "RIGHT_HAND_DRIVE" 0 "LEFT_HAND_DRIVE" ;
VAL_ 1297 RCM_a112_eventIDFsignal 1 "ACTIVE" 0 "NOT_ACTIVE" ;
VAL_ 1297 RCM_a112_eventFrontLeftSeatbelt 1 "LATCHED" 0 "UNLATCHED" ;
VAL_ 1297 RCM_a112_eventFrontRightSeatbelt 1 "LATCHED" 0 "UNLATCHED" ;
VAL_ 1297 RCM_a112_eventDriverBrakeApply 3 "Faulty_SNA" 2 "Driver_applying_brakes" 1 "Not_Applied" 0 "NotInit_orOff" ;
VAL_ 1297 RCM_a112_eventAccelPedalPos 255 "SNA" ;
VAL_ 1297 RCM_a113_eventArmStatus 1 "ARMED" 0 "UNARMED" ;
VAL_ 1297 RCM_a113_eventFactoryMode 1 "ENABLED" 0 "DISABLED" ;
VAL_ 1297 RCM_a113_eventDiagEnabled 1 "ENABLED" 0 "DISABLED" ;
VAL_ 1297 RCM_a113_eventDriveOrientation 1 "RIGHT_HAND_DRIVE" 0 "LEFT_HAND_DRIVE" ;
VAL_ 1297 RCM_a113_eventIDFsignal 1 "ACTIVE" 0 "NOT_ACTIVE" ;
VAL_ 1297 RCM_a113_eventFrontLeftSeatbelt 1 "LATCHED" 0 "UNLATCHED" ;
VAL_ 1297 RCM_a113_eventFrontRightSeatbelt 1 "LATCHED" 0 "UNLATCHED" ;
VAL_ 1297 RCM_a113_eventDriverBrakeApply 3 "Faulty_SNA" 2 "Driver_applying_brakes" 1 "Not_Applied" 0 "NotInit_orOff" ;
VAL_ 1297 RCM_a113_eventAccelPedalPos 255 "SNA" ;
VAL_ 1297 RCM_a114_eventArmStatus 1 "ARMED" 0 "UNARMED" ;
VAL_ 1297 RCM_a114_eventFactoryMode 1 "ENABLED" 0 "DISABLED" ;
VAL_ 1297 RCM_a114_eventDiagEnabled 1 "ENABLED" 0 "DISABLED" ;
VAL_ 1297 RCM_a114_eventDriveOrientation 1 "RIGHT_HAND_DRIVE" 0 "LEFT_HAND_DRIVE" ;
VAL_ 1297 RCM_a114_eventIDFsignal 1 "ACTIVE" 0 "NOT_ACTIVE" ;
VAL_ 1297 RCM_a114_eventFrontLeftSeatbelt 1 "LATCHED" 0 "UNLATCHED" ;
VAL_ 1297 RCM_a114_eventFrontRightSeatbelt 1 "LATCHED" 0 "UNLATCHED" ;
VAL_ 1297 RCM_a114_eventDriverBrakeApply 3 "Faulty_SNA" 2 "Driver_applying_brakes" 1 "Not_Applied" 0 "NotInit_orOff" ;
VAL_ 1297 RCM_a114_eventAccelPedalPos 255 "SNA" ;
VAL_ 1297 RCM_a115_eventArmStatus 1 "ARMED" 0 "UNARMED" ;
VAL_ 1297 RCM_a115_eventFactoryMode 1 "ENABLED" 0 "DISABLED" ;
VAL_ 1297 RCM_a115_eventDiagEnabled 1 "ENABLED" 0 "DISABLED" ;
VAL_ 1297 RCM_a115_eventDriveOrientation 1 "RIGHT_HAND_DRIVE" 0 "LEFT_HAND_DRIVE" ;
VAL_ 1297 RCM_a115_eventIDFsignal 1 "ACTIVE" 0 "NOT_ACTIVE" ;
VAL_ 1297 RCM_a115_eventFrontLeftSeatbelt 1 "LATCHED" 0 "UNLATCHED" ;
VAL_ 1297 RCM_a115_eventFrontRightSeatbelt 1 "LATCHED" 0 "UNLATCHED" ;
VAL_ 1297 RCM_a115_eventDriverBrakeApply 3 "Faulty_SNA" 2 "Driver_applying_brakes" 1 "Not_Applied" 0 "NotInit_orOff" ;
VAL_ 1297 RCM_a115_eventAccelPedalPos 255 "SNA" ;
VAL_ 1297 RCM_a116_eventArmStatus 1 "ARMED" 0 "UNARMED" ;
VAL_ 1297 RCM_a116_eventFactoryMode 1 "ENABLED" 0 "DISABLED" ;
VAL_ 1297 RCM_a116_eventDiagEnabled 1 "ENABLED" 0 "DISABLED" ;
VAL_ 1297 RCM_a116_eventDriveOrientation 1 "RIGHT_HAND_DRIVE" 0 "LEFT_HAND_DRIVE" ;
VAL_ 1297 RCM_a116_eventIDFsignal 1 "ACTIVE" 0 "NOT_ACTIVE" ;
VAL_ 1297 RCM_a116_eventFrontLeftSeatbelt 1 "LATCHED" 0 "UNLATCHED" ;
VAL_ 1297 RCM_a116_eventFrontRightSeatbelt 1 "LATCHED" 0 "UNLATCHED" ;
VAL_ 1297 RCM_a116_eventDriverBrakeApply 3 "Faulty_SNA" 2 "Driver_applying_brakes" 1 "Not_Applied" 0 "NotInit_orOff" ;
VAL_ 1297 RCM_a116_eventAccelPedalPos 255 "SNA" ;
VAL_ 1297 RCM_a117_eventArmStatus 1 "ARMED" 0 "UNARMED" ;
VAL_ 1297 RCM_a117_eventFactoryMode 1 "ENABLED" 0 "DISABLED" ;
VAL_ 1297 RCM_a117_eventDiagEnabled 1 "ENABLED" 0 "DISABLED" ;
VAL_ 1297 RCM_a117_eventDriveOrientation 1 "RIGHT_HAND_DRIVE" 0 "LEFT_HAND_DRIVE" ;
VAL_ 1297 RCM_a117_eventIDFsignal 1 "ACTIVE" 0 "NOT_ACTIVE" ;
VAL_ 1297 RCM_a117_eventFrontLeftSeatbelt 1 "LATCHED" 0 "UNLATCHED" ;
VAL_ 1297 RCM_a117_eventFrontRightSeatbelt 1 "LATCHED" 0 "UNLATCHED" ;
VAL_ 1297 RCM_a117_eventDriverBrakeApply 3 "Faulty_SNA" 2 "Driver_applying_brakes" 1 "Not_Applied" 0 "NotInit_orOff" ;
VAL_ 1297 RCM_a117_eventAccelPedalPos 255 "SNA" ;
VAL_ 1297 RCM_a118_eventArmStatus 1 "ARMED" 0 "UNARMED" ;
VAL_ 1297 RCM_a118_eventFactoryMode 1 "ENABLED" 0 "DISABLED" ;
VAL_ 1297 RCM_a118_eventDiagEnabled 1 "ENABLED" 0 "DISABLED" ;
VAL_ 1297 RCM_a118_eventDriveOrientation 1 "RIGHT_HAND_DRIVE" 0 "LEFT_HAND_DRIVE" ;
VAL_ 1297 RCM_a118_eventIDFsignal 1 "ACTIVE" 0 "NOT_ACTIVE" ;
VAL_ 1297 RCM_a118_eventFrontLeftSeatbelt 1 "LATCHED" 0 "UNLATCHED" ;
VAL_ 1297 RCM_a118_eventFrontRightSeatbelt 1 "LATCHED" 0 "UNLATCHED" ;
VAL_ 1297 RCM_a118_eventDriverBrakeApply 3 "Faulty_SNA" 2 "Driver_applying_brakes" 1 "Not_Applied" 0 "NotInit_orOff" ;
VAL_ 1297 RCM_a118_eventAccelPedalPos 255 "SNA" ;
VAL_ 881 RCM_matrixIndex 1 "AlertMatrix1" 0 "AlertMatrix0" ;
VAL_ 17 RCM_collisionRear 3 "RCM_COLLISION_EVENT_SNA" 1 "RCM_COLLISION_EVENT_ACTIVE" 0 "RCM_COLLISION_EVENT_INACTIVE" ;
VAL_ 17 RCM_collisionRight 3 "RCM_COLLISION_EVENT_SNA" 1 "RCM_COLLISION_EVENT_ACTIVE" 0 "RCM_COLLISION_EVENT_INACTIVE" ;
VAL_ 17 RCM_collisionLeft 3 "RCM_COLLISION_EVENT_SNA" 1 "RCM_COLLISION_EVENT_ACTIVE" 0 "RCM_COLLISION_EVENT_INACTIVE" ;
VAL_ 17 RCM_collisionFront 3 "RCM_COLLISION_EVENT_SNA" 1 "RCM_COLLISION_EVENT_ACTIVE" 0 "RCM_COLLISION_EVENT_INACTIVE" ;
VAL_ 17 RCM_collisionRollover 3 "RCM_COLLISION_EVENT_SNA" 1 "RCM_COLLISION_EVENT_ACTIVE" 0 "RCM_COLLISION_EVENT_INACTIVE" ;
VAL_ 17 RCM_collisionPedPro 3 "RCM_COLLISION_EVENT_SNA" 1 "RCM_COLLISION_EVENT_ACTIVE" 0 "RCM_COLLISION_EVENT_INACTIVE" ;
VAL_ 17 RCM_collisionSeverity 3 "RCM_COLLISION_SEVERITY_PEDPRO_EVENT" 2 "RCM_COLLISION_SEVERITY_SECOND_STAGE" 1 "RCM_COLLISION_SEVERITY_FIRST_STAGE" 0 "RCM_COLLISION_SEVERITY_PRETENSIONER" ;
VAL_ 257 RCM_yawRate -32768 "SNA" ;
VAL_ 257 RCM_pitchRate -16384 "SNA" ;
VAL_ 257 RCM_rollRate -16384 "SNA" ;
VAL_ 257 RCM_rollRateQF 3 "FAULTED" 2 "TEMP_INVALID" 1 "VALID" 0 "INIT" ;
VAL_ 257 RCM_yawRateQF 1 "NOT_FAULTED" 0 "FAULTED" ;
VAL_ 257 RCM_pitchRateQF 3 "FAULTED" 2 "TEMP_INVALID" 1 "VALID" 0 "INIT" ;
VAL_ 278 RCM_longitudinalAccel -32768 "SNA" ;
VAL_ 278 RCM_lateralAccel -32768 "SNA" ;
VAL_ 278 RCM_verticalAccel -32768 "SNA" ;
VAL_ 278 RCM_longitudinalAccelQF 1 "NOT_FAULTED" 0 "FAULTED" ;
VAL_ 278 RCM_lateralAccelQF 1 "NOT_FAULTED" 0 "FAULTED" ;
VAL_ 278 RCM_verticalAccelQF 1 "NOT_FAULTED" 0 "FAULTED" ;
VAL_ 278 RCM_CGTranslationFault 1 "RCM_COG_TRANSLATION_FAULTED" 0 "RCM_COG_TRANSLATION_NOT_FAULTED" ;
VAL_ 849 RCM_infoIndex 255 "END" 31 "SUBCOMPONENT_GITHASH" 30 "PACKAGE_SN_8_14" 29 "PACKAGE_SN_1_7" 27 "PACKAGE_PN_15_20" 26 "PACKAGE_PN_8_14" 25 "PACKAGE_PN_1_7" 23 "SUBCOMPONENT2" 22 "VARIANTCRC" 20 "UDS_PROTOCOL_BOOTCRC" 19 "VERSION_DEPRECATED" 18 "BOOTLOADER_GITHASH" 17 "APP_GITHASH" 16 "SUBCOMPONENT" 15 "BOOTLOADER_CRC" 14 "BOOTLOADER_SVN" 13 "APP_CRC" 11 "PCBAID_ASSYID_USAGEID" 10 "BUILD_HWID_COMPONENTID" 9 "DEPRECATED_9" 8 "DEPRECATED_8" 7 "DEPRECATED_7" 6 "DEPRECATED_6" 5 "DEPRECATED_5" 4 "DEPRECATED_4" 3 "DEPRECATED_3" 2 "DEPRECATED_2" 1 "DEPRECATED_1" 0 "DEPRECATED_0" ;
VAL_ 849 RCM_infoBuildType 4 "INFO_MFG_BUILD" 3 "INFO_TRACEABLE_CI_BUILD" 2 "INFO_LOCAL_BUILD" 1 "INFO_PLATFORM_BUILD" 0 "INFO_UNKNOWN_BUILD" ;
VAL_ 2032 RCM_nearDeployRear 3 "RCM_NEAR_DEPLOY_EVENT_SNA" 1 "RCM_NEAR_DEPLOY_EVENT_ACTIVE" 0 "RCM_NEAR_DEPLOY_EVENT_INACTIVE" ;
VAL_ 2032 RCM_nearDeployRight 3 "RCM_NEAR_DEPLOY_EVENT_SNA" 1 "RCM_NEAR_DEPLOY_EVENT_ACTIVE" 0 "RCM_NEAR_DEPLOY_EVENT_INACTIVE" ;
VAL_ 2032 RCM_nearDeployLeft 3 "RCM_NEAR_DEPLOY_EVENT_SNA" 1 "RCM_NEAR_DEPLOY_EVENT_ACTIVE" 0 "RCM_NEAR_DEPLOY_EVENT_INACTIVE" ;
VAL_ 2032 RCM_nearDeployFront 3 "RCM_NEAR_DEPLOY_EVENT_SNA" 1 "RCM_NEAR_DEPLOY_EVENT_ACTIVE" 0 "RCM_NEAR_DEPLOY_EVENT_INACTIVE" ;
VAL_ 2032 RCM_nearDeployRollover 3 "RCM_NEAR_DEPLOY_EVENT_SNA" 1 "RCM_NEAR_DEPLOY_EVENT_ACTIVE" 0 "RCM_NEAR_DEPLOY_EVENT_INACTIVE" ;
VAL_ 2032 RCM_crashAlgoWakeup 3 "RCM_CRASH_ALGO_WAKEUP_EVENT_SNA" 1 "RCM_CRASH_ALGO_WAKEUP_EVENT_ACTIVE" 0 "RCM_CRASH_ALGO_WAKEUP_EVENT_INACTIVE" ;
VAL_ 529 RCM_armStatus 3 "SNA" 2 "ARMED_WITH_NOFIRE_CAL" 1 "RCM_ARMED" 0 "RCM_UNARMED" ;
VAL_ 529 RCM_warningIndicatorState 3 "SNA" 1 "RCM_WARNING_INDICATOR_ON" 0 "RCM_WARNING_INDICATOR_OFF" ;
VAL_ 529 RCM_passAirbagIndicatorRequest 3 "SNA" 1 "RCM_PASSENGER_AIRBAG_INDICATOR_OFF" 0 "RCM_PASSENGER_AIRBAG_INDICATOR_ON" ;
VAL_ 529 RCM_airbagCutoffStatus 3 "SNA" 1 "RCM_PASSENGER_AIRBAG_DISABLED" 0 "RCM_PASSENGER_AIRBAG_ENABLED" ;
VAL_ 529 RCM_alrSwitchStatus 3 "SNA" 2 "RCM_ALR_FAULTED" 1 "RCM_ALR_ENGAGED" 0 "RCM_ALR_NOT_ENGAGED" ;
VAL_ 529 RCM_vinLearnFlag 3 "SNA" 2 "RCM_VIN_STORED_MISMATCH" 1 "RCM_VIN_STORED" 0 "RCM_VIN_NOT_STORED" ;
VAL_ 529 RCM_seatTrackPositionDrvr 3 "SNA" 2 "RCM_SEAT_POSITION_FAULTED" 1 "RCM_SEAT_POSITION_FAR" 0 "RCM_SEAT_POSITION_NEAR" ;
VAL_ 529 RCM_seatTrackPositionPass 3 "SNA" 2 "RCM_SEAT_POSITION_FAULTED" 1 "RCM_SEAT_POSITION_FAR" 0 "RCM_SEAT_POSITION_NEAR" ;
VAL_ 529 RCM_edr1State 3 "RCM_EDR_UNAVAILABLE" 2 "RCM_EDR_LOCKED" 1 "RCM_EDR_STORED" 0 "RCM_EDR_EMPTY" ;
VAL_ 529 RCM_edr2State 3 "RCM_EDR_UNAVAILABLE" 2 "RCM_EDR_LOCKED" 1 "RCM_EDR_STORED" 0 "RCM_EDR_EMPTY" ;
VAL_ 529 RCM_keepPowerReason 8 "RCM_KEEP_POWER_REASON_SNA" 7 "RCM_INVALID_POWER_OFF_REQUEST" 6 "RCM_INITIALIZATION_PHASE" 5 "RCM_CANNOT_POWER_DOWN" 4 "RCM_EDR_UPLOADING" 3 "RCM_EDR_STORING_TO_EEPROM" 2 "RCM_CRASH_ALGO_ACTIVE" 1 "RCM_IN_IDLE_MODE" 0 "RCM_NO_KEEP_POWER_REQUEST" ;
VAL_ 529 RCM_imuOffsetLearnState 3 "IMU_OFFSETS_UNABLE_TO_LEARN" 2 "IMU_FAST_LEARNING_TIME" 1 "IMU_SLOW_LEARNING_DISTANCE" 0 "IMU_OFFSET_LEARNING_OFF" ;
VAL_ 529 RCM_edr3State 3 "RCM_EDR_UNAVAILABLE" 2 "RCM_EDR_LOCKED" 1 "RCM_EDR_STORED" 0 "RCM_EDR_EMPTY" ;
VAL_ 529 RCM_driverOrientationInitStatus 7 "SNA" 4 "RCM_DRIVER_ORIENTATION_MISMATCH_DEFAULT_RHD" 3 "RCM_DRIVER_ORIENTATION_MISMATCH_DEFAULT_LHD" 2 "RCM_DRIVER_ORIENTATION_MATCHED_RHD" 1 "RCM_DRIVER_ORIENTATION_MATCHED_LHD" 0 "RCM_DRIVER_ORIENTATION_INIT_NOT_COMPLETE" ;
VAL_ 529 RCM_occupantClassificationSource 1 "VCRIGHT_CLASSIFICATION_SOURCE" 0 "OCS1P_CLASSIFICATION_SOURCE" ;
VAL_ 529 RCM_pedProEDR1State 3 "RCM_EDR_UNAVAILABLE" 2 "RCM_EDR_LOCKED" 1 "RCM_EDR_STORED" 0 "RCM_EDR_EMPTY" ;
VAL_ 529 RCM_pedProEDR2State 3 "RCM_EDR_UNAVAILABLE" 2 "RCM_EDR_LOCKED" 1 "RCM_EDR_STORED" 0 "RCM_EDR_EMPTY" ;
VAL_ 1471 RCU_alertID 58 "a058_DIbrakeTorqueCommandAndFlagMismatch" 57 "a057_PMebrCmdStateInvalid" 56 "a056_redundantControllerIsMaster" 55 "a055_IDBsimulatorPressFaulted" 54 "a054_IDBcircuitPressFaulted" 53 "a053_ESPwheelSpeedsChecksum" 52 "a052_ESPwheelSpeedsCounter" 51 "a051_ESPReRWSSLInvalid" 50 "a050_ESPReLWSSLInvalid" 49 "a049_ESPFrRWSSLInvalid" 48 "a048_ESPFrLWSSLInvalid" 47 "a047_ESPwheelSpeedsDLC" 46 "a046_brakeFluidLevelSNA" 45 "a045_VCFRONTtempInvalid" 44 "a044_VCFRONTsensorsMIA" 43 "a043_VCFRONTiBoosterLvStateInvalid" 42 "a042_DIsystemStatusChecksum" 41 "a041_DIsystemStatusCounter" 40 "a040_DIgearInvalid" 39 "a039_DIaccelPosInvalid" 38 "a038_DIsystemStatusDLC" 37 "a037_IDBinputRodStrokeInvalid" 36 "a036_IDBpspInvalid" 35 "a035_IDBpcpInvalid" 34 "a034_VCFRONTLVPowerStateCounter" 33 "a033_VCFRONTLVPowerStateChecksum" 32 "a032_VCFRONTLVPowerStateDLC" 31 "a031_PMstate2Counter" 30 "a030_PMstate2Checksum" 29 "a029_PMstate2DLC" 28 "a028_DIchassisControlCounter" 27 "a027_DIchassisCtrlChecksum" 26 "a026_DIchassisControlDLC" 25 "a025_IDBstatusCounter" 24 "a024_IDBstatusChecksum" 23 "a023_IDBstatusDLC" 22 "a022_BBstatusCounter" 21 "a021_BBstatusChecksum" 20 "a020_BBstatusDLC" 19 "a019_DItorquePathActive" 18 "a018_DItorquePathFaulted" 17 "a017_chassisBusOff" 16 "a016_partyBusOff" 15 "a015_fluidLeakDetected" 14 "a014_asicTempHigh" 13 "a013_mcuGenericFault" 12 "a012_pedalSensorNotCal" 11 "a011_idbPedalTravelMismatch" 10 "a010_pedalSensorFault" 9 "a009_brakeFluidLow" 8 "a008_pressureNotCalibrated" 7 "a007_pressureSensorFault" 6 "a006_wakeLineOpen" 5 "a005_supplyUndervoltage" 4 "a004_supplyOvervoltage" 3 "a003_pumpMotorFault" 2 "a002_solenoidValveFault" 1 "a001_valveDriverFault" 0 "ALERT_DO_NOT_USE_ZERO" ;
VAL_ 1471 RCU_alertState 1 "SET" 0 "CLEARED" ;
VAL_ 1471 RCU_a010_sensorPowerSupply 1 "NOT_OK" 0 "OK" ;
VAL_ 1471 RCU_a010_sensorHardware 1 "NOT_OK" 0 "OK" ;
VAL_ 1471 RCU_a010_sensorSignal 1 "NOT_OK" 0 "OK" ;
VAL_ 1471 RCU_a023_validityOnChassisBus 1 "NOT_OK" 0 "OK" ;
VAL_ 1471 RCU_a023_validityOnPartyBus 1 "NOT_OK" 0 "OK" ;
VAL_ 1471 RCU_a024_validityOnChassisBus 1 "NOT_OK" 0 "OK" ;
VAL_ 1471 RCU_a024_validityOnPartyBus 1 "NOT_OK" 0 "OK" ;
VAL_ 1471 RCU_a025_validityOnChassisBus 1 "NOT_OK" 0 "OK" ;
VAL_ 1471 RCU_a025_validityOnPartyBus 1 "NOT_OK" 0 "OK" ;
VAL_ 1471 RCU_a035_validityOnChassisBus 1 "NOT_OK" 0 "OK" ;
VAL_ 1471 RCU_a035_validityOnPartyBus 1 "NOT_OK" 0 "OK" ;
VAL_ 1471 RCU_a036_validityOnChassisBus 1 "NOT_OK" 0 "OK" ;
VAL_ 1471 RCU_a036_validityOnPartyBus 1 "NOT_OK" 0 "OK" ;
